VERSION ""

NS_ :

BS_:

BU_: TIMServer TIMClient

BO_ 2619670270 TIM21: 16 Vector__XXX
 SG_ RequestCounterAuxValve32 m32 : 8|4@1+ (1,0) [0|0] "" Vector__XXX
 SG_ RequestCounterAuxValve31 m31 : 8|4@1+ (1,0) [0|0] "" Vector__XXX
 SG_ RequestCounterAuxValve30 m30 : 8|4@1+ (1,0) [0|0] "" Vector__XXX
 SG_ RequestCounterAuxValve29 m29 : 8|4@1+ (1,0) [0|0] "" Vector__XXX
 SG_ RequestCounterAuxValve28 m28 : 8|4@1+ (1,0) [0|0] "" Vector__XXX
 SG_ RequestCounterAuxValve27 m27 : 8|4@1+ (1,0) [0|0] "" Vector__XXX
 SG_ RequestCounterAuxValve26 m26 : 8|4@1+ (1,0) [0|0] "" Vector__XXX
 SG_ RequestCounterAuxValve25 m25 : 8|4@1+ (1,0) [0|0] "" Vector__XXX
 SG_ RequestCounterAuxValve24 m24 : 8|4@1+ (1,0) [0|0] "" Vector__XXX
 SG_ RequestCounterAuxValve23 m23 : 8|4@1+ (1,0) [0|0] "" Vector__XXX
 SG_ RequestCounterAuxValve22 m22 : 8|4@1+ (1,0) [0|0] "" Vector__XXX
 SG_ RequestCounterAuxValve21 m21 : 8|4@1+ (1,0) [0|0] "" Vector__XXX
 SG_ RequestCounterAuxValve20 m20 : 8|4@1+ (1,0) [0|0] "" Vector__XXX
 SG_ RequestCounterAuxValve19 m19 : 8|4@1+ (1,0) [0|0] "" Vector__XXX
 SG_ RequestCounterAuxValve18 m18 : 8|4@1+ (1,0) [0|0] "" Vector__XXX
 SG_ RequestCounterAuxValve17 m17 : 8|4@1+ (1,0) [0|0] "" Vector__XXX
 SG_ RequestCounterAuxValve16 m16 : 8|4@1+ (1,0) [0|0] "" Vector__XXX
 SG_ RequestCounterAuxValve15 m15 : 8|4@1+ (1,0) [0|0] "" Vector__XXX
 SG_ RequestCounterAuxValve14 m14 : 8|4@1+ (1,0) [0|0] "" Vector__XXX
 SG_ RequestCounterAuxValve13 m13 : 8|4@1+ (1,0) [0|0] "" Vector__XXX
 SG_ RequestCounterAuxValve12 m12 : 8|4@1+ (1,0) [0|0] "" Vector__XXX
 SG_ RequestCounterAuxValve11 m11 : 8|4@1+ (1,0) [0|0] "" Vector__XXX
 SG_ RequestCounterAuxValve10 m10 : 8|4@1+ (1,0) [0|0] "" Vector__XXX
 SG_ RequestCounterAuxValve09 m9 : 8|4@1+ (1,0) [0|0] "" Vector__XXX
 SG_ RequestCounterAuxValve08 m8 : 8|4@1+ (1,0) [0|0] "" Vector__XXX
 SG_ RequestCounterAuxValve07 m7 : 8|4@1+ (1,0) [0|0] "" Vector__XXX
 SG_ RequestCounterAuxValve06 m6 : 8|4@1+ (1,0) [0|0] "" Vector__XXX
 SG_ RequestCounterAuxValve05 m5 : 8|4@1+ (1,0) [0|0] "" Vector__XXX
 SG_ RequestCounterAuxValve04 m4 : 8|4@1+ (1,0) [0|0] "" Vector__XXX
 SG_ RequestCounterAuxValve03 m3 : 8|4@1+ (1,0) [0|0] "" Vector__XXX
 SG_ RequestCounterAuxValve02 m2 : 8|4@1+ (1,0) [0|0] "" Vector__XXX
 SG_ RequestCounterAuxValve01 m1 : 8|4@1+ (1,0) [0|0] "" Vector__XXX
 SG_ RequestCounterVehicleSpeed m68 : 8|4@1+ (1,0) [0|0] "" Vector__XXX
 SG_ RequestCounterRearHitch m67 : 8|4@1+ (1,0) [0|0] "" Vector__XXX
 SG_ RequestCounterFrontHitch m66 : 8|4@1+ (1,0) [0|0] "" Vector__XXX
 SG_ RequestCounterRearPTO m65 : 8|4@1+ (1,0) [0|0] "" Vector__XXX
 SG_ RequestCounterFrontPTO m64 : 8|4@1+ (1,0) [0|0] "" Vector__XXX
 SG_ RequestCounterExternalGuidance m70 : 8|4@1+ (1,0) [0|0] "" Vector__XXX
 SG_ FlowRequest_AV32 m32 : 32|16@1+ (0.004,-128.512) [0|0] "%" Vector__XXX
 SG_ FlowRequest_AV31 m31 : 32|16@1+ (0.004,-128.512) [0|0] "%" Vector__XXX
 SG_ FlowRequest_AV30 m30 : 32|16@1+ (0.004,-128.512) [0|0] "%" Vector__XXX
 SG_ FlowRequest_AV29 m29 : 32|16@1+ (0.004,-128.512) [0|0] "%" Vector__XXX
 SG_ FlowRequest_AV28 m28 : 32|16@1+ (0.004,-128.512) [0|0] "%" Vector__XXX
 SG_ FlowRequest_AV27 m27 : 32|16@1+ (0.004,-128.512) [0|0] "%" Vector__XXX
 SG_ FlowRequest_AV26 m26 : 32|16@1+ (0.004,-128.512) [0|0] "%" Vector__XXX
 SG_ FlowRequest_AV25 m25 : 32|16@1+ (0.004,-128.512) [0|0] "%" Vector__XXX
 SG_ FlowRequest_AV24 m24 : 32|16@1+ (0.004,-128.512) [0|0] "%" Vector__XXX
 SG_ FlowRequest_AV23 m23 : 32|16@1+ (0.004,-128.512) [0|0] "%" Vector__XXX
 SG_ FlowRequest_AV22 m22 : 32|16@1+ (0.004,-128.512) [0|0] "%" Vector__XXX
 SG_ FlowRequest_AV21 m21 : 32|16@1+ (0.004,-128.512) [0|0] "%" Vector__XXX
 SG_ FlowRequest_AV20 m20 : 32|16@1+ (0.004,-128.512) [0|0] "%" Vector__XXX
 SG_ FlowRequest_AV19 m19 : 32|16@1+ (0.004,-128.512) [0|0] "%" Vector__XXX
 SG_ FlowRequest_AV18 m18 : 32|16@1+ (0.004,-128.512) [0|0] "%" Vector__XXX
 SG_ FlowRequest_AV17 m17 : 32|16@1+ (0.004,-128.512) [0|0] "%" Vector__XXX
 SG_ FlowRequest_AV16 m16 : 32|16@1+ (0.004,-128.512) [0|0] "%" Vector__XXX
 SG_ FlowRequest_AV15 m15 : 32|16@1+ (0.004,-128.512) [0|0] "%" Vector__XXX
 SG_ FlowRequest_AV14 m14 : 32|16@1+ (0.004,-128.512) [0|0] "%" Vector__XXX
 SG_ FlowRequest_AV13 m13 : 32|16@1+ (0.004,-128.512) [0|0] "%" Vector__XXX
 SG_ FlowRequest_AV12 m12 : 32|16@1+ (0.004,-128.512) [0|0] "%" Vector__XXX
 SG_ FlowRequest_AV11 m11 : 32|16@1+ (0.004,-128.512) [0|0] "%" Vector__XXX
 SG_ FlowRequest_AV10 m10 : 32|16@1+ (0.004,-128.512) [0|0] "%" Vector__XXX
 SG_ FlowRequest_AV09 m9 : 32|16@1+ (0.004,-128.512) [0|0] "%" Vector__XXX
 SG_ FlowRequest_AV08 m8 : 32|16@1+ (0.004,-128.512) [0|0] "%" Vector__XXX
 SG_ FlowRequest_AV07 m7 : 32|16@1+ (0.004,-128.512) [0|0] "%" Vector__XXX
 SG_ FlowRequest_AV06 m6 : 32|16@1+ (0.004,-128.512) [0|0] "%" Vector__XXX
 SG_ FlowRequest_AV05 m5 : 32|16@1+ (0.004,-128.512) [0|0] "%" Vector__XXX
 SG_ FlowRequest_AV04 m4 : 32|16@1+ (0.004,-128.512) [0|0] "%" Vector__XXX
 SG_ FlowRequest_AV03 m3 : 32|16@1+ (0.004,-128.512) [0|0] "%" Vector__XXX
 SG_ FlowRequest_AV02 m2 : 32|16@1+ (0.004,-128.512) [0|0] "%" Vector__XXX
 SG_ RearHitchPosRequest m67 : 32|16@1+ (0.01,0) [0|100] "%" Vector__XXX
 SG_ RearPTOSpeedRequest m65 : 32|16@1+ (0.125,-4016) [0|0] "1/min" Vector__XXX
 SG_ MinimumTIMVersion_Resp m247 : 24|8@1+ (1,0) [0|0] "" Vector__XXX
 SG_ ImplementedTIMVersion_Resp m247 : 16|8@1+ (1,0) [0|0] "" Vector__XXX
 SG_ CurvatureRequest m70 : 32|16@1+ (0.25,-8032) [-8032|8031.75] "1/km" Vector__XXX
 SG_ VehicleSpeedRequest m68 : 32|16@1+ (0.001,-32.128) [-32.127|32.127] "m/s" Vector__XXX
 SG_ FrontHitchPosRequest m66 : 32|16@1+ (0.01,0) [0|100] "%" Vector__XXX
 SG_ FrontPTOSpeedRequest m64 : 32|16@1+ (0.125,-4016) [0|0] "1/min" Vector__XXX
 SG_ FlowRequest_AV01 m1 : 32|16@1+ (0.004,-128.512) [0|0] "%" Vector__XXX
 SG_ TIMClientState m249 : 20|4@1+ (1,0) [0|0] "" Vector__XXX
 SG_ ClientHeartbeatCounter m249 : 8|8@1+ (1,0) [0|0] "" Vector__XXX
 SG_ TIMFunctionId_4 m245 : 64|8@1+ (1,0) [0|0] "" Vector__XXX
 SG_ TIMFunctionId_3 m245 : 48|8@1+ (1,0) [0|0] "" Vector__XXX
 SG_ TIMFunctionId_2 m245 : 32|8@1+ (1,0) [0|0] "" Vector__XXX
 SG_ TIMFunctionId_1 m245 : 16|8@1+ (1,0) [0|0] "" Vector__XXX
 SG_ NumOfTIMFunctions m245 : 8|8@1+ (1,0) [1|250] "" Vector__XXX
 SG_ RequestType_4 m245 : 77|3@1+ (1,0) [0|0] "" Vector__XXX
 SG_ RequestType_3 m245 : 61|3@1+ (1,0) [0|0] "" Vector__XXX
 SG_ RequestType_2 m245 : 45|3@1+ (1,0) [0|0] "" Vector__XXX
 SG_ RequestType_1 m245 : 29|3@1+ (1,0) [0|0] "" Vector__XXX
 SG_ MinimumTIMVersion_Req m246 : 24|8@1+ (1,0) [0|0] "" Vector__XXX
 SG_ ImplementedTIMVersion_Req m246 : 16|8@1+ (1,0) [0|0] "" Vector__XXX
 SG_ TIMMessageType m1 : 12|4@1+ (1,0) [0|0] "" Vector__XXX
 SG_ GroupFunctionValue M : 0|8@1+ (1,0) [0|0] "" Vector__XXX

BO_ 2619604734 TIM12: 16 Vector__XXX
 SG_ GroupFunctionValue M : 0|8@1+ (1,0) [0|0] "" Vector__XXX
 SG_ RearHitchPosition m67 : 32|16@1+ (0.01,0) [0|100] "%" Vector__XXX
 SG_ RearPTOSpeed m65 : 32|16@1+ (0.125,-4016) [0|0] "1/min" Vector__XXX
 SG_ FlowAuxValve32 m32 : 32|16@1+ (0.004,-128.512) [0|0] "%" Vector__XXX
 SG_ FlowAuxValve31 m31 : 32|16@1+ (0.004,-128.512) [0|0] "%" Vector__XXX
 SG_ FlowAuxValve30 m30 : 32|16@1+ (0.004,-128.512) [0|0] "%" Vector__XXX
 SG_ FlowAuxValve29 m29 : 32|16@1+ (0.004,-128.512) [0|0] "%" Vector__XXX
 SG_ FlowAuxValve28 m28 : 32|16@1+ (0.004,-128.512) [0|0] "%" Vector__XXX
 SG_ FlowAuxValve27 m27 : 32|16@1+ (0.004,-128.512) [0|0] "%" Vector__XXX
 SG_ FlowAuxValve26 m26 : 32|16@1+ (0.004,-128.512) [0|0] "%" Vector__XXX
 SG_ FlowAuxValve25 m25 : 32|16@1+ (0.004,-128.512) [0|0] "%" Vector__XXX
 SG_ FlowAuxValve24 m24 : 32|16@1+ (0.004,-128.512) [0|0] "%" Vector__XXX
 SG_ FlowAuxValve23 m23 : 32|16@1+ (0.004,-128.512) [0|0] "%" Vector__XXX
 SG_ FlowAuxValve22 m22 : 32|16@1+ (0.004,-128.512) [0|0] "%" Vector__XXX
 SG_ FlowAuxValve21 m21 : 32|16@1+ (0.004,-128.512) [0|0] "%" Vector__XXX
 SG_ FlowAuxValve20 m20 : 32|16@1+ (0.004,-128.512) [0|0] "%" Vector__XXX
 SG_ FlowAuxValve19 m19 : 32|16@1+ (0.004,-128.512) [0|0] "%" Vector__XXX
 SG_ FlowAuxValve18 m18 : 32|16@1+ (0.004,-128.512) [0|0] "%" Vector__XXX
 SG_ FlowAuxValve17 m17 : 32|16@1+ (0.004,-128.512) [0|0] "%" Vector__XXX
 SG_ FlowAuxValve16 m16 : 32|16@1+ (0.004,-128.512) [0|0] "%" Vector__XXX
 SG_ FlowAuxValve15 m15 : 32|16@1+ (0.004,-128.512) [0|0] "%" Vector__XXX
 SG_ FlowAuxValve14 m14 : 32|16@1+ (0.004,-128.512) [0|0] "%" Vector__XXX
 SG_ FlowAuxValve13 m13 : 32|16@1+ (0.004,-128.512) [0|0] "%" Vector__XXX
 SG_ FlowAuxValve12 m12 : 32|16@1+ (0.004,-128.512) [0|0] "%" Vector__XXX
 SG_ FlowAuxValve11 m11 : 32|16@1+ (0.004,-128.512) [0|0] "%" Vector__XXX
 SG_ FlowAuxValve10 m10 : 32|16@1+ (0.004,-128.512) [0|0] "%" Vector__XXX
 SG_ FlowAuxValve09 m9 : 32|16@1+ (0.004,-128.512) [0|0] "%" Vector__XXX
 SG_ FlowAuxValve08 m8 : 32|16@1+ (0.004,-128.512) [0|0] "%" Vector__XXX
 SG_ FlowAuxValve07 m7 : 32|16@1+ (0.004,-128.512) [0|0] "%" Vector__XXX
 SG_ FlowAuxValve06 m6 : 32|16@1+ (0.004,-128.512) [0|0] "%" Vector__XXX
 SG_ FlowAuxValve05 m5 : 32|16@1+ (0.004,-128.512) [0|0] "%" Vector__XXX
 SG_ FlowAuxValve04 m4 : 32|16@1+ (0.004,-128.512) [0|0] "%" Vector__XXX
 SG_ FlowAuxValve03 m3 : 32|16@1+ (0.004,-128.512) [0|0] "%" Vector__XXX
 SG_ FlowAuxValve02 m2 : 32|16@1+ (0.004,-128.512) [0|0] "%" Vector__XXX
 SG_ FlowTypeAuxValve32 m32 : 24|2@1+ (1,0) [0|0] "" Vector__XXX
 SG_ FlowTypeAuxValve31 m31 : 24|2@1+ (1,0) [0|0] "" Vector__XXX
 SG_ FlowTypeAuxValve30 m30 : 24|2@1+ (1,0) [0|0] "" Vector__XXX
 SG_ FlowTypeAuxValve29 m29 : 24|2@1+ (1,0) [0|0] "" Vector__XXX
 SG_ FlowTypeAuxValve28 m28 : 24|2@1+ (1,0) [0|0] "" Vector__XXX
 SG_ FlowTypeAuxValve27 m27 : 24|2@1+ (1,0) [0|0] "" Vector__XXX
 SG_ FlowTypeAuxValve26 m26 : 24|2@1+ (1,0) [0|0] "" Vector__XXX
 SG_ FlowTypeAuxValve25 m25 : 24|2@1+ (1,0) [0|0] "" Vector__XXX
 SG_ FlowTypeAuxValve24 m24 : 24|2@1+ (1,0) [0|0] "" Vector__XXX
 SG_ FlowTypeAuxValve23 m23 : 24|2@1+ (1,0) [0|0] "" Vector__XXX
 SG_ FlowTypeAuxValve22 m22 : 24|2@1+ (1,0) [0|0] "" Vector__XXX
 SG_ FlowTypeAuxValve21 m21 : 24|2@1+ (1,0) [0|0] "" Vector__XXX
 SG_ FlowTypeAuxValve20 m20 : 24|2@1+ (1,0) [0|0] "" Vector__XXX
 SG_ FlowTypeAuxValve19 m19 : 24|2@1+ (1,0) [0|0] "" Vector__XXX
 SG_ FlowTypeAuxValve18 m18 : 24|2@1+ (1,0) [0|0] "" Vector__XXX
 SG_ FlowTypeAuxValve17 m17 : 24|2@1+ (1,0) [0|0] "" Vector__XXX
 SG_ FlowTypeAuxValve16 m16 : 24|2@1+ (1,0) [0|0] "" Vector__XXX
 SG_ FlowTypeAuxValve15 m15 : 24|2@1+ (1,0) [0|0] "" Vector__XXX
 SG_ FlowTypeAuxValve14 m14 : 24|2@1+ (1,0) [0|0] "" Vector__XXX
 SG_ FlowTypeAuxValve13 m13 : 24|2@1+ (1,0) [0|0] "" Vector__XXX
 SG_ FlowTypeAuxValve12 m12 : 24|2@1+ (1,0) [0|0] "" Vector__XXX
 SG_ FlowTypeAuxValve11 m11 : 24|2@1+ (1,0) [0|0] "" Vector__XXX
 SG_ FlowTypeAuxValve10 m10 : 24|2@1+ (1,0) [0|0] "" Vector__XXX
 SG_ FlowTypeAuxValve09 m9 : 24|2@1+ (1,0) [0|0] "" Vector__XXX
 SG_ FlowTypeAuxValve08 m8 : 24|2@1+ (1,0) [0|0] "" Vector__XXX
 SG_ FlowTypeAuxValve07 m7 : 24|2@1+ (1,0) [0|0] "" Vector__XXX
 SG_ FlowTypeAuxValve06 m6 : 24|2@1+ (1,0) [0|0] "" Vector__XXX
 SG_ FlowTypeAuxValve05 m5 : 24|2@1+ (1,0) [0|0] "" Vector__XXX
 SG_ FlowTypeAuxValve04 m4 : 24|2@1+ (1,0) [0|0] "" Vector__XXX
 SG_ FlowTypeAuxValve03 m3 : 24|2@1+ (1,0) [0|0] "" Vector__XXX
 SG_ FlowTypeAuxValve02 m2 : 24|2@1+ (1,0) [0|0] "" Vector__XXX
 SG_ FlowTypeAuxValve01 m1 : 24|2@1+ (1,0) [0|0] "" Vector__XXX
 SG_ ExitReasonCodeRearPTO m65 : 27|5@1+ (1,0) [0|0] "" Vector__XXX
 SG_ ExitReasonCodeRearHitch m67 : 27|5@1+ (1,0) [0|0] "" Vector__XXX
 SG_ ExitReasonCodeAuxValve32 m32 : 27|5@1+ (1,0) [0|0] "" Vector__XXX
 SG_ ExitReasonCodeAuxValve31 m31 : 27|5@1+ (1,0) [0|0] "" Vector__XXX
 SG_ ExitReasonCodeAuxValve30 m30 : 27|5@1+ (1,0) [0|0] "" Vector__XXX
 SG_ ExitReasonCodeAuxValve29 m29 : 27|5@1+ (1,0) [0|0] "" Vector__XXX
 SG_ ExitReasonCodeAuxValve28 m28 : 27|5@1+ (1,0) [0|0] "" Vector__XXX
 SG_ ExitReasonCodeAuxValve27 m27 : 27|5@1+ (1,0) [0|0] "" Vector__XXX
 SG_ ExitReasonCodeAuxValve26 m26 : 27|5@1+ (1,0) [0|0] "" Vector__XXX
 SG_ ExitReasonCodeAuxValve25 m25 : 27|5@1+ (1,0) [0|0] "" Vector__XXX
 SG_ ExitReasonCodeAuxValve24 m24 : 27|5@1+ (1,0) [0|0] "" Vector__XXX
 SG_ ExitReasonCodeAuxValve23 m23 : 27|5@1+ (1,0) [0|0] "" Vector__XXX
 SG_ ExitReasonCodeAuxValve22 m22 : 27|5@1+ (1,0) [0|0] "" Vector__XXX
 SG_ ExitReasonCodeAuxValve21 m21 : 27|5@1+ (1,0) [0|0] "" Vector__XXX
 SG_ ExitReasonCodeAuxValve20 m20 : 27|5@1+ (1,0) [0|0] "" Vector__XXX
 SG_ ExitReasonCodeAuxValve19 m19 : 27|5@1+ (1,0) [0|0] "" Vector__XXX
 SG_ ExitReasonCodeAuxValve18 m18 : 27|5@1+ (1,0) [0|0] "" Vector__XXX
 SG_ ExitReasonCodeAuxValve17 m17 : 27|5@1+ (1,0) [0|0] "" Vector__XXX
 SG_ ExitReasonCodeAuxValve16 m16 : 27|5@1+ (1,0) [0|0] "" Vector__XXX
 SG_ ExitReasonCodeAuxValve15 m15 : 27|5@1+ (1,0) [0|0] "" Vector__XXX
 SG_ ExitReasonCodeAuxValve14 m14 : 27|5@1+ (1,0) [0|0] "" Vector__XXX
 SG_ ExitReasonCodeAuxValve13 m13 : 27|5@1+ (1,0) [0|0] "" Vector__XXX
 SG_ ExitReasonCodeAuxValve12 m12 : 27|5@1+ (1,0) [0|0] "" Vector__XXX
 SG_ ExitReasonCodeAuxValve11 m11 : 27|5@1+ (1,0) [0|0] "" Vector__XXX
 SG_ ExitReasonCodeAuxValve10 m10 : 27|5@1+ (1,0) [0|0] "" Vector__XXX
 SG_ ExitReasonCodeAuxValve09 m9 : 27|5@1+ (1,0) [0|0] "" Vector__XXX
 SG_ ExitReasonCodeAuxValve08 m8 : 27|5@1+ (1,0) [0|0] "" Vector__XXX
 SG_ ExitReasonCodeAuxValve07 m7 : 27|5@1+ (1,0) [0|0] "" Vector__XXX
 SG_ ExitReasonCodeAuxValve06 m6 : 27|5@1+ (1,0) [0|0] "" Vector__XXX
 SG_ ExitReasonCodeAuxValve05 m5 : 27|5@1+ (1,0) [0|0] "" Vector__XXX
 SG_ ExitReasonCodeAuxValve04 m4 : 27|5@1+ (1,0) [0|0] "" Vector__XXX
 SG_ ExitReasonCodeAuxValve03 m3 : 27|5@1+ (1,0) [0|0] "" Vector__XXX
 SG_ ExitReasonCodeAuxValve02 m2 : 27|5@1+ (1,0) [0|0] "" Vector__XXX
 SG_ AutomationStatusAuxValve04 m4 : 16|4@1+ (1,0) [0|0] "" Vector__XXX
 SG_ AutomationStatusAuxValve03 m3 : 16|4@1+ (1,0) [0|0] "" Vector__XXX
 SG_ AutomationStatusAuxValve02 m2 : 16|4@1+ (1,0) [0|0] "" Vector__XXX
 SG_ AutomationStatusAuxValve01 m1 : 16|4@1+ (1,0) [0|0] "" Vector__XXX
 SG_ AutomationStatusExternalGuidance m70 : 16|4@1+ (1,0) [0|0] "" Vector__XXX
 SG_ AutomationStatusVehicleSpeed m68 : 16|4@1+ (1,0) [0|0] "" Vector__XXX
 SG_ AutomationStatusRearHitch m67 : 16|4@1+ (1,0) [0|0] "" Vector__XXX
 SG_ AutomationStatusFrontHitch m66 : 16|4@1+ (1,0) [0|0] "" Vector__XXX
 SG_ AutomationStatusRearPTO m65 : 16|4@1+ (1,0) [0|0] "" Vector__XXX
 SG_ AutomationStatusFrontPTO m64 : 16|4@1+ (1,0) [0|0] "" Vector__XXX
 SG_ AutomationStatusAuxValve32 m32 : 16|4@1+ (1,0) [0|0] "" Vector__XXX
 SG_ AutomationStatusAuxValve31 m31 : 16|4@1+ (1,0) [0|0] "" Vector__XXX
 SG_ AutomationStatusAuxValve30 m30 : 16|4@1+ (1,0) [0|0] "" Vector__XXX
 SG_ AutomationStatusAuxValve29 m29 : 16|4@1+ (1,0) [0|0] "" Vector__XXX
 SG_ AutomationStatusAuxValve28 m28 : 16|4@1+ (1,0) [0|0] "" Vector__XXX
 SG_ AutomationStatusAuxValve27 m27 : 16|4@1+ (1,0) [0|0] "" Vector__XXX
 SG_ AutomationStatusAuxValve26 m26 : 16|4@1+ (1,0) [0|0] "" Vector__XXX
 SG_ AutomationStatusAuxValve25 m25 : 16|4@1+ (1,0) [0|0] "" Vector__XXX
 SG_ AutomationStatusAuxValve24 m24 : 16|4@1+ (1,0) [0|0] "" Vector__XXX
 SG_ AutomationStatusAuxValve23 m23 : 16|4@1+ (1,0) [0|0] "" Vector__XXX
 SG_ AutomationStatusAuxValve22 m22 : 16|4@1+ (1,0) [0|0] "" Vector__XXX
 SG_ AutomationStatusAuxValve21 m21 : 16|4@1+ (1,0) [0|0] "" Vector__XXX
 SG_ AutomationStatusAuxValve20 m20 : 16|4@1+ (1,0) [0|0] "" Vector__XXX
 SG_ AutomationStatusAuxValve19 m19 : 16|4@1+ (1,0) [0|0] "" Vector__XXX
 SG_ AutomationStatusAuxValve18 m18 : 16|4@1+ (1,0) [0|0] "" Vector__XXX
 SG_ AutomationStatusAuxValve17 m17 : 16|4@1+ (1,0) [0|0] "" Vector__XXX
 SG_ AutomationStatusAuxValve16 m16 : 16|4@1+ (1,0) [0|0] "" Vector__XXX
 SG_ AutomationStatusAuxValve15 m15 : 16|4@1+ (1,0) [0|0] "" Vector__XXX
 SG_ AutomationStatusAuxValve14 m14 : 16|4@1+ (1,0) [0|0] "" Vector__XXX
 SG_ AutomationStatusAuxValve13 m13 : 16|4@1+ (1,0) [0|0] "" Vector__XXX
 SG_ AutomationStatusAuxValve12 m12 : 16|4@1+ (1,0) [0|0] "" Vector__XXX
 SG_ AutomationStatusAuxValve11 m11 : 16|4@1+ (1,0) [0|0] "" Vector__XXX
 SG_ AutomationStatusAuxValve10 m10 : 16|4@1+ (1,0) [0|0] "" Vector__XXX
 SG_ AutomationStatusAuxValve09 m9 : 16|4@1+ (1,0) [0|0] "" Vector__XXX
 SG_ AutomationStatusAuxValve08 m8 : 16|4@1+ (1,0) [0|0] "" Vector__XXX
 SG_ AutomationStatusAuxValve07 m7 : 16|4@1+ (1,0) [0|0] "" Vector__XXX
 SG_ AutomationStatusAuxValve06 m6 : 16|4@1+ (1,0) [0|0] "" Vector__XXX
 SG_ AutomationStatusAuxValve05 m5 : 16|4@1+ (1,0) [0|0] "" Vector__XXX
 SG_ NumOfUnassignedServerFcts m243 : 8|8@1+ (1,0) [0|255] "" Vector__XXX
 SG_ Curvature m70 : 32|16@1+ (0.25,-8032) [-8032|8031.75] "1/km" Vector__XXX
 SG_ ExitReasonCodeExternalGuidance m70 : 27|5@1+ (1,0) [0|0] "" Vector__XXX
 SG_ VehicleSpeed m68 : 32|16@1+ (0.001,-32.128) [-32.127|32.127] "m/s" Vector__XXX
 SG_ ExitReasonCodeVehicleSpeed m68 : 27|5@1+ (1,0) [0|0] "" Vector__XXX
 SG_ FrontHitchPosition m66 : 32|16@1+ (0.01,0) [0|100] "%" Vector__XXX
 SG_ ExitReasonCodeFrontHitch m66 : 27|5@1+ (1,0) [0|0] "" Vector__XXX
 SG_ FrontPTOSpeed m64 : 32|16@1+ (0.125,-4016) [0|0] "1/min" Vector__XXX
 SG_ ExitReasonCodeFrontPTO m64 : 27|5@1+ (1,0) [0|0] "" Vector__XXX
 SG_ FlowAuxValve01 m1 : 32|16@1+ (0.004,-128.512) [0|0] "%" Vector__XXX
 SG_ ReflectedRequestCounter m1 : 8|4@1+ (1,0) [0|0] "" Vector__XXX
 SG_ ExitReasonCodeAuxValve01 m1 : 27|5@1+ (1,0) [0|0] "" Vector__XXX
 SG_ TIMSystemOperationState m250 : 24|4@1+ (1,0) [0|15] "" Vector__XXX
 SG_ TIMServerState m250 : 28|4@1+ (1,0) [0|0] "" Vector__XXX
 SG_ TIMSystemState m250 : 16|4@1+ (1,0) [0|0] "" Vector__XXX
 SG_ LeadTIMServerIndication m250 : 20|4@1+ (1,0) [0|0] "" Vector__XXX
 SG_ ServerHeartbeatCounter m250 : 8|8@1+ (1,0) [0|0] "" Vector__XXX
 SG_ AssignmentResult_4 m245 : 77|3@1+ (1,0) [0|0] "" Vector__XXX
 SG_ AssignmentResult_3 m245 : 61|3@1+ (1,0) [0|0] "" Vector__XXX
 SG_ AssignmentResult_2 m245 : 45|3@1+ (1,0) [0|0] "" Vector__XXX
 SG_ AssignmentErrorReason_4 m245 : 72|5@1+ (1,0) [0|0] "" Vector__XXX
 SG_ AssignmentErrorReason_3 m245 : 56|5@1+ (1,0) [0|0] "" Vector__XXX
 SG_ AssignmentErrorReason_2 m245 : 40|5@1+ (1,0) [0|0] "" Vector__XXX
 SG_ AssignmentErrorReason_1 m245 : 24|5@1+ (1,0) [0|0] "" Vector__XXX
 SG_ AssignmentResult_1 m245 : 29|3@1+ (1,0) [0|0] "" Vector__XXX
 SG_ TIMFunctionId_4 m245 : 64|8@1+ (1,0) [0|0] "" Vector__XXX
 SG_ TIMFunctionId_3 m245 : 48|8@1+ (1,0) [0|0] "" Vector__XXX
 SG_ TIMFunctionId_2 m245 : 32|8@1+ (1,0) [0|0] "" Vector__XXX
 SG_ TIMFunctionId_1 m245 : 16|8@1+ (1,0) [0|0] "" Vector__XXX
 SG_ NumOfTIMFunctions m245 : 8|8@1+ (1,0) [1|250] "" Vector__XXX
 SG_ NumOfSupportedTIMFunctions m244 : 8|8@1+ (1,0) [1|250] "" Vector__XXX
 SG_ TIMConnectionVersion m246 : 16|8@1+ (1,0) [0|0] "" Vector__XXX
 SG_ ErrorCode m246 : 8|8@1+ (1,0) [0|0] "" Vector__XXX
 SG_ MinimumTIMVersionNr m248 : 24|8@1+ (1,0) [0|0] "" Vector__XXX
 SG_ ImplementedTIMVersionNr m248 : 16|8@1+ (1,0) [0|0] "" Vector__XXX
 SG_ BootTime m248 : 8|8@1+ (1,0) [0|0] "" Vector__XXX
 SG_ TIMMessageType m1 : 12|4@1+ (1,0) [0|0] "" Vector__XXX

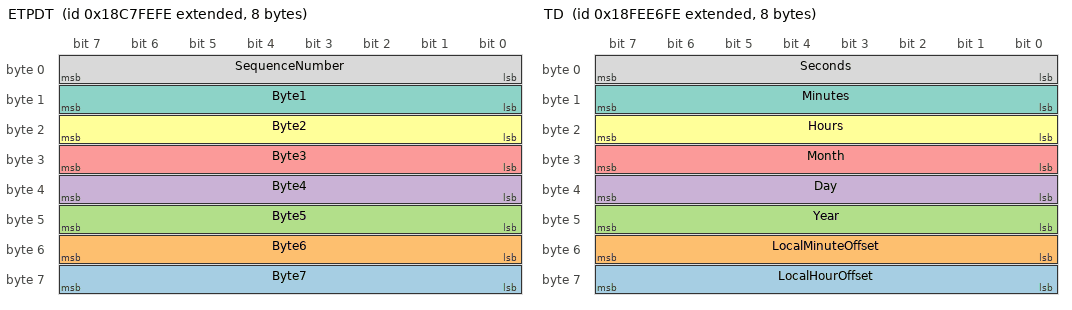
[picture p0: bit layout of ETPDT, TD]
BO_ 2563243774 ETPDT: 8 Vector__XXX
 SG_ Byte7 : 56|8@1+ (1,0) [0|255] "" Vector__XXX
 SG_ Byte6 : 48|8@1+ (1,0) [0|255] "" Vector__XXX
 SG_ Byte5 : 40|8@1+ (1,0) [0|255] "" Vector__XXX
 SG_ Byte4 : 32|8@1+ (1,0) [0|255] "" Vector__XXX
 SG_ Byte3 : 24|8@1+ (1,0) [0|255] "" Vector__XXX
 SG_ Byte2 : 16|8@1+ (1,0) [0|255] "" Vector__XXX
 SG_ Byte1 : 8|8@1+ (1,0) [0|255] "" Vector__XXX
 SG_ SequenceNumber : 0|8@1+ (1,0) [1|255] "" Vector__XXX

BO_ 2563309310 ETPCM: 8 Vector__XXX
 SG_ PGNumber : 40|24@1+ (1,0) [0|16777200] "" Vector__XXX
 SG_ DataPacketOffset m22 : 16|24@1+ (1,0) [0|16777215] "" Vector__XXX
 SG_ NextPacketNumberToSend m21 : 16|24@1+ (1,0) [1|16777215] "" Vector__XXX
 SG_ NumberOfBytesTransfered m23 : 8|32@1+ (1,0) [1786|117440505] "" Vector__XXX
 SG_ NumberOfPacketsOffset m22 : 8|8@1+ (1,0) [1|255] "" Vector__XXX
 SG_ NumberOfPacketsToSend m21 : 8|8@1+ (1,0) [1|255] "" Vector__XXX
 SG_ NumberOfBytesToTransfer m20 : 8|32@1+ (1,0) [1786|117440505] "" Vector__XXX
 SG_ ControlByte M : 0|8@1+ (1,0) [0|255] "" Vector__XXX
 SG_ ConnectionAbortReason m255 : 8|8@1+ (1,0) [0|255] "" Vector__XXX

BO_ 2566842110 TD: 8 Vector__XXX
 SG_ LocalHourOffset : 56|8@1+ (1,-125) [-125|125] "hr" Vector__XXX
 SG_ LocalMinuteOffset : 48|8@1+ (1,-125) [-125|125] "mins" Vector__XXX
 SG_ Year : 40|8@1+ (1,1985) [1985|2235] "years" Vector__XXX
 SG_ Day : 32|8@1+ (0.25,0) [0|62.5] "days" Vector__XXX
 SG_ Month : 24|8@1+ (1,0) [0|250] "months" Vector__XXX
 SG_ Hours : 16|8@1+ (1,0) [0|250] "hr" Vector__XXX
 SG_ Minutes : 8|8@1+ (1,0) [0|250] "mins" Vector__XXX
 SG_ Seconds : 0|8@1+ (0.25,0) [0|62.5] "s" Vector__XXX

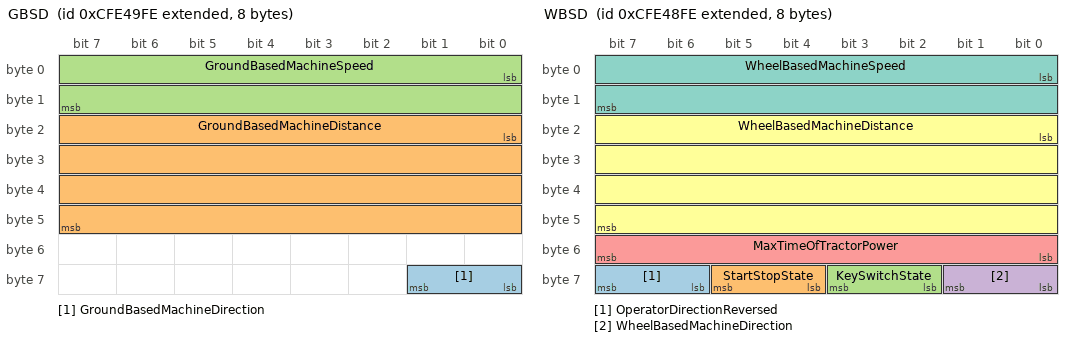
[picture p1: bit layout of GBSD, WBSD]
BO_ 2365475326 GBSD: 8 Vector__XXX
 SG_ GroundBasedMachineDirection : 56|2@1+ (1,0) [0|3] "" Vector__XXX
 SG_ GroundBasedMachineDistance : 16|32@1+ (0.001,0) [0|4211080] "m" Vector__XXX
 SG_ GroundBasedMachineSpeed : 0|16@1+ (0.001,0) [0|64.255] "m/s" Vector__XXX

BO_ 2365475070 WBSD: 8 Vector__XXX
 SG_ OperatorDirectionReversed : 62|2@1+ (1,0) [0|3] "" Vector__XXX
 SG_ StartStopState : 60|2@1+ (1,0) [0|4] "" Vector__XXX
 SG_ KeySwitchState : 58|2@1+ (1,0) [0|3] "" Vector__XXX
 SG_ WheelBasedMachineDirection : 56|2@1+ (1,0) [0|3] "" Vector__XXX
 SG_ MaxTimeOfTractorPower : 48|8@1+ (1,0) [0|250] "min" Vector__XXX
 SG_ WheelBasedMachineDistance : 16|32@1+ (0.001,0) [0|4211081.215] "m" Vector__XXX
 SG_ WheelBasedMachineSpeed : 0|16@1+ (0.001,0) [0|64.255] "m/s" Vector__XXX

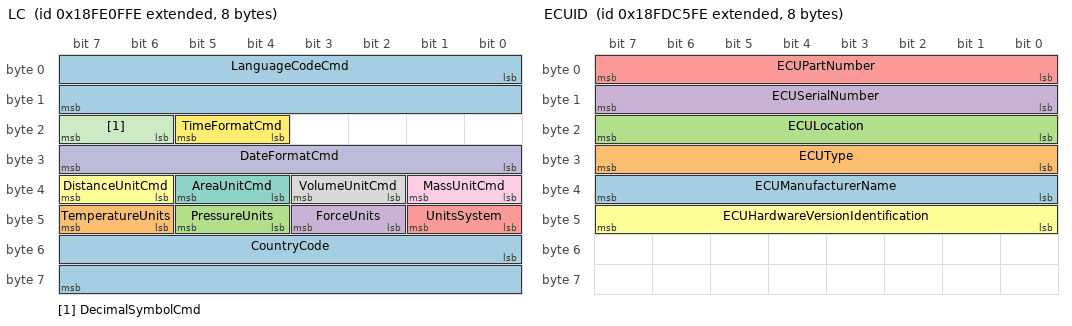
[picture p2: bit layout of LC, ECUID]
BO_ 2566787070 LC: 8 Vector__XXX
 SG_ CountryCode : 48|16@1+ (1,0) [0|65535] "" Vector__XXX
 SG_ TemperatureUnits : 46|2@1+ (1,0) [0|3] "" Vector__XXX
 SG_ PressureUnits : 44|2@1+ (1,0) [0|3] "" Vector__XXX
 SG_ ForceUnits : 42|2@1+ (1,0) [0|3] "" Vector__XXX
 SG_ UnitsSystem : 40|2@1+ (1,0) [0|3] "" Vector__XXX
 SG_ DistanceUnitCmd : 38|2@1+ (1,0) [0|3] "" Vector__XXX
 SG_ AreaUnitCmd : 36|2@1+ (1,0) [0|3] "" Vector__XXX
 SG_ VolumeUnitCmd : 34|2@1+ (1,0) [0|3] "" Vector__XXX
 SG_ MassUnitCmd : 32|2@1+ (1,0) [0|3] "" Vector__XXX
 SG_ DateFormatCmd : 24|8@1+ (1,0) [0|255] "" Vector__XXX
 SG_ DecimalSymbolCmd : 22|2@1+ (1,0) [0|3] "" Vector__XXX
 SG_ TimeFormatCmd : 20|2@1+ (1,0) [0|3] "" Vector__XXX
 SG_ LanguageCodeCmd : 0|16@1+ (1,0) [0|16383] "" Vector__XXX

BO_ 2632777470 TPCM: 8 Vector__XXX
 SG_ PGNumber : 40|24@1+ (1,0) [0|16777200] "" Vector__XXX
 SG_ MaximumNumberOfPackets m16 : 32|8@1+ (1,0) [0|255] "" Vector__XXX
 SG_ TotalNumberOfPackets m16 : 24|8@1+ (1,0) [0|255] "" Vector__XXX
 SG_ TotalNumberOfPacketsBAM m32 : 24|8@1+ (1,0) [0|255] "" Vector__XXX
 SG_ TotalNumberOfPacketsEoMA m19 : 24|8@1+ (1,0) [0|255] "" Vector__XXX
 SG_ NextPacketNumberToBeSent m17 : 16|8@1+ (1,0) [0|255] "" Vector__XXX
 SG_ ConnectionAbortReason m255 : 8|8@1+ (1,0) [0|255] "" Vector__XXX
 SG_ NumberOfPacketsThatCanBeSent m17 : 8|8@1+ (1,0) [0|255] "" Vector__XXX
 SG_ TotalMessageSize m16 : 8|16@1+ (1,0) [0|64255] "counts" Vector__XXX
 SG_ TotalMessageSizeBAM m32 : 8|16@1+ (1,0) [0|64255] "counts" Vector__XXX
 SG_ TotalMessageSizeEoMA m19 : 8|16@1+ (1,0) [0|64255] "counts" Vector__XXX
 SG_ ControlByte M : 0|8@1+ (1,0) [0|255] "" Vector__XXX

BO_ 2632711934 TPDT: 8 Vector__XXX
 SG_ SequenceNumber : 0|8@1+ (1,0) [0|255] "" Vector__XXX

BO_ 2565537534 RQST: 3 Vector__XXX
 SG_ ParameterGroupNumber : 0|24@1+ (1,0) [0|16777215] "" Vector__XXX

BO_ 2565406462 ACKM: 8 Vector__XXX
 SG_ ParameterGroupNumber : 40|24@1+ (1,0) [0|16777215] "" Vector__XXX
 SG_ AddressBusy m3 : 32|8@1+ (1,0) [0|255] "" Vector__XXX
 SG_ AddressAccessDenied m2 : 32|8@1+ (1,0) [0|255] "" Vector__XXX
 SG_ AddressNegativeAcknowledgement m1 : 32|8@1+ (1,0) [0|255] "" Vector__XXX
 SG_ AddressAcknowledged m0 : 32|8@1+ (1,0) [0|255] "" Vector__XXX
 SG_ GroupFunctionValue : 8|8@1+ (1,0) [0|255] "" Vector__XXX
 SG_ ControlByte M : 0|8@1+ (1,0) [0|255] "" Vector__XXX

BO_ 2565799678 AC: 8 Vector__XXX
 SG_ ReservedBit : 48|1@1+ (1,0) [0|0] "" Vector__XXX
 SG_ ArbitraryAddressCapable : 63|1@1+ (1,0) [0|1] "" Vector__XXX
 SG_ IndustryGroup M : 60|3@1+ (1,0) [0|7] "" Vector__XXX
 SG_ VehicleSystemInstance : 56|4@1+ (1,0) [0|15] "" Vector__XXX
 SG_ VehicleSystem m0 : 49|7@1+ (1,0) [0|127] "" Vector__XXX
 SG_ VehicleSystem5 m5 : 49|7@1+ (1,0) [0|127] "" Vector__XXX
 SG_ VehicleSystem4 m4 : 49|7@1+ (1,0) [0|127] "" Vector__XXX
 SG_ VehicleSystem3 m3 : 49|7@1+ (1,0) [0|127] "" Vector__XXX
 SG_ VehicleSystem2 m2 : 49|7@1+ (1,0) [0|127] "" Vector__XXX
 SG_ VehicleSystem1 m1 : 49|7@1+ (1,0) [0|127] "" Vector__XXX
 SG_ Function : 40|8@1+ (1,0) [0|255] "" Vector__XXX
 SG_ FunctionInstance : 35|5@1+ (1,0) [0|31] "" Vector__XXX
 SG_ ECUInstance : 32|3@1+ (1,0) [0|7] "" Vector__XXX
 SG_ ManufacturerCode : 21|11@1+ (1,0) [0|2047] "" Vector__XXX
 SG_ IdentityNumber : 0|21@1+ (1,0) [0|2097152] "" Vector__XXX

BO_ 2566768126 ECUID: 8 Vector__XXX
 SG_ ECUManufacturerName : 32|8@1+ (1,0) [0|255] "" Vector__XXX
 SG_ ECUType : 24|8@1+ (1,0) [0|255] "" Vector__XXX
 SG_ ECULocation : 16|8@1+ (1,0) [0|255] "" Vector__XXX
 SG_ ECUSerialNumber : 8|8@1+ (1,0) [0|255] "" Vector__XXX
 SG_ ECUPartNumber : 0|8@1+ (1,0) [0|255] "" Vector__XXX
 SG_ ECUHardwareVersionIdentification : 40|8@1+ (1,0) [0|255] "" Vector__XXX

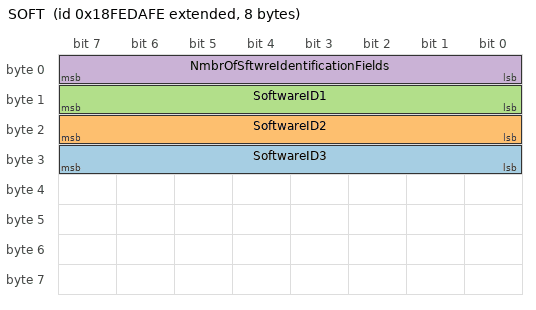
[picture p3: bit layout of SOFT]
BO_ 2566839038 SOFT: 8 Vector__XXX
 SG_ SoftwareID3 : 24|8@1+ (1,0) [0|255] "" Vector__XXX
 SG_ SoftwareID2 : 16|8@1+ (1,0) [0|255] "" Vector__XXX
 SG_ SoftwareID1 : 8|8@1+ (1,0) [0|255] "" Vector__XXX
 SG_ NmbrOfSftwreIdentificationFields : 0|8@1+ (1,0) [0|250] "steps" Vector__XXX

BO_ 2566834942 DM1: 22 Vector__XXX
 SG_ DTC5 : 144|32@1+ (1,0) [0|4294967295] "" Vector__XXX
 SG_ DTC4 : 112|32@1+ (1,0) [0|4294967295] "" Vector__XXX
 SG_ DTC3 : 80|32@1+ (1,0) [0|4294967295] "" Vector__XXX
 SG_ DTC2 : 48|32@1+ (1,0) [0|4294967295] "" Vector__XXX
 SG_ DTC1 : 16|32@1+ (1,0) [0|4294967295] "" Vector__XXX

BO_ 2566835198 DM2: 22 Vector__XXX
 SG_ DTC5 : 144|32@1+ (1,0) [0|4294967295] "" Vector__XXX
 SG_ DTC4 : 112|32@1+ (1,0) [0|4294967295] "" Vector__XXX
 SG_ DTC3 : 80|32@1+ (1,0) [0|4294967295] "" Vector__XXX
 SG_ DTC2 : 48|32@1+ (1,0) [0|4294967295] "" Vector__XXX
 SG_ DTC1 : 16|32@1+ (1,0) [0|4294967295] "" Vector__XXX

BO_ 2566734590 ICC: 8 Vector__XXX
 SG_ CertLaboratoryType_FirstDef m0 : 9|3@1+ (1,0) [0|7] "" Vector__XXX
 SG_ TestProtocolRevision_MSBits m1 : 11|2@1+ (1,0) [0|0] "" Vector__XXX
 SG_ MessageRevision M : 47|1@1+ (1,0) [0|0] "" Vector__XXX
 SG_ CertificationReferenceNumber : 48|16@1+ (1,0) [0|65535] "" Vector__XXX
 SG_ CertTypeTaskController m0 : 39|1@1+ (1,0) [0|1] "" Vector__XXX
 SG_ CertTypeTCWorkingSetMaster m0 : 38|1@1+ (1,0) [0|1] "" Vector__XXX
 SG_ CertTypeTCWorkingSetMember m0 : 37|1@1+ (1,0) [0|1] "" Vector__XXX
 SG_ CertTypeFileServer m0 : 36|1@1+ (1,0) [0|1] "" Vector__XXX
 SG_ CertTypeGPSReceiver m0 : 35|1@1+ (1,0) [0|1] "" Vector__XXX
 SG_ CertTypeMinimumECU m0 : 31|1@1+ (1,0) [0|1] "" Vector__XXX
 SG_ CertTypeTECUClass1 m0 : 30|1@1+ (1,0) [0|1] "" Vector__XXX
 SG_ CertTypeTECUClass2 m0 : 29|1@1+ (1,0) [0|1] "" Vector__XXX
 SG_ CertTypeTECUClass3 m0 : 28|1@1+ (1,0) [0|1] "" Vector__XXX
 SG_ CertTypeClass3ECU m0 : 27|1@1+ (1,0) [0|1] "" Vector__XXX
 SG_ CertTypeVirtualTerminal m0 : 26|1@1+ (1,0) [0|1] "" Vector__XXX
 SG_ CertTypeVTWorkingSetMaster m0 : 25|1@1+ (1,0) [0|1] "" Vector__XXX
 SG_ CertTypeVTWorkingSetMember m0 : 24|1@1+ (1,0) [0|1] "" Vector__XXX
 SG_ CertificationLaboratoryID : 13|11@1+ (1,0) [0|2047] "" Vector__XXX
 SG_ CertLaboratoryType_SecondDef m1 : 9|2@1+ (1,0) [0|3] "" Vector__XXX
 SG_ TestProtocolRevision : 6|3@1+ (1,0) [0|7] "" Vector__XXX
 SG_ TestProtocolPublicationYear : 0|6@1+ (1,2000) [2000|2061] "year" Vector__XXX

BO_ 2566835454 DM3: 0 Vector__XXX

CM_ BO_ 2619670270 "TIM message: TIM client to TIM server";
CM_ BO_ 2619604734 "TIM message: TIM server to TIM client";
CM_ BO_ 2563243774 "Extended TP (Data)";
CM_ BO_ 2563309310 "Extended TP (Command)";
CM_ BO_ 2566842110 "Time/Date";
CM_ SG_ 2566842110 LocalHourOffset "The hour component of the offset between the UTC (Universal Time Coordinate) time and date and a local time zone time ...";
CM_ SG_ 2566842110 LocalMinuteOffset "The minute component of the offset between the UTC time and date and a local time zone time and date.  This is the ...";
CM_ SG_ 2566842110 Day "The day component of the current calendar date.  This should be reported as the day component of the current date at ...";
CM_ SG_ 2566842110 Hours "The hour component of the current time of day.  This should be reported as the hour component of the current time at ...";
CM_ SG_ 2566842110 Minutes "The minutes component of the current time of day.  This should be reported as the minutes component of the current time ...";
CM_ BO_ 2365475326 "Ground-based Speed and Distance";
CM_ BO_ 2365475070 "Wheel-based Speed and Distance";
CM_ SG_ 2365475070 OperatorDirectionReversed "This parameter indicates whether the reported direction is reversed from the perspective of the operator.";
CM_ BO_ 2566787070 "Language Command";
CM_ BO_ 2632777470 "Transport Protocol - Connection Management";
CM_ SG_ 2632777470 MaximumNumberOfPackets "Maximum number of packets for RTS/CTS message.";
CM_ SG_ 2632777470 NextPacketNumberToBeSent "Next Packet Number to be sent (TP.CM_CTS)";
CM_ SG_ 2632777470 ConnectionAbortReason "Reason for connection abort message.";
CM_ SG_ 2632777470 NumberOfPacketsThatCanBeSent "Number of Packets that can be sent (TP.CM_CTS)";
CM_ BO_ 2632711934 "Transport Protocol - Data Transfer";
CM_ BO_ 2565537534 "Request";
CM_ SG_ 2565537534 ParameterGroupNumber "PGN which is requested by the Request message";
CM_ BO_ 2565406462 "Acknowledgment Message";
CM_ SG_ 2565406462 ParameterGroupNumber "PGN which is requested by the Request message";
CM_ BO_ 2565799678 "Address Claimed";
CM_ SG_ 2565799678 ReservedBit "The reserved bit shall be set to zero.";
CM_ BO_ 2566768126 "ECU Identification Information";
CM_ SG_ 2566768126 ECULocation "The location of the ECU within a network.";
CM_ SG_ 2566768126 ECUSerialNumber "The serial number of the physical ECU.";
CM_ SG_ 2566768126 ECUPartNumber "The part number of the physical ECU.";
CM_ SG_ 2566768126 ECUHardwareVersionIdentification "The part number of the physical ECU.";
CM_ BO_ 2566839038 "Software Identification";
CM_ SG_ 2566839038 SoftwareID3 "Software ID";
CM_ SG_ 2566839038 SoftwareID2 "Software ID";
CM_ SG_ 2566839038 SoftwareID1 "Software ID";
CM_ SG_ 2566839038 NmbrOfSftwreIdentificationFields "Number of software identification designators represented in the software identification parameter group.";
CM_ BO_ 2566834942 "Active diagnostic trouble codes";
CM_ SG_ 2566834942 DTC5 "Diagnostic Trouble Code";
CM_ SG_ 2566834942 DTC4 "Diagnostic Trouble Code";
CM_ SG_ 2566834942 DTC3 "Diagnostic Trouble Code";
CM_ SG_ 2566834942 DTC2 "Diagnostic Trouble Code";
CM_ SG_ 2566834942 DTC1 "Diagnostic Trouble Code";
CM_ BO_ 2566835198 "Previously active diagnostic trouble codes";
CM_ SG_ 2566835198 DTC5 "Diagnostic Trouble Code";
CM_ SG_ 2566835198 DTC4 "Diagnostic Trouble Code";
CM_ SG_ 2566835198 DTC3 "Diagnostic Trouble Code";
CM_ SG_ 2566835198 DTC2 "Diagnostic Trouble Code";
CM_ SG_ 2566835198 DTC1 "Diagnostic Trouble Code";
CM_ BO_ 2566734590 "ISOBUS compliance certification";
CM_ SG_ 2566734590 CertLaboratoryType_FirstDef "Approving body for the certification laboratory.";
CM_ SG_ 2566734590 MessageRevision "This parameter distinguishes the format of the ISOBUS Compliance Certification message in the second 
edition from the format in the third and later editions.";
CM_ SG_ 2566734590 CertificationReferenceNumber "ISOBUS Compliance certification reference number";
CM_ SG_ 2566734590 CertTypeTaskController "ISOBUS Compliance certification type - Task Controller";
CM_ SG_ 2566734590 CertTypeTCWorkingSetMaster "ISOBUS Compliance certification type - TC working set master";
CM_ SG_ 2566734590 CertTypeTCWorkingSetMember "ISOBUS Compliance certification type - TC working set member";
CM_ SG_ 2566734590 CertTypeFileServer "ISOBUS Compliance certification type - File server";
CM_ SG_ 2566734590 CertTypeGPSReceiver "ISOBUS Compliance certification type - GPS receiver";
CM_ SG_ 2566734590 CertTypeMinimumECU "ISOBUS Compliance certification type - Minimum ECU";
CM_ SG_ 2566734590 CertTypeTECUClass1 "ISOBUS Compliance certification type - TECU Class 1";
CM_ SG_ 2566734590 CertTypeTECUClass2 "ISOBUS Compliance certification type - TECU Class 2";
CM_ SG_ 2566734590 CertTypeTECUClass3 "ISOBUS Compliance certification type - TECU Class 3";
CM_ SG_ 2566734590 CertTypeClass3ECU "ISOBUS Compliance certification type - Class 3 ECU";
CM_ SG_ 2566734590 CertTypeVirtualTerminal "ISOBUS Compliance certification type - Virtual terminal";
CM_ SG_ 2566734590 CertTypeVTWorkingSetMaster "ISOBUS Compliance certification type - VT working set master";
CM_ SG_ 2566734590 CertTypeVTWorkingSetMember "ISOBUS Compliance certification type - VT working set member";
CM_ SG_ 2566734590 CertificationLaboratoryID "ISOBUS Compliance certification laboratory ID";
CM_ SG_ 2566734590 CertLaboratoryType_SecondDef "Approving body for the certification laboratory.";
CM_ SG_ 2566734590 TestProtocolRevision "ISOBUS compliance certificate revision";
CM_ SG_ 2566734590 TestProtocolPublicationYear "ISOBUS compliance certification year";
CM_ BO_ 2566835454 "Diagnostic data clear/reset of previously active DTCs.";
BA_DEF_ SG_  "DDI" INT 0 65535;
BA_DEF_ BO_  "SingleFrame" INT 0 1;
BA_DEF_ BO_  "VFrameFormat" ENUM  "StandardCAN","ExtendedCAN","reserved","J1939PG","vector_leerstring";
BA_DEF_ BO_  "GenMsgSendType" ENUM  "cyclic","NotUsed","IfActive","NotUsed","NotUsed","NotUsed","NotUsed","NotUsed","noMsgSendType","vector_leerstring";
BA_DEF_ BO_  "GenMsgCycleTime" INT 0 3600000;
BA_DEF_ BO_  "GenMsgRequestable" INT 0 1;
BA_DEF_ BO_  "GenMsgNrOfRepetition" INT 0 1000000;
BA_DEF_ BO_  "GenMsgCycleTimeFast" INT 0 3600000;
BA_DEF_ SG_  "GenSigInactiveValue" INT 0 0;
BA_DEF_ BO_  "GenMsgFastOnStart" INT 0 100000;
BA_DEF_ BO_  "GenMsgStartDelayTime" INT 0 100000;
BA_DEF_ BO_  "GenMsgILSupport" ENUM  "No","Yes";
BA_DEF_ BO_  "GenMsgDelayTime" INT 0 1000;
BA_DEF_ SG_  "SPN" INT 0 524287;
BA_DEF_ SG_  "GenSigSendType" ENUM  "Cyclic","OnWrite","OnWriteWithRepetition","OnChange","OnChangeWithRepetition","IfActive","IfActiveWithRepetition","NoSigSendType";
BA_DEF_ SG_  "SigType" ENUM  "Default","Range","RangeSigned","ASCII","Discrete","Control","ReferencePGN","DTC","StringDelimiter","StringLength","StringLengthControl","MessageCounter","MessageChecksum";
BA_DEF_ SG_  "GenSigStartValue" INT -2147483648 2147483647;
BA_DEF_ SG_  "GenSigILSupport" ENUM  "No","Yes";
BA_DEF_DEF_  "DDI" 0;
BA_DEF_DEF_  "SingleFrame" 1;
BA_DEF_DEF_  "VFrameFormat" "J1939PG";
BA_DEF_DEF_  "GenMsgSendType" "noMsgSendType";
BA_DEF_DEF_  "GenMsgCycleTime" 0;
BA_DEF_DEF_  "GenMsgRequestable" 1;
BA_DEF_DEF_  "GenMsgNrOfRepetition" 0;
BA_DEF_DEF_  "GenMsgCycleTimeFast" 0;
BA_DEF_DEF_  "GenSigInactiveValue" 0;
BA_DEF_DEF_  "GenMsgFastOnStart" 0;
BA_DEF_DEF_  "GenMsgStartDelayTime" 0;
BA_DEF_DEF_  "GenMsgILSupport" "Yes";
BA_DEF_DEF_  "GenMsgDelayTime" 0;
BA_DEF_DEF_  "SPN" 0;
BA_DEF_DEF_  "GenSigSendType" "NoSigSendType";
BA_DEF_DEF_  "SigType" "Default";
BA_DEF_DEF_  "GenSigStartValue" 0;
BA_DEF_DEF_  "GenSigILSupport" "Yes";
BA_ "GenMsgCycleTime" BO_ 2365475326 100;
BA_ "GenMsgSendType" BO_ 2365475326 8.53594844804822E-317;
BA_ "GenMsgCycleTime" BO_ 2365475070 100;
BA_ "GenMsgSendType" BO_ 2365475070 8.53733973690691E-317;
BA_ "GenMsgCycleTime" BO_ 2566787070 100;
BA_ "SPN" SG_ 2619670270 RequestCounterAuxValve32 13360;
BA_ "SPN" SG_ 2619670270 RequestCounterAuxValve31 13359;
BA_ "SPN" SG_ 2619670270 RequestCounterAuxValve30 13358;
BA_ "SPN" SG_ 2619670270 RequestCounterAuxValve29 13357;
BA_ "SPN" SG_ 2619670270 RequestCounterAuxValve28 13356;
BA_ "SPN" SG_ 2619670270 RequestCounterAuxValve27 13355;
BA_ "SPN" SG_ 2619670270 RequestCounterAuxValve26 13354;
BA_ "SPN" SG_ 2619670270 RequestCounterAuxValve25 13353;
BA_ "SPN" SG_ 2619670270 RequestCounterAuxValve24 13352;
BA_ "SPN" SG_ 2619670270 RequestCounterAuxValve23 13351;
BA_ "SPN" SG_ 2619670270 RequestCounterAuxValve22 13350;
BA_ "SPN" SG_ 2619670270 RequestCounterAuxValve21 13349;
BA_ "SPN" SG_ 2619670270 RequestCounterAuxValve20 13348;
BA_ "SPN" SG_ 2619670270 RequestCounterAuxValve19 13347;
BA_ "SPN" SG_ 2619670270 RequestCounterAuxValve18 13346;
BA_ "SPN" SG_ 2619670270 RequestCounterAuxValve17 13345;
BA_ "SPN" SG_ 2619670270 RequestCounterAuxValve16 13344;
BA_ "SPN" SG_ 2619670270 RequestCounterAuxValve15 13343;
BA_ "SPN" SG_ 2619670270 RequestCounterAuxValve14 13342;
BA_ "SPN" SG_ 2619670270 RequestCounterAuxValve13 13341;
BA_ "SPN" SG_ 2619670270 RequestCounterAuxValve12 13340;
BA_ "SPN" SG_ 2619670270 RequestCounterAuxValve11 13339;
BA_ "SPN" SG_ 2619670270 RequestCounterAuxValve10 13338;
BA_ "SPN" SG_ 2619670270 RequestCounterAuxValve09 13337;
BA_ "SPN" SG_ 2619670270 RequestCounterAuxValve08 13336;
BA_ "SPN" SG_ 2619670270 RequestCounterAuxValve07 13335;
BA_ "SPN" SG_ 2619670270 RequestCounterAuxValve06 13334;
BA_ "SPN" SG_ 2619670270 RequestCounterAuxValve05 13333;
BA_ "SPN" SG_ 2619670270 RequestCounterAuxValve04 13332;
BA_ "SPN" SG_ 2619670270 RequestCounterAuxValve03 13331;
BA_ "SPN" SG_ 2619670270 RequestCounterAuxValve02 13330;
BA_ "SPN" SG_ 2619670270 RequestCounterAuxValve01 13329;
BA_ "SPN" SG_ 2619670270 RequestCounterVehicleSpeed 13328;
BA_ "SPN" SG_ 2619670270 RequestCounterRearHitch 13327;
BA_ "SPN" SG_ 2619670270 RequestCounterFrontHitch 13326;
BA_ "SPN" SG_ 2619670270 RequestCounterRearPTO 13325;
BA_ "SPN" SG_ 2619670270 RequestCounterFrontPTO 13324;
BA_ "SPN" SG_ 2619670270 RequestCounterExternalGuidance 13323;
BA_ "GenSigStartValue" SG_ 2619670270 FlowRequest_AV32 32128;
BA_ "SigType" SG_ 2619670270 FlowRequest_AV32 1;
BA_ "SPN" SG_ 2619670270 FlowRequest_AV32 8810;
BA_ "SPN" SG_ 2619670270 FlowRequest_AV31 8809;
BA_ "GenSigStartValue" SG_ 2619670270 FlowRequest_AV31 32128;
BA_ "SigType" SG_ 2619670270 FlowRequest_AV31 1;
BA_ "SPN" SG_ 2619670270 FlowRequest_AV30 8808;
BA_ "GenSigStartValue" SG_ 2619670270 FlowRequest_AV30 32128;
BA_ "SigType" SG_ 2619670270 FlowRequest_AV30 1;
BA_ "SPN" SG_ 2619670270 FlowRequest_AV29 8807;
BA_ "GenSigStartValue" SG_ 2619670270 FlowRequest_AV29 32128;
BA_ "SigType" SG_ 2619670270 FlowRequest_AV29 1;
BA_ "SPN" SG_ 2619670270 FlowRequest_AV28 8806;
BA_ "GenSigStartValue" SG_ 2619670270 FlowRequest_AV28 32128;
BA_ "SigType" SG_ 2619670270 FlowRequest_AV28 1;
BA_ "SPN" SG_ 2619670270 FlowRequest_AV27 8805;
BA_ "GenSigStartValue" SG_ 2619670270 FlowRequest_AV27 32128;
BA_ "SigType" SG_ 2619670270 FlowRequest_AV27 1;
BA_ "SPN" SG_ 2619670270 FlowRequest_AV26 8804;
BA_ "GenSigStartValue" SG_ 2619670270 FlowRequest_AV26 32128;
BA_ "SigType" SG_ 2619670270 FlowRequest_AV26 1;
BA_ "SPN" SG_ 2619670270 FlowRequest_AV25 8803;
BA_ "GenSigStartValue" SG_ 2619670270 FlowRequest_AV25 32128;
BA_ "SigType" SG_ 2619670270 FlowRequest_AV25 1;
BA_ "SPN" SG_ 2619670270 FlowRequest_AV24 8802;
BA_ "GenSigStartValue" SG_ 2619670270 FlowRequest_AV24 32128;
BA_ "SigType" SG_ 2619670270 FlowRequest_AV24 1;
BA_ "SPN" SG_ 2619670270 FlowRequest_AV23 8801;
BA_ "GenSigStartValue" SG_ 2619670270 FlowRequest_AV23 32128;
BA_ "SigType" SG_ 2619670270 FlowRequest_AV23 1;
BA_ "SPN" SG_ 2619670270 FlowRequest_AV22 8800;
BA_ "GenSigStartValue" SG_ 2619670270 FlowRequest_AV22 32128;
BA_ "SigType" SG_ 2619670270 FlowRequest_AV22 1;
BA_ "SPN" SG_ 2619670270 FlowRequest_AV21 8799;
BA_ "GenSigStartValue" SG_ 2619670270 FlowRequest_AV21 32128;
BA_ "SigType" SG_ 2619670270 FlowRequest_AV21 1;
BA_ "SPN" SG_ 2619670270 FlowRequest_AV20 8798;
BA_ "GenSigStartValue" SG_ 2619670270 FlowRequest_AV20 32128;
BA_ "SigType" SG_ 2619670270 FlowRequest_AV20 1;
BA_ "SPN" SG_ 2619670270 FlowRequest_AV19 8797;
BA_ "GenSigStartValue" SG_ 2619670270 FlowRequest_AV19 32128;
BA_ "SigType" SG_ 2619670270 FlowRequest_AV19 1;
BA_ "SPN" SG_ 2619670270 FlowRequest_AV18 8796;
BA_ "GenSigStartValue" SG_ 2619670270 FlowRequest_AV18 32128;
BA_ "SigType" SG_ 2619670270 FlowRequest_AV18 1;
BA_ "SPN" SG_ 2619670270 FlowRequest_AV17 8795;
BA_ "GenSigStartValue" SG_ 2619670270 FlowRequest_AV17 32128;
BA_ "SigType" SG_ 2619670270 FlowRequest_AV17 1;
BA_ "SPN" SG_ 2619670270 FlowRequest_AV16 8794;
BA_ "GenSigStartValue" SG_ 2619670270 FlowRequest_AV16 32128;
BA_ "SigType" SG_ 2619670270 FlowRequest_AV16 1;
BA_ "SPN" SG_ 2619670270 FlowRequest_AV15 8793;
BA_ "GenSigStartValue" SG_ 2619670270 FlowRequest_AV15 32128;
BA_ "SigType" SG_ 2619670270 FlowRequest_AV15 1;
BA_ "SPN" SG_ 2619670270 FlowRequest_AV14 8792;
BA_ "GenSigStartValue" SG_ 2619670270 FlowRequest_AV14 32128;
BA_ "SigType" SG_ 2619670270 FlowRequest_AV14 1;
BA_ "SPN" SG_ 2619670270 FlowRequest_AV13 8791;
BA_ "GenSigStartValue" SG_ 2619670270 FlowRequest_AV13 32128;
BA_ "SigType" SG_ 2619670270 FlowRequest_AV13 1;
BA_ "SPN" SG_ 2619670270 FlowRequest_AV12 8790;
BA_ "GenSigStartValue" SG_ 2619670270 FlowRequest_AV12 32128;
BA_ "SigType" SG_ 2619670270 FlowRequest_AV12 1;
BA_ "SPN" SG_ 2619670270 FlowRequest_AV11 8789;
BA_ "GenSigStartValue" SG_ 2619670270 FlowRequest_AV11 32128;
BA_ "SigType" SG_ 2619670270 FlowRequest_AV11 1;
BA_ "SPN" SG_ 2619670270 FlowRequest_AV10 8788;
BA_ "GenSigStartValue" SG_ 2619670270 FlowRequest_AV10 32128;
BA_ "SigType" SG_ 2619670270 FlowRequest_AV10 1;
BA_ "SPN" SG_ 2619670270 FlowRequest_AV09 8787;
BA_ "GenSigStartValue" SG_ 2619670270 FlowRequest_AV09 32128;
BA_ "SigType" SG_ 2619670270 FlowRequest_AV09 1;
BA_ "SPN" SG_ 2619670270 FlowRequest_AV08 8786;
BA_ "GenSigStartValue" SG_ 2619670270 FlowRequest_AV08 32128;
BA_ "SigType" SG_ 2619670270 FlowRequest_AV08 1;
BA_ "SPN" SG_ 2619670270 FlowRequest_AV07 8785;
BA_ "GenSigStartValue" SG_ 2619670270 FlowRequest_AV07 32128;
BA_ "SigType" SG_ 2619670270 FlowRequest_AV07 1;
BA_ "SPN" SG_ 2619670270 FlowRequest_AV06 8784;
BA_ "GenSigStartValue" SG_ 2619670270 FlowRequest_AV06 32128;
BA_ "SigType" SG_ 2619670270 FlowRequest_AV06 1;
BA_ "SPN" SG_ 2619670270 FlowRequest_AV05 8783;
BA_ "GenSigStartValue" SG_ 2619670270 FlowRequest_AV05 32128;
BA_ "SigType" SG_ 2619670270 FlowRequest_AV05 1;
BA_ "SPN" SG_ 2619670270 FlowRequest_AV04 8782;
BA_ "GenSigStartValue" SG_ 2619670270 FlowRequest_AV04 32128;
BA_ "SigType" SG_ 2619670270 FlowRequest_AV04 1;
BA_ "SPN" SG_ 2619670270 FlowRequest_AV03 8781;
BA_ "GenSigStartValue" SG_ 2619670270 FlowRequest_AV03 32128;
BA_ "SigType" SG_ 2619670270 FlowRequest_AV03 1;
BA_ "SPN" SG_ 2619670270 FlowRequest_AV02 8780;
BA_ "GenSigStartValue" SG_ 2619670270 FlowRequest_AV02 32128;
BA_ "SigType" SG_ 2619670270 FlowRequest_AV02 1;
BA_ "SPN" SG_ 2619670270 RearHitchPosRequest 8814;
BA_ "SigType" SG_ 2619670270 RearHitchPosRequest 1;
BA_ "SPN" SG_ 2619670270 RearPTOSpeedRequest 8812;
BA_ "GenSigStartValue" SG_ 2619670270 RearPTOSpeedRequest 32128;
BA_ "SigType" SG_ 2619670270 RearPTOSpeedRequest 1;
BA_ "SPN" SG_ 2619670270 MinimumTIMVersion_Resp 13288;
BA_ "SPN" SG_ 2619670270 ImplementedTIMVersion_Resp 13287;
BA_ "SPN" SG_ 2619670270 CurvatureRequest 8816;
BA_ "GenSigStartValue" SG_ 2619670270 CurvatureRequest 32128;
BA_ "SigType" SG_ 2619670270 CurvatureRequest 1;
BA_ "SPN" SG_ 2619670270 VehicleSpeedRequest 8815;
BA_ "GenSigStartValue" SG_ 2619670270 VehicleSpeedRequest 32128;
BA_ "SigType" SG_ 2619670270 VehicleSpeedRequest 1;
BA_ "SPN" SG_ 2619670270 FrontHitchPosRequest 8813;
BA_ "SigType" SG_ 2619670270 FrontHitchPosRequest 1;
BA_ "SPN" SG_ 2619670270 FrontPTOSpeedRequest 8811;
BA_ "GenSigStartValue" SG_ 2619670270 FrontPTOSpeedRequest 32128;
BA_ "SigType" SG_ 2619670270 FrontPTOSpeedRequest 1;
BA_ "SPN" SG_ 2619670270 FlowRequest_AV01 8779;
BA_ "GenSigStartValue" SG_ 2619670270 FlowRequest_AV01 32128;
BA_ "SigType" SG_ 2619670270 FlowRequest_AV01 1;
BA_ "SPN" SG_ 2619670270 TIMClientState 13286;
BA_ "SPN" SG_ 2619670270 ClientHeartbeatCounter 13285;
BA_ "GenSigStartValue" SG_ 2619670270 NumOfTIMFunctions 1;
BA_ "SPN" SG_ 2619670270 NumOfTIMFunctions 23881;
BA_ "SPN" SG_ 2619670270 RequestType_1 23882;
BA_ "SPN" SG_ 2619670270 MinimumTIMVersion_Req 13290;
BA_ "SPN" SG_ 2619670270 ImplementedTIMVersion_Req 13289;
BA_ "SPN" SG_ 2619670270 TIMMessageType 23576;
BA_ "SPN" SG_ 2619670270 GroupFunctionValue 23575;
BA_ "SPN" SG_ 2619604734 GroupFunctionValue 23573;
BA_ "SigType" SG_ 2619604734 RearHitchPosition 1;
BA_ "SPN" SG_ 2619604734 RearHitchPosition 8768;
BA_ "SigType" SG_ 2619604734 RearPTOSpeed 1;
BA_ "GenSigStartValue" SG_ 2619604734 RearPTOSpeed 32128;
BA_ "SPN" SG_ 2619604734 RearPTOSpeed 8762;
BA_ "SPN" SG_ 2619604734 FlowAuxValve32 8696;
BA_ "SigType" SG_ 2619604734 FlowAuxValve32 1;
BA_ "GenSigStartValue" SG_ 2619604734 FlowAuxValve32 32128;
BA_ "SPN" SG_ 2619604734 FlowAuxValve31 8695;
BA_ "SigType" SG_ 2619604734 FlowAuxValve31 1;
BA_ "GenSigStartValue" SG_ 2619604734 FlowAuxValve31 32128;
BA_ "SPN" SG_ 2619604734 FlowAuxValve30 8694;
BA_ "SigType" SG_ 2619604734 FlowAuxValve30 1;
BA_ "GenSigStartValue" SG_ 2619604734 FlowAuxValve30 32128;
BA_ "SPN" SG_ 2619604734 FlowAuxValve29 8693;
BA_ "SigType" SG_ 2619604734 FlowAuxValve29 1;
BA_ "GenSigStartValue" SG_ 2619604734 FlowAuxValve29 32128;
BA_ "SPN" SG_ 2619604734 FlowAuxValve28 8692;
BA_ "SigType" SG_ 2619604734 FlowAuxValve28 1;
BA_ "GenSigStartValue" SG_ 2619604734 FlowAuxValve28 32128;
BA_ "SPN" SG_ 2619604734 FlowAuxValve27 8691;
BA_ "SigType" SG_ 2619604734 FlowAuxValve27 1;
BA_ "GenSigStartValue" SG_ 2619604734 FlowAuxValve27 32128;
BA_ "SPN" SG_ 2619604734 FlowAuxValve26 8690;
BA_ "SigType" SG_ 2619604734 FlowAuxValve26 1;
BA_ "GenSigStartValue" SG_ 2619604734 FlowAuxValve26 32128;
BA_ "SPN" SG_ 2619604734 FlowAuxValve25 8689;
BA_ "SigType" SG_ 2619604734 FlowAuxValve25 1;
BA_ "GenSigStartValue" SG_ 2619604734 FlowAuxValve25 32128;
BA_ "SPN" SG_ 2619604734 FlowAuxValve24 8688;
BA_ "SigType" SG_ 2619604734 FlowAuxValve24 1;
BA_ "GenSigStartValue" SG_ 2619604734 FlowAuxValve24 32128;
BA_ "SPN" SG_ 2619604734 FlowAuxValve23 8687;
BA_ "SigType" SG_ 2619604734 FlowAuxValve23 1;
BA_ "GenSigStartValue" SG_ 2619604734 FlowAuxValve23 32128;
BA_ "SPN" SG_ 2619604734 FlowAuxValve22 8686;
BA_ "SigType" SG_ 2619604734 FlowAuxValve22 1;
BA_ "GenSigStartValue" SG_ 2619604734 FlowAuxValve22 32128;
BA_ "SPN" SG_ 2619604734 FlowAuxValve21 8685;
BA_ "SigType" SG_ 2619604734 FlowAuxValve21 1;
BA_ "GenSigStartValue" SG_ 2619604734 FlowAuxValve21 32128;
BA_ "SPN" SG_ 2619604734 FlowAuxValve20 8684;
BA_ "SigType" SG_ 2619604734 FlowAuxValve20 1;
BA_ "GenSigStartValue" SG_ 2619604734 FlowAuxValve20 32128;
BA_ "SPN" SG_ 2619604734 FlowAuxValve19 8683;
BA_ "SigType" SG_ 2619604734 FlowAuxValve19 1;
BA_ "GenSigStartValue" SG_ 2619604734 FlowAuxValve19 32128;
BA_ "SPN" SG_ 2619604734 FlowAuxValve18 8682;
BA_ "SigType" SG_ 2619604734 FlowAuxValve18 1;
BA_ "GenSigStartValue" SG_ 2619604734 FlowAuxValve18 32128;
BA_ "SPN" SG_ 2619604734 FlowAuxValve17 8681;
BA_ "SigType" SG_ 2619604734 FlowAuxValve17 1;
BA_ "GenSigStartValue" SG_ 2619604734 FlowAuxValve17 32128;
BA_ "SPN" SG_ 2619604734 FlowAuxValve16 8680;
BA_ "SigType" SG_ 2619604734 FlowAuxValve16 1;
BA_ "GenSigStartValue" SG_ 2619604734 FlowAuxValve16 32128;
BA_ "SPN" SG_ 2619604734 FlowAuxValve15 8679;
BA_ "SigType" SG_ 2619604734 FlowAuxValve15 1;
BA_ "GenSigStartValue" SG_ 2619604734 FlowAuxValve15 32128;
BA_ "SPN" SG_ 2619604734 FlowAuxValve14 8678;
BA_ "SigType" SG_ 2619604734 FlowAuxValve14 1;
BA_ "GenSigStartValue" SG_ 2619604734 FlowAuxValve14 32128;
BA_ "SPN" SG_ 2619604734 FlowAuxValve13 8677;
BA_ "SigType" SG_ 2619604734 FlowAuxValve13 1;
BA_ "GenSigStartValue" SG_ 2619604734 FlowAuxValve13 32128;
BA_ "SPN" SG_ 2619604734 FlowAuxValve12 8676;
BA_ "SigType" SG_ 2619604734 FlowAuxValve12 1;
BA_ "GenSigStartValue" SG_ 2619604734 FlowAuxValve12 32128;
BA_ "SPN" SG_ 2619604734 FlowAuxValve11 8675;
BA_ "SigType" SG_ 2619604734 FlowAuxValve11 1;
BA_ "GenSigStartValue" SG_ 2619604734 FlowAuxValve11 32128;
BA_ "SPN" SG_ 2619604734 FlowAuxValve10 8674;
BA_ "SigType" SG_ 2619604734 FlowAuxValve10 1;
BA_ "GenSigStartValue" SG_ 2619604734 FlowAuxValve10 32128;
BA_ "SPN" SG_ 2619604734 FlowAuxValve09 8673;
BA_ "SigType" SG_ 2619604734 FlowAuxValve09 1;
BA_ "GenSigStartValue" SG_ 2619604734 FlowAuxValve09 32128;
BA_ "SPN" SG_ 2619604734 FlowAuxValve08 8672;
BA_ "SigType" SG_ 2619604734 FlowAuxValve08 1;
BA_ "GenSigStartValue" SG_ 2619604734 FlowAuxValve08 32128;
BA_ "SPN" SG_ 2619604734 FlowAuxValve07 8671;
BA_ "SigType" SG_ 2619604734 FlowAuxValve07 1;
BA_ "GenSigStartValue" SG_ 2619604734 FlowAuxValve07 32128;
BA_ "SPN" SG_ 2619604734 FlowAuxValve06 8670;
BA_ "SigType" SG_ 2619604734 FlowAuxValve06 1;
BA_ "GenSigStartValue" SG_ 2619604734 FlowAuxValve06 32128;
BA_ "SPN" SG_ 2619604734 FlowAuxValve05 8669;
BA_ "SigType" SG_ 2619604734 FlowAuxValve05 1;
BA_ "GenSigStartValue" SG_ 2619604734 FlowAuxValve05 32128;
BA_ "SPN" SG_ 2619604734 FlowAuxValve04 8668;
BA_ "SigType" SG_ 2619604734 FlowAuxValve04 1;
BA_ "GenSigStartValue" SG_ 2619604734 FlowAuxValve04 32128;
BA_ "SPN" SG_ 2619604734 FlowAuxValve03 8667;
BA_ "SigType" SG_ 2619604734 FlowAuxValve03 1;
BA_ "GenSigStartValue" SG_ 2619604734 FlowAuxValve03 32128;
BA_ "SPN" SG_ 2619604734 FlowAuxValve02 8666;
BA_ "SigType" SG_ 2619604734 FlowAuxValve02 1;
BA_ "GenSigStartValue" SG_ 2619604734 FlowAuxValve02 32128;
BA_ "SPN" SG_ 2619604734 FlowTypeAuxValve32 13282;
BA_ "SPN" SG_ 2619604734 FlowTypeAuxValve31 13281;
BA_ "SPN" SG_ 2619604734 FlowTypeAuxValve30 13280;
BA_ "SPN" SG_ 2619604734 FlowTypeAuxValve29 13279;
BA_ "SPN" SG_ 2619604734 FlowTypeAuxValve28 13278;
BA_ "SPN" SG_ 2619604734 FlowTypeAuxValve27 13277;
BA_ "SPN" SG_ 2619604734 FlowTypeAuxValve26 13276;
BA_ "SPN" SG_ 2619604734 FlowTypeAuxValve25 13275;
BA_ "SPN" SG_ 2619604734 FlowTypeAuxValve24 13274;
BA_ "SPN" SG_ 2619604734 FlowTypeAuxValve23 13273;
BA_ "SPN" SG_ 2619604734 FlowTypeAuxValve22 13272;
BA_ "SPN" SG_ 2619604734 FlowTypeAuxValve21 13271;
BA_ "SPN" SG_ 2619604734 FlowTypeAuxValve20 13270;
BA_ "SPN" SG_ 2619604734 FlowTypeAuxValve19 13269;
BA_ "SPN" SG_ 2619604734 FlowTypeAuxValve18 13268;
BA_ "SPN" SG_ 2619604734 FlowTypeAuxValve17 13267;
BA_ "SPN" SG_ 2619604734 FlowTypeAuxValve16 13266;
BA_ "SPN" SG_ 2619604734 FlowTypeAuxValve15 13265;
BA_ "SPN" SG_ 2619604734 FlowTypeAuxValve14 13264;
BA_ "SPN" SG_ 2619604734 FlowTypeAuxValve13 13263;
BA_ "SPN" SG_ 2619604734 FlowTypeAuxValve12 13262;
BA_ "SPN" SG_ 2619604734 FlowTypeAuxValve11 13261;
BA_ "SPN" SG_ 2619604734 FlowTypeAuxValve10 13260;
BA_ "SPN" SG_ 2619604734 FlowTypeAuxValve09 13259;
BA_ "SPN" SG_ 2619604734 FlowTypeAuxValve08 13258;
BA_ "SPN" SG_ 2619604734 FlowTypeAuxValve07 13257;
BA_ "SPN" SG_ 2619604734 FlowTypeAuxValve06 13256;
BA_ "SPN" SG_ 2619604734 FlowTypeAuxValve05 13255;
BA_ "SPN" SG_ 2619604734 FlowTypeAuxValve04 13254;
BA_ "SPN" SG_ 2619604734 FlowTypeAuxValve03 13253;
BA_ "SPN" SG_ 2619604734 FlowTypeAuxValve02 13252;
BA_ "SPN" SG_ 2619604734 FlowTypeAuxValve01 13251;
BA_ "SPN" SG_ 2619604734 ExitReasonCodeRearPTO 8766;
BA_ "SPN" SG_ 2619604734 ExitReasonCodeRearHitch 8772;
BA_ "SPN" SG_ 2619604734 ExitReasonCodeAuxValve32 8760;
BA_ "SPN" SG_ 2619604734 ExitReasonCodeAuxValve31 8769;
BA_ "SPN" SG_ 2619604734 ExitReasonCodeAuxValve30 8758;
BA_ "SPN" SG_ 2619604734 ExitReasonCodeAuxValve29 8757;
BA_ "SPN" SG_ 2619604734 ExitReasonCodeAuxValve28 8756;
BA_ "SPN" SG_ 2619604734 ExitReasonCodeAuxValve27 8755;
BA_ "SPN" SG_ 2619604734 ExitReasonCodeAuxValve26 8754;
BA_ "SPN" SG_ 2619604734 ExitReasonCodeAuxValve25 8753;
BA_ "SPN" SG_ 2619604734 ExitReasonCodeAuxValve24 8752;
BA_ "SPN" SG_ 2619604734 ExitReasonCodeAuxValve23 8751;
BA_ "SPN" SG_ 2619604734 ExitReasonCodeAuxValve22 8750;
BA_ "SPN" SG_ 2619604734 ExitReasonCodeAuxValve21 8749;
BA_ "SPN" SG_ 2619604734 ExitReasonCodeAuxValve20 8748;
BA_ "SPN" SG_ 2619604734 ExitReasonCodeAuxValve19 8747;
BA_ "SPN" SG_ 2619604734 ExitReasonCodeAuxValve18 8746;
BA_ "SPN" SG_ 2619604734 ExitReasonCodeAuxValve17 8745;
BA_ "SPN" SG_ 2619604734 ExitReasonCodeAuxValve16 8744;
BA_ "SPN" SG_ 2619604734 ExitReasonCodeAuxValve15 8743;
BA_ "SPN" SG_ 2619604734 ExitReasonCodeAuxValve14 8742;
BA_ "SPN" SG_ 2619604734 ExitReasonCodeAuxValve13 8741;
BA_ "SPN" SG_ 2619604734 ExitReasonCodeAuxValve12 8740;
BA_ "SPN" SG_ 2619604734 ExitReasonCodeAuxValve11 8739;
BA_ "SPN" SG_ 2619604734 ExitReasonCodeAuxValve10 8738;
BA_ "SPN" SG_ 2619604734 ExitReasonCodeAuxValve09 8737;
BA_ "SPN" SG_ 2619604734 ExitReasonCodeAuxValve08 8736;
BA_ "SPN" SG_ 2619604734 ExitReasonCodeAuxValve07 8735;
BA_ "SPN" SG_ 2619604734 ExitReasonCodeAuxValve06 8734;
BA_ "SPN" SG_ 2619604734 ExitReasonCodeAuxValve05 8733;
BA_ "SPN" SG_ 2619604734 ExitReasonCodeAuxValve04 8732;
BA_ "SPN" SG_ 2619604734 ExitReasonCodeAuxValve03 8731;
BA_ "SPN" SG_ 2619604734 ExitReasonCodeAuxValve02 8730;
BA_ "SPN" SG_ 2619604734 AutomationStatusAuxValve04 8700;
BA_ "SPN" SG_ 2619604734 AutomationStatusAuxValve03 8699;
BA_ "SPN" SG_ 2619604734 AutomationStatusAuxValve02 8698;
BA_ "SPN" SG_ 2619604734 AutomationStatusAuxValve01 8697;
BA_ "SPN" SG_ 2619604734 AutomationStatusExternalGuidance 8777;
BA_ "SPN" SG_ 2619604734 AutomationStatusVehicleSpeed 8774;
BA_ "SPN" SG_ 2619604734 AutomationStatusRearHitch 8770;
BA_ "SPN" SG_ 2619604734 AutomationStatusFrontHitch 8769;
BA_ "SPN" SG_ 2619604734 AutomationStatusRearPTO 8764;
BA_ "SPN" SG_ 2619604734 AutomationStatusFrontPTO 8763;
BA_ "SPN" SG_ 2619604734 AutomationStatusAuxValve32 8728;
BA_ "SPN" SG_ 2619604734 AutomationStatusAuxValve31 8727;
BA_ "SPN" SG_ 2619604734 AutomationStatusAuxValve30 8726;
BA_ "SPN" SG_ 2619604734 AutomationStatusAuxValve29 8725;
BA_ "SPN" SG_ 2619604734 AutomationStatusAuxValve28 8724;
BA_ "SPN" SG_ 2619604734 AutomationStatusAuxValve27 8723;
BA_ "SPN" SG_ 2619604734 AutomationStatusAuxValve26 8722;
BA_ "SPN" SG_ 2619604734 AutomationStatusAuxValve25 8721;
BA_ "SPN" SG_ 2619604734 AutomationStatusAuxValve24 8720;
BA_ "SPN" SG_ 2619604734 AutomationStatusAuxValve23 8719;
BA_ "SPN" SG_ 2619604734 AutomationStatusAuxValve22 8718;
BA_ "SPN" SG_ 2619604734 AutomationStatusAuxValve21 8717;
BA_ "SPN" SG_ 2619604734 AutomationStatusAuxValve20 8716;
BA_ "SPN" SG_ 2619604734 AutomationStatusAuxValve19 8715;
BA_ "SPN" SG_ 2619604734 AutomationStatusAuxValve18 8714;
BA_ "SPN" SG_ 2619604734 AutomationStatusAuxValve17 8713;
BA_ "SPN" SG_ 2619604734 AutomationStatusAuxValve16 8712;
BA_ "SPN" SG_ 2619604734 AutomationStatusAuxValve15 8711;
BA_ "SPN" SG_ 2619604734 AutomationStatusAuxValve14 8710;
BA_ "SPN" SG_ 2619604734 AutomationStatusAuxValve13 8709;
BA_ "SPN" SG_ 2619604734 AutomationStatusAuxValve12 8708;
BA_ "SPN" SG_ 2619604734 AutomationStatusAuxValve11 8707;
BA_ "SPN" SG_ 2619604734 AutomationStatusAuxValve10 8706;
BA_ "SPN" SG_ 2619604734 AutomationStatusAuxValve09 8705;
BA_ "SPN" SG_ 2619604734 AutomationStatusAuxValve08 8704;
BA_ "SPN" SG_ 2619604734 AutomationStatusAuxValve07 8703;
BA_ "SPN" SG_ 2619604734 AutomationStatusAuxValve06 8702;
BA_ "SPN" SG_ 2619604734 AutomationStatusAuxValve05 8701;
BA_ "SPN" SG_ 2619604734 NumOfUnassignedServerFcts 23886;
BA_ "GenSigStartValue" SG_ 2619604734 Curvature 32128;
BA_ "SigType" SG_ 2619604734 Curvature 1;
BA_ "SPN" SG_ 2619604734 Curvature 8776;
BA_ "SPN" SG_ 2619604734 ExitReasonCodeExternalGuidance 8778;
BA_ "GenSigStartValue" SG_ 2619604734 VehicleSpeed 32128;
BA_ "SigType" SG_ 2619604734 VehicleSpeed 1;
BA_ "SPN" SG_ 2619604734 VehicleSpeed 8773;
BA_ "SPN" SG_ 2619604734 ExitReasonCodeVehicleSpeed 8775;
BA_ "SigType" SG_ 2619604734 FrontHitchPosition 1;
BA_ "SPN" SG_ 2619604734 FrontHitchPosition 8767;
BA_ "SPN" SG_ 2619604734 ExitReasonCodeFrontHitch 8771;
BA_ "GenSigStartValue" SG_ 2619604734 FrontPTOSpeed 32128;
BA_ "SigType" SG_ 2619604734 FrontPTOSpeed 1;
BA_ "SPN" SG_ 2619604734 FrontPTOSpeed 8761;
BA_ "SPN" SG_ 2619604734 ExitReasonCodeFrontPTO 8765;
BA_ "GenSigStartValue" SG_ 2619604734 FlowAuxValve01 32128;
BA_ "SigType" SG_ 2619604734 FlowAuxValve01 1;
BA_ "SPN" SG_ 2619604734 FlowAuxValve01 8665;
BA_ "SPN" SG_ 2619604734 ReflectedRequestCounter 13250;
BA_ "SPN" SG_ 2619604734 ExitReasonCodeAuxValve01 8729;
BA_ "SPN" SG_ 2619604734 TIMSystemOperationState 13215;
BA_ "SPN" SG_ 2619604734 TIMServerState 13211;
BA_ "SPN" SG_ 2619604734 TIMSystemState 13214;
BA_ "SPN" SG_ 2619604734 LeadTIMServerIndication 23592;
BA_ "SPN" SG_ 2619604734 ServerHeartbeatCounter 13212;
BA_ "SPN" SG_ 2619604734 AssignmentErrorReason_1 23885;
BA_ "SPN" SG_ 2619604734 AssignmentResult_1 23884;
BA_ "GenSigStartValue" SG_ 2619604734 NumOfTIMFunctions 1;
BA_ "SPN" SG_ 2619604734 NumOfTIMFunctions 23883;
BA_ "SPN" SG_ 2619604734 NumOfSupportedTIMFunctions 23878;
BA_ "GenSigStartValue" SG_ 2619604734 NumOfSupportedTIMFunctions 1;
BA_ "SPN" SG_ 2619604734 TIMConnectionVersion 13220;
BA_ "SPN" SG_ 2619604734 ErrorCode 13219;
BA_ "SPN" SG_ 2619604734 MinimumTIMVersionNr 13218;
BA_ "SPN" SG_ 2619604734 ImplementedTIMVersionNr 13217;
BA_ "SPN" SG_ 2619604734 BootTime 13216;
BA_ "SPN" SG_ 2619604734 TIMMessageType 23574;
BA_ "SigType" SG_ 2563243774 Byte7 1;
BA_ "SigType" SG_ 2563243774 Byte6 1;
BA_ "SigType" SG_ 2563243774 Byte5 1;
BA_ "SigType" SG_ 2563243774 Byte4 1;
BA_ "SigType" SG_ 2563243774 Byte3 1;
BA_ "SigType" SG_ 2563243774 Byte2 1;
BA_ "SigType" SG_ 2563243774 Byte1 1;
BA_ "GenSigStartValue" SG_ 2563243774 SequenceNumber 1;
BA_ "SigType" SG_ 2563243774 SequenceNumber 1;
BA_ "SigType" SG_ 2563309310 PGNumber 6;
BA_ "SigType" SG_ 2563309310 DataPacketOffset 1;
BA_ "GenSigStartValue" SG_ 2563309310 NextPacketNumberToSend 1;
BA_ "SigType" SG_ 2563309310 NextPacketNumberToSend 1;
BA_ "GenSigStartValue" SG_ 2563309310 NumberOfBytesTransfered 1786;
BA_ "SigType" SG_ 2563309310 NumberOfBytesTransfered 1;
BA_ "GenSigStartValue" SG_ 2563309310 NumberOfPacketsOffset 1;
BA_ "SigType" SG_ 2563309310 NumberOfPacketsOffset 1;
BA_ "GenSigStartValue" SG_ 2563309310 NumberOfPacketsToSend 1;
BA_ "SigType" SG_ 2563309310 NumberOfPacketsToSend 1;
BA_ "GenSigStartValue" SG_ 2563309310 NumberOfBytesToTransfer 1786;
BA_ "SigType" SG_ 2563309310 NumberOfBytesToTransfer 1;
BA_ "SigType" SG_ 2563309310 ControlByte 1;
BA_ "SPN" SG_ 2566842110 LocalHourOffset 1602;
BA_ "SigType" SG_ 2566842110 LocalHourOffset 1;
BA_ "SPN" SG_ 2566842110 LocalMinuteOffset 1601;
BA_ "SigType" SG_ 2566842110 LocalMinuteOffset 1;
BA_ "SPN" SG_ 2566842110 Year 964;
BA_ "SigType" SG_ 2566842110 Year 1;
BA_ "SPN" SG_ 2566842110 Day 962;
BA_ "SigType" SG_ 2566842110 Day 1;
BA_ "SPN" SG_ 2566842110 Month 963;
BA_ "SigType" SG_ 2566842110 Month 1;
BA_ "SPN" SG_ 2566842110 Hours 961;
BA_ "SigType" SG_ 2566842110 Hours 1;
BA_ "SPN" SG_ 2566842110 Minutes 960;
BA_ "SigType" SG_ 2566842110 Minutes 1;
BA_ "SPN" SG_ 2566842110 Seconds 959;
BA_ "SigType" SG_ 2566842110 Seconds 1;
BA_ "SPN" SG_ 2365475326 GroundBasedMachineDirection 1861;
BA_ "SigType" SG_ 2365475326 GroundBasedMachineDirection 4;
BA_ "SPN" SG_ 2365475326 GroundBasedMachineDistance 1860;
BA_ "SigType" SG_ 2365475326 GroundBasedMachineDistance 1;
BA_ "SPN" SG_ 2365475326 GroundBasedMachineSpeed 1859;
BA_ "SigType" SG_ 2365475326 GroundBasedMachineSpeed 1;
BA_ "SPN" SG_ 2365475070 OperatorDirectionReversed 5244;
BA_ "SigType" SG_ 2365475070 OperatorDirectionReversed 5;
BA_ "SPN" SG_ 2365475070 StartStopState 5203;
BA_ "SigType" SG_ 2365475070 StartStopState 4;
BA_ "SPN" SG_ 2365475070 KeySwitchState 1865;
BA_ "SigType" SG_ 2365475070 KeySwitchState 4;
BA_ "SPN" SG_ 2365475070 WheelBasedMachineDirection 1864;
BA_ "SigType" SG_ 2365475070 WheelBasedMachineDirection 4;
BA_ "SPN" SG_ 2365475070 MaxTimeOfTractorPower 1866;
BA_ "SigType" SG_ 2365475070 MaxTimeOfTractorPower 1;
BA_ "SPN" SG_ 2365475070 WheelBasedMachineDistance 1863;
BA_ "SigType" SG_ 2365475070 WheelBasedMachineDistance 1;
BA_ "SPN" SG_ 2365475070 WheelBasedMachineSpeed 1862;
BA_ "SigType" SG_ 2365475070 WheelBasedMachineSpeed 1;
BA_ "SigType" SG_ 2566787070 CountryCode 3;
BA_ "SPN" SG_ 2566787070 TemperatureUnits 5194;
BA_ "SigType" SG_ 2566787070 TemperatureUnits 4;
BA_ "SPN" SG_ 2566787070 PressureUnits 5195;
BA_ "SigType" SG_ 2566787070 PressureUnits 4;
BA_ "SPN" SG_ 2566787070 ForceUnits 5196;
BA_ "SigType" SG_ 2566787070 ForceUnits 4;
BA_ "SPN" SG_ 2566787070 UnitsSystem 5197;
BA_ "SigType" SG_ 2566787070 UnitsSystem 4;
BA_ "SigType" SG_ 2566787070 DistanceUnitCmd 4;
BA_ "SPN" SG_ 2566787070 DistanceUnitCmd 2414;
BA_ "SigType" SG_ 2566787070 AreaUnitCmd 4;
BA_ "SPN" SG_ 2566787070 AreaUnitCmd 2415;
BA_ "SigType" SG_ 2566787070 VolumeUnitCmd 4;
BA_ "SPN" SG_ 2566787070 VolumeUnitCmd 2416;
BA_ "SigType" SG_ 2566787070 MassUnitCmd 4;
BA_ "SPN" SG_ 2566787070 MassUnitCmd 2417;
BA_ "SigType" SG_ 2566787070 DateFormatCmd 1;
BA_ "SPN" SG_ 2566787070 DateFormatCmd 2412;
BA_ "SigType" SG_ 2566787070 DecimalSymbolCmd 4;
BA_ "SPN" SG_ 2566787070 DecimalSymbolCmd 2411;
BA_ "SigType" SG_ 2566787070 TimeFormatCmd 4;
BA_ "SPN" SG_ 2566787070 TimeFormatCmd 2413;
BA_ "SigType" SG_ 2566787070 LanguageCodeCmd 3;
BA_ "SPN" SG_ 2566787070 LanguageCodeCmd 2410;
BA_ "SPN" SG_ 2632777470 PGNumber 2560;
BA_ "SigType" SG_ 2632777470 PGNumber 6;
BA_ "SPN" SG_ 2632777470 MaximumNumberOfPackets 2559;
BA_ "SPN" SG_ 2632777470 TotalNumberOfPackets 2558;
BA_ "SPN" SG_ 2632777470 NextPacketNumberToBeSent 2562;
BA_ "SPN" SG_ 2632777470 ConnectionAbortReason 2570;
BA_ "SPN" SG_ 2632777470 NumberOfPacketsThatCanBeSent 2561;
BA_ "SPN" SG_ 2632777470 ControlByte 2556;
BA_ "SPN" SG_ 2632711934 SequenceNumber 2572;
BA_ "SPN" SG_ 2565537534 ParameterGroupNumber 2574;
BA_ "SigType" SG_ 2565537534 ParameterGroupNumber 6;
BA_ "SPN" SG_ 2565406462 ParameterGroupNumber 2574;
BA_ "SigType" SG_ 2565406462 ParameterGroupNumber 6;
BA_ "SigType" SG_ 2565406462 GroupFunctionValue 1;
BA_ "SPN" SG_ 2565406462 GroupFunctionValue 2542;
BA_ "SPN" SG_ 2565406462 ControlByte 2541;
BA_ "SPN" SG_ 2565799678 ArbitraryAddressCapable 2844;
BA_ "SPN" SG_ 2565799678 IndustryGroup 2846;
BA_ "SPN" SG_ 2565799678 VehicleSystemInstance 2843;
BA_ "SPN" SG_ 2565799678 Function 2841;
BA_ "SPN" SG_ 2565799678 FunctionInstance 2839;
BA_ "SPN" SG_ 2565799678 ECUInstance 2840;
BA_ "SPN" SG_ 2565799678 ManufacturerCode 2838;
BA_ "SigType" SG_ 2565799678 ManufacturerCode 1;
BA_ "SPN" SG_ 2565799678 IdentityNumber 2837;
BA_ "SigType" SG_ 2566768126 ECUManufacturerName 8;
BA_ "SPN" SG_ 2566768126 ECUManufacturerName 4304;
BA_ "SPN" SG_ 2566768126 ECUType 2904;
BA_ "SigType" SG_ 2566768126 ECUType 8;
BA_ "SPN" SG_ 2566768126 ECULocation 2903;
BA_ "SigType" SG_ 2566768126 ECULocation 8;
BA_ "SPN" SG_ 2566768126 ECUSerialNumber 2902;
BA_ "SigType" SG_ 2566768126 ECUSerialNumber 8;
BA_ "SPN" SG_ 2566768126 ECUPartNumber 2901;
BA_ "SigType" SG_ 2566768126 ECUPartNumber 8;
BA_ "SigType" SG_ 2566768126 ECUHardwareVersionIdentification 8;
BA_ "SPN" SG_ 2566839038 SoftwareID3 234;
BA_ "SigType" SG_ 2566839038 SoftwareID3 8;
BA_ "SPN" SG_ 2566839038 SoftwareID2 234;
BA_ "SigType" SG_ 2566839038 SoftwareID2 8;
BA_ "SPN" SG_ 2566839038 SoftwareID1 234;
BA_ "SigType" SG_ 2566839038 SoftwareID1 8;
BA_ "SPN" SG_ 2566839038 NmbrOfSftwreIdentificationFields 965;
BA_ "SigType" SG_ 2566839038 NmbrOfSftwreIdentificationFields 1;
BA_ "SigType" SG_ 2566834942 DTC5 7;
BA_ "SigType" SG_ 2566834942 DTC4 7;
BA_ "SigType" SG_ 2566834942 DTC3 7;
BA_ "SigType" SG_ 2566834942 DTC2 7;
BA_ "SigType" SG_ 2566834942 DTC1 7;
BA_ "SigType" SG_ 2566835198 DTC5 7;
BA_ "SigType" SG_ 2566835198 DTC4 7;
BA_ "SigType" SG_ 2566835198 DTC3 7;
BA_ "SigType" SG_ 2566835198 DTC2 7;
BA_ "SigType" SG_ 2566835198 DTC1 7;
BA_ "SPN" SG_ 2566734590 CertLaboratoryType_FirstDef 4315;
BA_ "SPN" SG_ 2566734590 MessageRevision 7446;
BA_ "SPN" SG_ 2566734590 CertificationReferenceNumber 4330;
BA_ "SPN" SG_ 2566734590 CertTypeTaskController 4325;
BA_ "SPN" SG_ 2566734590 CertTypeTCWorkingSetMaster 4326;
BA_ "SPN" SG_ 2566734590 CertTypeTCWorkingSetMember 4327;
BA_ "SPN" SG_ 2566734590 CertTypeFileServer 4328;
BA_ "SPN" SG_ 2566734590 CertTypeGPSReceiver 4329;
BA_ "SPN" SG_ 2566734590 CertTypeMinimumECU 4317;
BA_ "SPN" SG_ 2566734590 CertTypeTECUClass1 4318;
BA_ "SPN" SG_ 2566734590 CertTypeTECUClass2 4319;
BA_ "SPN" SG_ 2566734590 CertTypeTECUClass3 4320;
BA_ "SPN" SG_ 2566734590 CertTypeClass3ECU 4321;
BA_ "SPN" SG_ 2566734590 CertTypeVirtualTerminal 4322;
BA_ "SPN" SG_ 2566734590 CertTypeVTWorkingSetMaster 4323;
BA_ "SPN" SG_ 2566734590 CertTypeVTWorkingSetMember 4324;
BA_ "SPN" SG_ 2566734590 CertificationLaboratoryID 4316;
BA_ "SPN" SG_ 2566734590 CertLaboratoryType_SecondDef 4315;
BA_ "SPN" SG_ 2566734590 TestProtocolRevision 4314;
BA_ "SPN" SG_ 2566734590 TestProtocolPublicationYear 4313;
VAL_ 2619670270 RequestCounterAuxValve32 15 "NotAvailable_DontCare " 14 "Reserved" ;
VAL_ 2619670270 RequestCounterAuxValve31 15 "NotAvailable_DontCare " 14 "Reserved" ;
VAL_ 2619670270 RequestCounterAuxValve30 15 "NotAvailable_DontCare " 14 "Reserved" ;
VAL_ 2619670270 RequestCounterAuxValve29 15 "NotAvailable_DontCare " 14 "Reserved" ;
VAL_ 2619670270 RequestCounterAuxValve28 15 "NotAvailable_DontCare " 14 "Reserved" ;
VAL_ 2619670270 RequestCounterAuxValve27 15 "NotAvailable_DontCare " 14 "Reserved" ;
VAL_ 2619670270 RequestCounterAuxValve26 15 "NotAvailable_DontCare " 14 "Reserved" ;
VAL_ 2619670270 RequestCounterAuxValve25 15 "NotAvailable_DontCare " 14 "Reserved" ;
VAL_ 2619670270 RequestCounterAuxValve24 15 "NotAvailable_DontCare " 14 "Reserved" ;
VAL_ 2619670270 RequestCounterAuxValve23 15 "NotAvailable_DontCare " 14 "Reserved" ;
VAL_ 2619670270 RequestCounterAuxValve22 15 "NotAvailable_DontCare " 14 "Reserved" ;
VAL_ 2619670270 RequestCounterAuxValve21 15 "NotAvailable_DontCare " 14 "Reserved" ;
VAL_ 2619670270 RequestCounterAuxValve20 15 "NotAvailable_DontCare " 14 "Reserved" ;
VAL_ 2619670270 RequestCounterAuxValve19 15 "NotAvailable_DontCare " 14 "Reserved" ;
VAL_ 2619670270 RequestCounterAuxValve18 15 "NotAvailable_DontCare " 14 "Reserved" ;
VAL_ 2619670270 RequestCounterAuxValve17 15 "NotAvailable_DontCare " 14 "Reserved" ;
VAL_ 2619670270 RequestCounterAuxValve16 15 "NotAvailable_DontCare " 14 "Reserved" ;
VAL_ 2619670270 RequestCounterAuxValve15 15 "NotAvailable_DontCare " 14 "Reserved" ;
VAL_ 2619670270 RequestCounterAuxValve14 15 "NotAvailable_DontCare " 14 "Reserved" ;
VAL_ 2619670270 RequestCounterAuxValve13 15 "NotAvailable_DontCare " 14 "Reserved" ;
VAL_ 2619670270 RequestCounterAuxValve12 15 "NotAvailable_DontCare " 14 "Reserved" ;
VAL_ 2619670270 RequestCounterAuxValve11 15 "NotAvailable_DontCare " 14 "Reserved" ;
VAL_ 2619670270 RequestCounterAuxValve10 15 "NotAvailable_DontCare " 14 "Reserved" ;
VAL_ 2619670270 RequestCounterAuxValve09 15 "NotAvailable_DontCare " 14 "Reserved" ;
VAL_ 2619670270 RequestCounterAuxValve08 15 "NotAvailable_DontCare " 14 "Reserved" ;
VAL_ 2619670270 RequestCounterAuxValve07 15 "NotAvailable_DontCare " 14 "Reserved" ;
VAL_ 2619670270 RequestCounterAuxValve06 15 "NotAvailable_DontCare " 14 "Reserved" ;
VAL_ 2619670270 RequestCounterAuxValve05 15 "NotAvailable_DontCare " 14 "Reserved" ;
VAL_ 2619670270 RequestCounterAuxValve04 15 "NotAvailable_DontCare " 14 "Reserved" ;
VAL_ 2619670270 RequestCounterAuxValve03 15 "NotAvailable_DontCare " 14 "Reserved" ;
VAL_ 2619670270 RequestCounterAuxValve02 15 "NotAvailable_DontCare " 14 "Reserved" ;
VAL_ 2619670270 RequestCounterAuxValve01 15 "NotAvailable_DontCare " 14 "Reserved" ;
VAL_ 2619670270 RequestCounterVehicleSpeed 15 "NotAvailable_DontCare " 14 "Reserved" ;
VAL_ 2619670270 RequestCounterRearHitch 15 "NotAvailable_DontCare " 14 "Reserved" ;
VAL_ 2619670270 RequestCounterFrontHitch 15 "NotAvailable_DontCare " 14 "Reserved" ;
VAL_ 2619670270 RequestCounterRearPTO 15 "NotAvailable_DontCare " 14 "Reserved" ;
VAL_ 2619670270 RequestCounterFrontPTO 15 "NotAvailable_DontCare " 14 "Reserved" ;
VAL_ 2619670270 RequestCounterExternalGuidance 15 "NotAvailable_DontCare " 14 "Reserved" ;
VAL_ 2619670270 FlowRequest_AV32 64511 "ReadyToControl" 64509 "ReleasedControlRequestingOperatorActionBeforeFunctionValueIncreases" 64257 "Float" 64256 "ValveFullyOpened_Retract" 32128 "Block" 0 "ValveFullyOpened_Extend" ;
VAL_ 2619670270 FlowRequest_AV31 64511 "ReadyToControl" 64509 "ReleasedControlRequestingOperatorActionBeforeFunctionValueIncreases" 64257 "Float" 64256 "ValveFullyOpened_Retract" 32128 "Block" 0 "ValveFullyOpened_Extend" ;
VAL_ 2619670270 FlowRequest_AV30 64511 "ReadyToControl" 64509 "ReleasedControlRequestingOperatorActionBeforeFunctionValueIncreases" 64257 "Float" 64256 "ValveFullyOpened_Retract" 32128 "Block" 0 "ValveFullyOpened_Extend" ;
VAL_ 2619670270 FlowRequest_AV29 64511 "ReadyToControl" 64509 "ReleasedControlRequestingOperatorActionBeforeFunctionValueIncreases" 64257 "Float" 64256 "ValveFullyOpened_Retract" 32128 "Block" 0 "ValveFullyOpened_Extend" ;
VAL_ 2619670270 FlowRequest_AV28 64511 "ReadyToControl" 64509 "ReleasedControlRequestingOperatorActionBeforeFunctionValueIncreases" 64257 "Float" 64256 "ValveFullyOpened_Retract" 32128 "Block" 0 "ValveFullyOpened_Extend" ;
VAL_ 2619670270 FlowRequest_AV27 64511 "ReadyToControl" 64509 "ReleasedControlRequestingOperatorActionBeforeFunctionValueIncreases" 64257 "Float" 64256 "ValveFullyOpened_Retract" 32128 "Block" 0 "ValveFullyOpened_Extend" ;
VAL_ 2619670270 FlowRequest_AV26 64511 "ReadyToControl" 64509 "ReleasedControlRequestingOperatorActionBeforeFunctionValueIncreases" 64257 "Float" 64256 "ValveFullyOpened_Retract" 32128 "Block" 0 "ValveFullyOpened_Extend" ;
VAL_ 2619670270 FlowRequest_AV25 64511 "ReadyToControl" 64509 "ReleasedControlRequestingOperatorActionBeforeFunctionValueIncreases" 64257 "Float" 64256 "ValveFullyOpened_Retract" 32128 "Block" 0 "ValveFullyOpened_Extend" ;
VAL_ 2619670270 FlowRequest_AV24 64511 "ReadyToControl" 64509 "ReleasedControlRequestingOperatorActionBeforeFunctionValueIncreases" 64257 "Float" 64256 "ValveFullyOpened_Retract" 32128 "Block" 0 "ValveFullyOpened_Extend" ;
VAL_ 2619670270 FlowRequest_AV23 64511 "ReadyToControl" 64509 "ReleasedControlRequestingOperatorActionBeforeFunctionValueIncreases" 64257 "Float" 64256 "ValveFullyOpened_Retract" 32128 "Block" 0 "ValveFullyOpened_Extend" ;
VAL_ 2619670270 FlowRequest_AV22 64511 "ReadyToControl" 64509 "ReleasedControlRequestingOperatorActionBeforeFunctionValueIncreases" 64257 "Float" 64256 "ValveFullyOpened_Retract" 32128 "Block" 0 "ValveFullyOpened_Extend" ;
VAL_ 2619670270 FlowRequest_AV21 64511 "ReadyToControl" 64509 "ReleasedControlRequestingOperatorActionBeforeFunctionValueIncreases" 64257 "Float" 64256 "ValveFullyOpened_Retract" 32128 "Block" 0 "ValveFullyOpened_Extend" ;
VAL_ 2619670270 FlowRequest_AV20 64511 "ReadyToControl" 64509 "ReleasedControlRequestingOperatorActionBeforeFunctionValueIncreases" 64257 "Float" 64256 "ValveFullyOpened_Retract" 32128 "Block" 0 "ValveFullyOpened_Extend" ;
VAL_ 2619670270 FlowRequest_AV19 64511 "ReadyToControl" 64509 "ReleasedControlRequestingOperatorActionBeforeFunctionValueIncreases" 64257 "Float" 64256 "ValveFullyOpened_Retract" 32128 "Block" 0 "ValveFullyOpened_Extend" ;
VAL_ 2619670270 FlowRequest_AV18 64511 "ReadyToControl" 64509 "ReleasedControlRequestingOperatorActionBeforeFunctionValueIncreases" 64257 "Float" 64256 "ValveFullyOpened_Retract" 32128 "Block" 0 "ValveFullyOpened_Extend" ;
VAL_ 2619670270 FlowRequest_AV17 64511 "ReadyToControl" 64509 "ReleasedControlRequestingOperatorActionBeforeFunctionValueIncreases" 64257 "Float" 64256 "ValveFullyOpened_Retract" 32128 "Block" 0 "ValveFullyOpened_Extend" ;
VAL_ 2619670270 FlowRequest_AV16 64511 "ReadyToControl" 64509 "ReleasedControlRequestingOperatorActionBeforeFunctionValueIncreases" 64257 "Float" 64256 "ValveFullyOpened_Retract" 32128 "Block" 0 "ValveFullyOpened_Extend" ;
VAL_ 2619670270 FlowRequest_AV15 64511 "ReadyToControl" 64509 "ReleasedControlRequestingOperatorActionBeforeFunctionValueIncreases" 64257 "Float" 64256 "ValveFullyOpened_Retract" 32128 "Block" 0 "ValveFullyOpened_Extend" ;
VAL_ 2619670270 FlowRequest_AV14 64511 "ReadyToControl" 64509 "ReleasedControlRequestingOperatorActionBeforeFunctionValueIncreases" 64257 "Float" 64256 "ValveFullyOpened_Retract" 32128 "Block" 0 "ValveFullyOpened_Extend" ;
VAL_ 2619670270 FlowRequest_AV13 64511 "ReadyToControl" 64509 "ReleasedControlRequestingOperatorActionBeforeFunctionValueIncreases" 64257 "Float" 64256 "ValveFullyOpened_Retract" 32128 "Block" 0 "ValveFullyOpened_Extend" ;
VAL_ 2619670270 FlowRequest_AV12 64511 "ReadyToControl" 64509 "ReleasedControlRequestingOperatorActionBeforeFunctionValueIncreases" 64257 "Float" 64256 "ValveFullyOpened_Retract" 32128 "Block" 0 "ValveFullyOpened_Extend" ;
VAL_ 2619670270 FlowRequest_AV11 64511 "ReadyToControl" 64509 "ReleasedControlRequestingOperatorActionBeforeFunctionValueIncreases" 64257 "Float" 64256 "ValveFullyOpened_Retract" 32128 "Block" 0 "ValveFullyOpened_Extend" ;
VAL_ 2619670270 FlowRequest_AV10 64511 "ReadyToControl" 64509 "ReleasedControlRequestingOperatorActionBeforeFunctionValueIncreases" 64257 "Float" 64256 "ValveFullyOpened_Retract" 32128 "Block" 0 "ValveFullyOpened_Extend" ;
VAL_ 2619670270 FlowRequest_AV09 64511 "ReadyToControl" 64509 "ReleasedControlRequestingOperatorActionBeforeFunctionValueIncreases" 64257 "Float" 64256 "ValveFullyOpened_Retract" 32128 "Block" 0 "ValveFullyOpened_Extend" ;
VAL_ 2619670270 FlowRequest_AV08 64511 "ReadyToControl" 64509 "ReleasedControlRequestingOperatorActionBeforeFunctionValueIncreases" 64257 "Float" 64256 "ValveFullyOpened_Retract" 32128 "Block" 0 "ValveFullyOpened_Extend" ;
VAL_ 2619670270 FlowRequest_AV07 64511 "ReadyToControl" 64509 "ReleasedControlRequestingOperatorActionBeforeFunctionValueIncreases" 64257 "Float" 64256 "ValveFullyOpened_Retract" 32128 "Block" 0 "ValveFullyOpened_Extend" ;
VAL_ 2619670270 FlowRequest_AV06 64511 "ReadyToControl" 64509 "ReleasedControlRequestingOperatorActionBeforeFunctionValueIncreases" 64257 "Float" 64256 "ValveFullyOpened_Retract" 32128 "Block" 0 "ValveFullyOpened_Extend" ;
VAL_ 2619670270 FlowRequest_AV05 64511 "ReadyToControl" 64509 "ReleasedControlRequestingOperatorActionBeforeFunctionValueIncreases" 64257 "Float" 64256 "ValveFullyOpened_Retract" 32128 "Block" 0 "ValveFullyOpened_Extend" ;
VAL_ 2619670270 FlowRequest_AV04 64511 "ReadyToControl" 64509 "ReleasedControlRequestingOperatorActionBeforeFunctionValueIncreases" 64257 "Float" 64256 "ValveFullyOpened_Retract" 32128 "Block" 0 "ValveFullyOpened_Extend" ;
VAL_ 2619670270 FlowRequest_AV03 64511 "ReadyToControl" 64509 "ReleasedControlRequestingOperatorActionBeforeFunctionValueIncreases" 64257 "Float" 64256 "ValveFullyOpened_Retract" 32128 "Block" 0 "ValveFullyOpened_Extend" ;
VAL_ 2619670270 FlowRequest_AV02 64511 "ReadyToControl" 64509 "ReleasedControlRequestingOperatorActionBeforeFunctionValueIncreases" 64257 "Float" 64256 "ValveFullyOpened_Retract" 32128 "Block" 0 "ValveFullyOpened_Extend" ;
VAL_ 2619670270 RearHitchPosRequest 10000 "FullRaise" 64259 "RaiseUntilStopRequest" 64258 "LowerUntilStopRequest" 0 "FullLower" 64511 "ReadyToControl" 64509 "ReleaseControlRequestingOperatorAction" 64257 "Stop" 64256 "Float" ;
VAL_ 2619670270 RearPTOSpeedRequest 64511 "ReadyToControl" 64509 "RequestingOperatorAction" 64256 "On_SpeedClockwiseSetByTimServer" 32128 "Off" 0 "On_SpeedCounterClockwiseSetByTimServer" ;
VAL_ 2619670270 CurvatureRequest 64511 "ReadyToControl" 64509 "RequestingOperatorAwareness" 32128 "Straight" ;
VAL_ 2619670270 VehicleSpeedRequest 64511 "ReadyToControl" 64510 "AcceptFunctionWithoutOperatorAwareness" 64509 "RequestingOperatorAwareness" 64256 "ForwardSpeedSetByTimServer" 32128 "Stop" 0 "ReverseSpeedSetByTimServer" ;
VAL_ 2619670270 FrontHitchPosRequest 10000 "FullRaise" 64259 "RaiseUntilStopRequest" 64258 "LowerUntilStopRequest" 0 "FullLower" 64511 "ReadyToControl" 64509 "ReleaseControlRequestingOperatorAction" 64257 "Stop" 64256 "Float" ;
VAL_ 2619670270 FrontPTOSpeedRequest 64511 "ReadyToControl" 64509 "RequestingOperatorAction" 64256 "On_SpeedClockwiseSetByTimServer" 32128 "Off" 0 "On_SpeedCounterClockwiseSetByTimServer" ;
VAL_ 2619670270 FlowRequest_AV01 65535 "NotAvailable" 65534 "Error" 64511 "ReadyToControl" 64509 "ReleasedControlRequestingOperatorActionBeforeFunctionValueIncreases" 64257 "Float" 64256 "ValveFullyOpened_Retract" 32128 "Block" 0 "ValveFullyOpened_Extend" ;
VAL_ 2619670270 TIMClientState 13 "AutomationFault" 5 "AutomationActive" 15 "NotAvailable" 14 "Error" 3 "AutomationEnabled" 2 "AutomationReadyToEnable" 1 "AutomationNotReady" 0 "AutomationUnavailable" ;
VAL_ 2619670270 ClientHeartbeatCounter 255 "GracefulShutdown" 254 "ErrorConditionOnSender" 251 "ResetOfHeartbeatCounter" ;
VAL_ 2619670270 TIMFunctionId_4 72 "RearTopLinkage" 71 "FrontTopLinkage" 32 "AuxValve32" 70 "ExternalGuidance" 68 "VehicleSpeed" 67 "RearHitch" 66 "FrontHitch" 65 "RearPTO" 64 "FrontPTO" 31 "AuxValve31" 30 "AuxValve30" 29 "AuxValve29" 28 "AuxValve28" 27 "AuxValve27" 26 "AuxValve26" 25 "AuxValve25" 24 "AuxValve24" 23 "AuxValve23" 22 "AuxValve22" 21 "AuxValve21" 20 "AuxValve20" 19 "AuxValve19" 18 "AuxValve18" 17 "AuxValve17" 16 "AuxValve16" 15 "AuxValve15" 14 "AuxValve14" 13 "AuxValve13" 12 "AuxValve12" 11 "AuxValve11" 10 "AuxValve10" 9 "AuxValve9" 8 "AuxValve8" 7 "AuxValve7" 6 "AuxValve6" 5 "AuxValve5" 4 "AuxValve4" 3 "AuxValve3" 2 "AuxValve2" 1 "AuxValve1" ;
VAL_ 2619670270 TIMFunctionId_3 72 "RearTopLinkage" 71 "FrontTopLinkage" 32 "AuxValve32" 70 "ExternalGuidance" 68 "VehicleSpeed" 67 "RearHitch" 66 "FrontHitch" 65 "RearPTO" 64 "FrontPTO" 31 "AuxValve31" 30 "AuxValve30" 29 "AuxValve29" 28 "AuxValve28" 27 "AuxValve27" 26 "AuxValve26" 25 "AuxValve25" 24 "AuxValve24" 23 "AuxValve23" 22 "AuxValve22" 21 "AuxValve21" 20 "AuxValve20" 19 "AuxValve19" 18 "AuxValve18" 17 "AuxValve17" 16 "AuxValve16" 15 "AuxValve15" 14 "AuxValve14" 13 "AuxValve13" 12 "AuxValve12" 11 "AuxValve11" 10 "AuxValve10" 9 "AuxValve9" 8 "AuxValve8" 7 "AuxValve7" 6 "AuxValve6" 5 "AuxValve5" 4 "AuxValve4" 3 "AuxValve3" 2 "AuxValve2" 1 "AuxValve1" ;
VAL_ 2619670270 TIMFunctionId_2 72 "RearTopLinkage" 71 "FrontTopLinkage" 32 "AuxValve32" 70 "ExternalGuidance" 68 "VehicleSpeed" 67 "RearHitch" 66 "FrontHitch" 65 "RearPTO" 64 "FrontPTO" 31 "AuxValve31" 30 "AuxValve30" 29 "AuxValve29" 28 "AuxValve28" 27 "AuxValve27" 26 "AuxValve26" 25 "AuxValve25" 24 "AuxValve24" 23 "AuxValve23" 22 "AuxValve22" 21 "AuxValve21" 20 "AuxValve20" 19 "AuxValve19" 18 "AuxValve18" 17 "AuxValve17" 16 "AuxValve16" 15 "AuxValve15" 14 "AuxValve14" 13 "AuxValve13" 12 "AuxValve12" 11 "AuxValve11" 10 "AuxValve10" 9 "AuxValve9" 8 "AuxValve8" 7 "AuxValve7" 6 "AuxValve6" 5 "AuxValve5" 4 "AuxValve4" 3 "AuxValve3" 2 "AuxValve2" 1 "AuxValve1" ;
VAL_ 2619670270 TIMFunctionId_1 72 "RearTopLinkage" 71 "FrontTopLinkage" 32 "AuxValve32" 70 "ExternalGuidance" 68 "VehicleSpeed" 67 "RearHitch" 66 "FrontHitch" 65 "RearPTO" 64 "FrontPTO" 31 "AuxValve31" 30 "AuxValve30" 29 "AuxValve29" 28 "AuxValve28" 27 "AuxValve27" 26 "AuxValve26" 25 "AuxValve25" 24 "AuxValve24" 23 "AuxValve23" 22 "AuxValve22" 21 "AuxValve21" 20 "AuxValve20" 19 "AuxValve19" 18 "AuxValve18" 17 "AuxValve17" 16 "AuxValve16" 15 "AuxValve15" 14 "AuxValve14" 13 "AuxValve13" 12 "AuxValve12" 11 "AuxValve11" 10 "AuxValve10" 9 "AuxValve9" 8 "AuxValve8" 7 "AuxValve7" 6 "AuxValve6" 5 "AuxValve5" 4 "AuxValve4" 3 "AuxValve3" 2 "AuxValve2" 1 "AuxValve1" ;
VAL_ 2619670270 RequestType_4 7 "DontCare" 6 "Error" 1 "AssignToRequestingClient" 0 "ReleaseAssignmentOfRequestingClient" ;
VAL_ 2619670270 RequestType_3 7 "DontCare" 6 "Error" 1 "AssignToRequestingClient" 0 "ReleaseAssignmentOfRequestingClient" ;
VAL_ 2619670270 RequestType_2 7 "DontCare" 6 "Error" 1 "AssignToRequestingClient" 0 "ReleaseAssignmentOfRequestingClient" ;
VAL_ 2619670270 RequestType_1 7 "DontCare" 6 "Error" 1 "AssignToRequestingClient" 0 "ReleaseAssignmentOfRequestingClient" ;
VAL_ 2619670270 TIMMessageType 1 "TIMFunctionStatus" 0 "TIMFunctionRequest" ;
VAL_ 2619670270 GroupFunctionValue 32 "TIM_AuxValve32Request" 249 "ClientStatus" 248 "ServerVersionRequest" 247 "ClientVersionResponse" 246 "ConnectionVersionRequest" 245 "FunctionsAssignmentRequest" 244 "FunctionsSupportRequest" 243 "FunctionsAssignmentStatusRequest" 70 "ExternalGuidanceRequest" 68 "VehicleSpeedRequest" 67 "RearHitchRequest" 66 "FrontHitchRequest" 65 "RearPTORequest" 64 "FrontPTORequest" 31 "TIM_AuxValve31Request" 30 "TIM_AuxValve30Request" 29 "TIM_AuxValve29Request" 28 "TIM_AuxValve28Request" 27 "TIM_AuxValve27Request" 26 "TIM_AuxValve26Request" 25 "TIM_AuxValve25Request" 24 "TIM_AuxValve24Request" 23 "TIM_AuxValve23Request" 22 "TIM_AuxValve22Request" 21 "TIM_AuxValve21Request" 20 "TIM_AuxValve20Request" 19 "TIM_AuxValve19Request" 18 "TIM_AuxValve18Request" 17 "TIM_AuxValve17Request" 16 "TIM_AuxValve16Request" 15 "TIM_AuxValve15Request" 14 "TIM_AuxValve14Request" 13 "TIM_AuxValve13Request" 12 "TIM_AuxValve12Request" 11 "TIM_AuxValve11Request" 10 "TIM_AuxValve10Request" 9 "TIM_AuxValve9Request" 8 "TIM_AuxValve8Request" 7 "TIM_AuxValve7Request" 6 "TIM_AuxValve6Request" 5 "TIM_AuxValve5Request" 4 "TIM_AuxValve4Request" 3 "TIM_AuxValve3Request" 2 "TIM_AuxValve2Request" 1 "TIM_AuxValve1Request" ;
VAL_ 2619604734 GroupFunctionValue 32 "TIM_AuxValve32Status" 243 "FunctionsAssignmentStatusResponse" 250 "ServerStatus" 248 "ServerVersionResponse" 247 "ClientVersionRequest" 246 "ConnectionVersionResponse" 245 "FunctionsAssignmentResponse" 244 "FunctionsSupportResponse" 70 "ExternalGuidanceStatus" 68 "VehicleSpeedStatus" 67 "RearHitchStatus" 66 "FrontHitchStatus" 65 "RearPTOStatus" 64 "FrontPTOStatus" 31 "TIM_AuxValve31Status" 30 "TIM_AuxValve30Status" 29 "TIM_AuxValve29Status" 28 "TIM_AuxValve28Status" 27 "TIM_AuxValve27Status" 26 "TIM_AuxValve26Status" 25 "TIM_AuxValve25Status" 24 "TIM_AuxValve24Status" 23 "TIM_AuxValve23Status" 22 "TIM_AuxValve22Status" 21 "TIM_AuxValve21Status" 20 "TIM_AuxValve20Status" 19 "TIM_AuxValve19Status" 18 "TIM_AuxValve18Status" 17 "TIM_AuxValve17Status" 16 "TIM_AuxValve16Status" 15 "TIM_AuxValve15Status" 14 "TIM_AuxValve14Status" 13 "TIM_AuxValve13Status" 12 "TIM_AuxValve12Status" 11 "TIM_AuxValve11Status" 10 "TIM_AuxValve10Status" 9 "TIM_AuxValve9Status" 8 "TIM_AuxValve8Status" 7 "TIM_AuxValve7Status" 6 "TIM_AuxValve6Status" 5 "TIM_AuxValve5Status" 4 "TIM_AuxValve4Status" 3 "TIM_AuxValve3Status" 2 "TIM_AuxValve2Status" 1 "TIM_AuxValve1Status" ;
VAL_ 2619604734 RearHitchPosition 65535 "NotAvailable" 65534 "Error" 64259 "Raising" 64258 "Lowering" 64257 "Stop" 10000 "FullRaise" 0 "FullLower" 64256 "Float" ;
VAL_ 2619604734 RearPTOSpeed 65535 "NotAvailable" 65534 "Error" ;
VAL_ 2619604734 FlowAuxValve32 65535 "NotAvailable" 65534 "Error" 64257 "Float" 64256 "ValveFullyOpened_Retract" 32128 "NoFlow_Block" 0 "ValveFullyOpened_Extend" ;
VAL_ 2619604734 FlowAuxValve31 65535 "NotAvailable" 65534 "Error" 64257 "Float" 64256 "ValveFullyOpened_Retract" 32128 "NoFlow_Block" 0 "ValveFullyOpened_Extend" ;
VAL_ 2619604734 FlowAuxValve30 65535 "NotAvailable" 65534 "Error" 64257 "Float" 64256 "ValveFullyOpened_Retract" 32128 "NoFlow_Block" 0 "ValveFullyOpened_Extend" ;
VAL_ 2619604734 FlowAuxValve29 65535 "NotAvailable" 65534 "Error" 64257 "Float" 64256 "ValveFullyOpened_Retract" 32128 "NoFlow_Block" 0 "ValveFullyOpened_Extend" ;
VAL_ 2619604734 FlowAuxValve28 65535 "NotAvailable" 65534 "Error" 64257 "Float" 64256 "ValveFullyOpened_Retract" 32128 "NoFlow_Block" 0 "ValveFullyOpened_Extend" ;
VAL_ 2619604734 FlowAuxValve27 65535 "NotAvailable" 65534 "Error" 64257 "Float" 64256 "ValveFullyOpened_Retract" 32128 "NoFlow_Block" 0 "ValveFullyOpened_Extend" ;
VAL_ 2619604734 FlowAuxValve26 65535 "NotAvailable" 65534 "Error" 64257 "Float" 64256 "ValveFullyOpened_Retract" 32128 "NoFlow_Block" 0 "ValveFullyOpened_Extend" ;
VAL_ 2619604734 FlowAuxValve25 65535 "NotAvailable" 65534 "Error" 64257 "Float" 64256 "ValveFullyOpened_Retract" 32128 "NoFlow_Block" 0 "ValveFullyOpened_Extend" ;
VAL_ 2619604734 FlowAuxValve24 65535 "NotAvailable" 65534 "Error" 64257 "Float" 64256 "ValveFullyOpened_Retract" 32128 "NoFlow_Block" 0 "ValveFullyOpened_Extend" ;
VAL_ 2619604734 FlowAuxValve23 65535 "NotAvailable" 65534 "Error" 64257 "Float" 64256 "ValveFullyOpened_Retract" 32128 "NoFlow_Block" 0 "ValveFullyOpened_Extend" ;
VAL_ 2619604734 FlowAuxValve22 65535 "NotAvailable" 65534 "Error" 64257 "Float" 64256 "ValveFullyOpened_Retract" 32128 "NoFlow_Block" 0 "ValveFullyOpened_Extend" ;
VAL_ 2619604734 FlowAuxValve21 65535 "NotAvailable" 65534 "Error" 64257 "Float" 64256 "ValveFullyOpened_Retract" 32128 "NoFlow_Block" 0 "ValveFullyOpened_Extend" ;
VAL_ 2619604734 FlowAuxValve20 65535 "NotAvailable" 65534 "Error" 64257 "Float" 64256 "ValveFullyOpened_Retract" 32128 "NoFlow_Block" 0 "ValveFullyOpened_Extend" ;
VAL_ 2619604734 FlowAuxValve19 65535 "NotAvailable" 65534 "Error" 64257 "Float" 64256 "ValveFullyOpened_Retract" 32128 "NoFlow_Block" 0 "ValveFullyOpened_Extend" ;
VAL_ 2619604734 FlowAuxValve18 65535 "NotAvailable" 65534 "Error" 64257 "Float" 64256 "ValveFullyOpened_Retract" 32128 "NoFlow_Block" 0 "ValveFullyOpened_Extend" ;
VAL_ 2619604734 FlowAuxValve17 65535 "NotAvailable" 65534 "Error" 64257 "Float" 64256 "ValveFullyOpened_Retract" 32128 "NoFlow_Block" 0 "ValveFullyOpened_Extend" ;
VAL_ 2619604734 FlowAuxValve16 65535 "NotAvailable" 65534 "Error" 64257 "Float" 64256 "ValveFullyOpened_Retract" 32128 "NoFlow_Block" 0 "ValveFullyOpened_Extend" ;
VAL_ 2619604734 FlowAuxValve15 65535 "NotAvailable" 65534 "Error" 64257 "Float" 64256 "ValveFullyOpened_Retract" 32128 "NoFlow_Block" 0 "ValveFullyOpened_Extend" ;
VAL_ 2619604734 FlowAuxValve14 65535 "NotAvailable" 65534 "Error" 64257 "Float" 64256 "ValveFullyOpened_Retract" 32128 "NoFlow_Block" 0 "ValveFullyOpened_Extend" ;
VAL_ 2619604734 FlowAuxValve13 65535 "NotAvailable" 65534 "Error" 64257 "Float" 64256 "ValveFullyOpened_Retract" 32128 "NoFlow_Block" 0 "ValveFullyOpened_Extend" ;
VAL_ 2619604734 FlowAuxValve12 65535 "NotAvailable" 65534 "Error" 64257 "Float" 64256 "ValveFullyOpened_Retract" 32128 "NoFlow_Block" 0 "ValveFullyOpened_Extend" ;
VAL_ 2619604734 FlowAuxValve11 65535 "NotAvailable" 65534 "Error" 64257 "Float" 64256 "ValveFullyOpened_Retract" 32128 "NoFlow_Block" 0 "ValveFullyOpened_Extend" ;
VAL_ 2619604734 FlowAuxValve10 65535 "NotAvailable" 65534 "Error" 64257 "Float" 64256 "ValveFullyOpened_Retract" 32128 "NoFlow_Block" 0 "ValveFullyOpened_Extend" ;
VAL_ 2619604734 FlowAuxValve09 65535 "NotAvailable" 65534 "Error" 64257 "Float" 64256 "ValveFullyOpened_Retract" 32128 "NoFlow_Block" 0 "ValveFullyOpened_Extend" ;
VAL_ 2619604734 FlowAuxValve08 65535 "NotAvailable" 65534 "Error" 64257 "Float" 64256 "ValveFullyOpened_Retract" 32128 "NoFlow_Block" 0 "ValveFullyOpened_Extend" ;
VAL_ 2619604734 FlowAuxValve07 65535 "NotAvailable" 65534 "Error" 64257 "Float" 64256 "ValveFullyOpened_Retract" 32128 "NoFlow_Block" 0 "ValveFullyOpened_Extend" ;
VAL_ 2619604734 FlowAuxValve06 65535 "NotAvailable" 65534 "Error" 64257 "Float" 64256 "ValveFullyOpened_Retract" 32128 "NoFlow_Block" 0 "ValveFullyOpened_Extend" ;
VAL_ 2619604734 FlowAuxValve05 65535 "NotAvailable" 65534 "Error" 64257 "Float" 64256 "ValveFullyOpened_Retract" 32128 "NoFlow_Block" 0 "ValveFullyOpened_Extend" ;
VAL_ 2619604734 FlowAuxValve04 65535 "NotAvailable" 65534 "Error" 64257 "Float" 64256 "ValveFullyOpened_Retract" 32128 "NoFlow_Block" 0 "ValveFullyOpened_Extend" ;
VAL_ 2619604734 FlowAuxValve03 65535 "NotAvailable" 65534 "Error" 64257 "Float" 64256 "ValveFullyOpened_Retract" 32128 "NoFlow_Block" 0 "ValveFullyOpened_Extend" ;
VAL_ 2619604734 FlowAuxValve02 65535 "NotAvailable" 65534 "Error" 64257 "Float" 64256 "ValveFullyOpened_Retract" 32128 "NoFlow_Block" 0 "ValveFullyOpened_Extend" ;
VAL_ 2619604734 FlowTypeAuxValve32 3 "NotAvailable" 2 "Error" 1 "Measured" 0 "Estimated" ;
VAL_ 2619604734 FlowTypeAuxValve31 3 "NotAvailable" 2 "Error" 1 "Measured" 0 "Estimated" ;
VAL_ 2619604734 FlowTypeAuxValve30 3 "NotAvailable" 2 "Error" 1 "Measured" 0 "Estimated" ;
VAL_ 2619604734 FlowTypeAuxValve29 3 "NotAvailable" 2 "Error" 1 "Measured" 0 "Estimated" ;
VAL_ 2619604734 FlowTypeAuxValve28 3 "NotAvailable" 2 "Error" 1 "Measured" 0 "Estimated" ;
VAL_ 2619604734 FlowTypeAuxValve27 3 "NotAvailable" 2 "Error" 1 "Measured" 0 "Estimated" ;
VAL_ 2619604734 FlowTypeAuxValve26 3 "NotAvailable" 2 "Error" 1 "Measured" 0 "Estimated" ;
VAL_ 2619604734 FlowTypeAuxValve25 3 "NotAvailable" 2 "Error" 1 "Measured" 0 "Estimated" ;
VAL_ 2619604734 FlowTypeAuxValve24 3 "NotAvailable" 2 "Error" 1 "Measured" 0 "Estimated" ;
VAL_ 2619604734 FlowTypeAuxValve23 3 "NotAvailable" 2 "Error" 1 "Measured" 0 "Estimated" ;
VAL_ 2619604734 FlowTypeAuxValve22 3 "NotAvailable" 2 "Error" 1 "Measured" 0 "Estimated" ;
VAL_ 2619604734 FlowTypeAuxValve21 3 "NotAvailable" 2 "Error" 1 "Measured" 0 "Estimated" ;
VAL_ 2619604734 FlowTypeAuxValve20 3 "NotAvailable" 2 "Error" 1 "Measured" 0 "Estimated" ;
VAL_ 2619604734 FlowTypeAuxValve19 3 "NotAvailable" 2 "Error" 1 "Measured" 0 "Estimated" ;
VAL_ 2619604734 FlowTypeAuxValve18 3 "NotAvailable" 2 "Error" 1 "Measured" 0 "Estimated" ;
VAL_ 2619604734 FlowTypeAuxValve17 3 "NotAvailable" 2 "Error" 1 "Measured" 0 "Estimated" ;
VAL_ 2619604734 FlowTypeAuxValve16 3 "NotAvailable" 2 "Error" 1 "Measured" 0 "Estimated" ;
VAL_ 2619604734 FlowTypeAuxValve15 3 "NotAvailable" 2 "Error" 1 "Measured" 0 "Estimated" ;
VAL_ 2619604734 FlowTypeAuxValve14 3 "NotAvailable" 2 "Error" 1 "Measured" 0 "Estimated" ;
VAL_ 2619604734 FlowTypeAuxValve13 3 "NotAvailable" 2 "Error" 1 "Measured" 0 "Estimated" ;
VAL_ 2619604734 FlowTypeAuxValve12 3 "NotAvailable" 2 "Error" 1 "Measured" 0 "Estimated" ;
VAL_ 2619604734 FlowTypeAuxValve11 3 "NotAvailable" 2 "Error" 1 "Measured" 0 "Estimated" ;
VAL_ 2619604734 FlowTypeAuxValve10 3 "NotAvailable" 2 "Error" 1 "Measured" 0 "Estimated" ;
VAL_ 2619604734 FlowTypeAuxValve09 3 "NotAvailable" 2 "Error" 1 "Measured" 0 "Estimated" ;
VAL_ 2619604734 FlowTypeAuxValve08 3 "NotAvailable" 2 "Error" 1 "Measured" 0 "Estimated" ;
VAL_ 2619604734 FlowTypeAuxValve07 3 "NotAvailable" 2 "Error" 1 "Measured" 0 "Estimated" ;
VAL_ 2619604734 FlowTypeAuxValve06 3 "NotAvailable" 2 "Error" 1 "Measured" 0 "Estimated" ;
VAL_ 2619604734 FlowTypeAuxValve05 3 "NotAvailable" 2 "Error" 1 "Measured" 0 "Estimated" ;
VAL_ 2619604734 FlowTypeAuxValve04 3 "NotAvailable" 2 "Error" 1 "Measured" 0 "Estimated" ;
VAL_ 2619604734 FlowTypeAuxValve03 3 "NotAvailable" 2 "Error" 1 "Measured" 0 "Estimated" ;
VAL_ 2619604734 FlowTypeAuxValve02 3 "NotAvailable" 2 "Error" 1 "Measured" 0 "Estimated" ;
VAL_ 2619604734 FlowTypeAuxValve01 3 "NotAvailable" 2 "Error" 1 "Measured" 0 "Estimated" ;
VAL_ 2619604734 ExitReasonCodeRearPTO 31 "NotAvailable" 30 "Error" 15 "InvalidPtoGear" 9 "FunctionFault" 8 "OperatorControlFault" 5 "RemoteCommandTimeout" 4 "OperatorControlNotInValidPosition" 3 "OperatorOverrideOfFunction" 2 "ImplementReleasedControlOfFunction" 7 "FunctionNotCalibrated" 6 "RemoteCommandOutOfRange_Invalid" 1 "RequiredLevelOfOperatorPresence_AwarenessNotDetected" 0 "NoReason_AllClear" ;
VAL_ 2619604734 ExitReasonCodeRearHitch 16 "HitchLockedOut" 31 "NotAvailable" 30 "Error" 15 "HydraulicOilLevelLow" 9 "FunctionFault" 8 "OperatorControlFault" 5 "RemoteCommandTimeout" 4 "OperatorControlNotInValidPosition" 3 "OperatorOverrideOfFunction" 2 "ImplementReleasedControlOfFunction" 7 "FunctionNotCalibrated" 6 "RemoteCommandOutOfRangeOrInvalid" 1 "RequiredLevelOfOperatorPresence_AwarenessNotDetected" 0 "NoReason_AllClear" ;
VAL_ 2619604734 ExitReasonCodeAuxValve32 31 "NotAvailable" 30 "Error" 16 "ValveLockedOut_TransportLock" 15 "HydraulicOilLevelLow" 9 "FunctionFault" 8 "OperatorControlFault" 5 "RemoteCommandTimeout" 4 "OperatorControlNotInValidPosition" 3 "OperatorOverrideOfFunction" 2 "ImplementReleasedControlOfFunction" 7 "FunctionNotCalibrated" 6 "RemoteCommandOutOfRange_Invalid" 1 "RequiredLevelOfOperatorPresence_AwarenessNotDetected" 0 "NoReason_AllClear" ;
VAL_ 2619604734 ExitReasonCodeAuxValve31 31 "NotAvailable" 30 "Error" 16 "ValveLockedOut_TransportLock" 15 "HydraulicOilLevelLow" 9 "FunctionFault" 8 "OperatorControlFault" 5 "RemoteCommandTimeout" 4 "OperatorControlNotInValidPosition" 3 "OperatorOverrideOfFunction" 2 "ImplementReleasedControlOfFunction" 7 "FunctionNotCalibrated" 6 "RemoteCommandOutOfRange_Invalid" 1 "RequiredLevelOfOperatorPresence_AwarenessNotDetected" 0 "NoReason_AllClear" ;
VAL_ 2619604734 ExitReasonCodeAuxValve30 31 "NotAvailable" 30 "Error" 16 "ValveLockedOut_TransportLock" 15 "HydraulicOilLevelLow" 9 "FunctionFault" 8 "OperatorControlFault" 5 "RemoteCommandTimeout" 4 "OperatorControlNotInValidPosition" 3 "OperatorOverrideOfFunction" 2 "ImplementReleasedControlOfFunction" 7 "FunctionNotCalibrated" 6 "RemoteCommandOutOfRange_Invalid" 1 "RequiredLevelOfOperatorPresence_AwarenessNotDetected" 0 "NoReason_AllClear" ;
VAL_ 2619604734 ExitReasonCodeAuxValve29 31 "NotAvailable" 30 "Error" 16 "ValveLockedOut_TransportLock" 15 "HydraulicOilLevelLow" 9 "FunctionFault" 8 "OperatorControlFault" 5 "RemoteCommandTimeout" 4 "OperatorControlNotInValidPosition" 3 "OperatorOverrideOfFunction" 2 "ImplementReleasedControlOfFunction" 7 "FunctionNotCalibrated" 6 "RemoteCommandOutOfRange_Invalid" 1 "RequiredLevelOfOperatorPresence_AwarenessNotDetected" 0 "NoReason_AllClear" ;
VAL_ 2619604734 ExitReasonCodeAuxValve28 31 "NotAvailable" 30 "Error" 16 "ValveLockedOut_TransportLock" 15 "HydraulicOilLevelLow" 9 "FunctionFault" 8 "OperatorControlFault" 5 "RemoteCommandTimeout" 4 "OperatorControlNotInValidPosition" 3 "OperatorOverrideOfFunction" 2 "ImplementReleasedControlOfFunction" 7 "FunctionNotCalibrated" 6 "RemoteCommandOutOfRange_Invalid" 1 "RequiredLevelOfOperatorPresence_AwarenessNotDetected" 0 "NoReason_AllClear" ;
VAL_ 2619604734 ExitReasonCodeAuxValve27 31 "NotAvailable" 30 "Error" 16 "ValveLockedOut_TransportLock" 15 "HydraulicOilLevelLow" 9 "FunctionFault" 8 "OperatorControlFault" 5 "RemoteCommandTimeout" 4 "OperatorControlNotInValidPosition" 3 "OperatorOverrideOfFunction" 2 "ImplementReleasedControlOfFunction" 7 "FunctionNotCalibrated" 6 "RemoteCommandOutOfRange_Invalid" 1 "RequiredLevelOfOperatorPresence_AwarenessNotDetected" 0 "NoReason_AllClear" ;
VAL_ 2619604734 ExitReasonCodeAuxValve26 31 "NotAvailable" 30 "Error" 16 "ValveLockedOut_TransportLock" 15 "HydraulicOilLevelLow" 9 "FunctionFault" 8 "OperatorControlFault" 5 "RemoteCommandTimeout" 4 "OperatorControlNotInValidPosition" 3 "OperatorOverrideOfFunction" 2 "ImplementReleasedControlOfFunction" 7 "FunctionNotCalibrated" 6 "RemoteCommandOutOfRange_Invalid" 1 "RequiredLevelOfOperatorPresence_AwarenessNotDetected" 0 "NoReason_AllClear" ;
VAL_ 2619604734 ExitReasonCodeAuxValve25 31 "NotAvailable" 30 "Error" 16 "ValveLockedOut_TransportLock" 15 "HydraulicOilLevelLow" 9 "FunctionFault" 8 "OperatorControlFault" 5 "RemoteCommandTimeout" 4 "OperatorControlNotInValidPosition" 3 "OperatorOverrideOfFunction" 2 "ImplementReleasedControlOfFunction" 7 "FunctionNotCalibrated" 6 "RemoteCommandOutOfRange_Invalid" 1 "RequiredLevelOfOperatorPresence_AwarenessNotDetected" 0 "NoReason_AllClear" ;
VAL_ 2619604734 ExitReasonCodeAuxValve24 31 "NotAvailable" 30 "Error" 16 "ValveLockedOut_TransportLock" 15 "HydraulicOilLevelLow" 9 "FunctionFault" 8 "OperatorControlFault" 5 "RemoteCommandTimeout" 4 "OperatorControlNotInValidPosition" 3 "OperatorOverrideOfFunction" 2 "ImplementReleasedControlOfFunction" 7 "FunctionNotCalibrated" 6 "RemoteCommandOutOfRange_Invalid" 1 "RequiredLevelOfOperatorPresence_AwarenessNotDetected" 0 "NoReason_AllClear" ;
VAL_ 2619604734 ExitReasonCodeAuxValve23 31 "NotAvailable" 30 "Error" 16 "ValveLockedOut_TransportLock" 15 "HydraulicOilLevelLow" 9 "FunctionFault" 8 "OperatorControlFault" 5 "RemoteCommandTimeout" 4 "OperatorControlNotInValidPosition" 3 "OperatorOverrideOfFunction" 2 "ImplementReleasedControlOfFunction" 7 "FunctionNotCalibrated" 6 "RemoteCommandOutOfRange_Invalid" 1 "RequiredLevelOfOperatorPresence_AwarenessNotDetected" 0 "NoReason_AllClear" ;
VAL_ 2619604734 ExitReasonCodeAuxValve22 31 "NotAvailable" 30 "Error" 16 "ValveLockedOut_TransportLock" 15 "HydraulicOilLevelLow" 9 "FunctionFault" 8 "OperatorControlFault" 5 "RemoteCommandTimeout" 4 "OperatorControlNotInValidPosition" 3 "OperatorOverrideOfFunction" 2 "ImplementReleasedControlOfFunction" 7 "FunctionNotCalibrated" 6 "RemoteCommandOutOfRange_Invalid" 1 "RequiredLevelOfOperatorPresence_AwarenessNotDetected" 0 "NoReason_AllClear" ;
VAL_ 2619604734 ExitReasonCodeAuxValve21 31 "NotAvailable" 30 "Error" 16 "ValveLockedOut_TransportLock" 15 "HydraulicOilLevelLow" 9 "FunctionFault" 8 "OperatorControlFault" 5 "RemoteCommandTimeout" 4 "OperatorControlNotInValidPosition" 3 "OperatorOverrideOfFunction" 2 "ImplementReleasedControlOfFunction" 7 "FunctionNotCalibrated" 6 "RemoteCommandOutOfRange_Invalid" 1 "RequiredLevelOfOperatorPresence_AwarenessNotDetected" 0 "NoReason_AllClear" ;
VAL_ 2619604734 ExitReasonCodeAuxValve20 31 "NotAvailable" 30 "Error" 16 "ValveLockedOut_TransportLock" 15 "HydraulicOilLevelLow" 9 "FunctionFault" 8 "OperatorControlFault" 5 "RemoteCommandTimeout" 4 "OperatorControlNotInValidPosition" 3 "OperatorOverrideOfFunction" 2 "ImplementReleasedControlOfFunction" 7 "FunctionNotCalibrated" 6 "RemoteCommandOutOfRange_Invalid" 1 "RequiredLevelOfOperatorPresence_AwarenessNotDetected" 0 "NoReason_AllClear" ;
VAL_ 2619604734 ExitReasonCodeAuxValve19 31 "NotAvailable" 30 "Error" 16 "ValveLockedOut_TransportLock" 15 "HydraulicOilLevelLow" 9 "FunctionFault" 8 "OperatorControlFault" 5 "RemoteCommandTimeout" 4 "OperatorControlNotInValidPosition" 3 "OperatorOverrideOfFunction" 2 "ImplementReleasedControlOfFunction" 7 "FunctionNotCalibrated" 6 "RemoteCommandOutOfRange_Invalid" 1 "RequiredLevelOfOperatorPresence_AwarenessNotDetected" 0 "NoReason_AllClear" ;
VAL_ 2619604734 ExitReasonCodeAuxValve18 31 "NotAvailable" 30 "Error" 16 "ValveLockedOut_TransportLock" 15 "HydraulicOilLevelLow" 9 "FunctionFault" 8 "OperatorControlFault" 5 "RemoteCommandTimeout" 4 "OperatorControlNotInValidPosition" 3 "OperatorOverrideOfFunction" 2 "ImplementReleasedControlOfFunction" 7 "FunctionNotCalibrated" 6 "RemoteCommandOutOfRange_Invalid" 1 "RequiredLevelOfOperatorPresence_AwarenessNotDetected" 0 "NoReason_AllClear" ;
VAL_ 2619604734 ExitReasonCodeAuxValve17 31 "NotAvailable" 30 "Error" 16 "ValveLockedOut_TransportLock" 15 "HydraulicOilLevelLow" 9 "FunctionFault" 8 "OperatorControlFault" 5 "RemoteCommandTimeout" 4 "OperatorControlNotInValidPosition" 3 "OperatorOverrideOfFunction" 2 "ImplementReleasedControlOfFunction" 7 "FunctionNotCalibrated" 6 "RemoteCommandOutOfRange_Invalid" 1 "RequiredLevelOfOperatorPresence_AwarenessNotDetected" 0 "NoReason_AllClear" ;
VAL_ 2619604734 ExitReasonCodeAuxValve16 31 "NotAvailable" 30 "Error" 16 "ValveLockedOut_TransportLock" 15 "HydraulicOilLevelLow" 9 "FunctionFault" 8 "OperatorControlFault" 5 "RemoteCommandTimeout" 4 "OperatorControlNotInValidPosition" 3 "OperatorOverrideOfFunction" 2 "ImplementReleasedControlOfFunction" 7 "FunctionNotCalibrated" 6 "RemoteCommandOutOfRange_Invalid" 1 "RequiredLevelOfOperatorPresence_AwarenessNotDetected" 0 "NoReason_AllClear" ;
VAL_ 2619604734 ExitReasonCodeAuxValve15 31 "NotAvailable" 30 "Error" 16 "ValveLockedOut_TransportLock" 15 "HydraulicOilLevelLow" 9 "FunctionFault" 8 "OperatorControlFault" 5 "RemoteCommandTimeout" 4 "OperatorControlNotInValidPosition" 3 "OperatorOverrideOfFunction" 2 "ImplementReleasedControlOfFunction" 7 "FunctionNotCalibrated" 6 "RemoteCommandOutOfRange_Invalid" 1 "RequiredLevelOfOperatorPresence_AwarenessNotDetected" 0 "NoReason_AllClear" ;
VAL_ 2619604734 ExitReasonCodeAuxValve14 31 "NotAvailable" 30 "Error" 16 "ValveLockedOut_TransportLock" 15 "HydraulicOilLevelLow" 9 "FunctionFault" 8 "OperatorControlFault" 5 "RemoteCommandTimeout" 4 "OperatorControlNotInValidPosition" 3 "OperatorOverrideOfFunction" 2 "ImplementReleasedControlOfFunction" 7 "FunctionNotCalibrated" 6 "RemoteCommandOutOfRange_Invalid" 1 "RequiredLevelOfOperatorPresence_AwarenessNotDetected" 0 "NoReason_AllClear" ;
VAL_ 2619604734 ExitReasonCodeAuxValve13 31 "NotAvailable" 30 "Error" 16 "ValveLockedOut_TransportLock" 15 "HydraulicOilLevelLow" 9 "FunctionFault" 8 "OperatorControlFault" 5 "RemoteCommandTimeout" 4 "OperatorControlNotInValidPosition" 3 "OperatorOverrideOfFunction" 2 "ImplementReleasedControlOfFunction" 7 "FunctionNotCalibrated" 6 "RemoteCommandOutOfRange_Invalid" 1 "RequiredLevelOfOperatorPresence_AwarenessNotDetected" 0 "NoReason_AllClear" ;
VAL_ 2619604734 ExitReasonCodeAuxValve12 31 "NotAvailable" 30 "Error" 16 "ValveLockedOut_TransportLock" 15 "HydraulicOilLevelLow" 9 "FunctionFault" 8 "OperatorControlFault" 5 "RemoteCommandTimeout" 4 "OperatorControlNotInValidPosition" 3 "OperatorOverrideOfFunction" 2 "ImplementReleasedControlOfFunction" 7 "FunctionNotCalibrated" 6 "RemoteCommandOutOfRange_Invalid" 1 "RequiredLevelOfOperatorPresence_AwarenessNotDetected" 0 "NoReason_AllClear" ;
VAL_ 2619604734 ExitReasonCodeAuxValve11 31 "NotAvailable" 30 "Error" 16 "ValveLockedOut_TransportLock" 15 "HydraulicOilLevelLow" 9 "FunctionFault" 8 "OperatorControlFault" 5 "RemoteCommandTimeout" 4 "OperatorControlNotInValidPosition" 3 "OperatorOverrideOfFunction" 2 "ImplementReleasedControlOfFunction" 7 "FunctionNotCalibrated" 6 "RemoteCommandOutOfRange_Invalid" 1 "RequiredLevelOfOperatorPresence_AwarenessNotDetected" 0 "NoReason_AllClear" ;
VAL_ 2619604734 ExitReasonCodeAuxValve10 31 "NotAvailable" 30 "Error" 16 "ValveLockedOut_TransportLock" 15 "HydraulicOilLevelLow" 9 "FunctionFault" 8 "OperatorControlFault" 5 "RemoteCommandTimeout" 4 "OperatorControlNotInValidPosition" 3 "OperatorOverrideOfFunction" 2 "ImplementReleasedControlOfFunction" 7 "FunctionNotCalibrated" 6 "RemoteCommandOutOfRange_Invalid" 1 "RequiredLevelOfOperatorPresence_AwarenessNotDetected" 0 "NoReason_AllClear" ;
VAL_ 2619604734 ExitReasonCodeAuxValve09 31 "NotAvailable" 30 "Error" 16 "ValveLockedOut_TransportLock" 15 "HydraulicOilLevelLow" 9 "FunctionFault" 8 "OperatorControlFault" 5 "RemoteCommandTimeout" 4 "OperatorControlNotInValidPosition" 3 "OperatorOverrideOfFunction" 2 "ImplementReleasedControlOfFunction" 7 "FunctionNotCalibrated" 6 "RemoteCommandOutOfRange_Invalid" 1 "RequiredLevelOfOperatorPresence_AwarenessNotDetected" 0 "NoReason_AllClear" ;
VAL_ 2619604734 ExitReasonCodeAuxValve08 31 "NotAvailable" 30 "Error" 16 "ValveLockedOut_TransportLock" 15 "HydraulicOilLevelLow" 9 "FunctionFault" 8 "OperatorControlFault" 5 "RemoteCommandTimeout" 4 "OperatorControlNotInValidPosition" 3 "OperatorOverrideOfFunction" 2 "ImplementReleasedControlOfFunction" 7 "FunctionNotCalibrated" 6 "RemoteCommandOutOfRange_Invalid" 1 "RequiredLevelOfOperatorPresence_AwarenessNotDetected" 0 "NoReason_AllClear" ;
VAL_ 2619604734 ExitReasonCodeAuxValve07 31 "NotAvailable" 30 "Error" 16 "ValveLockedOut_TransportLock" 15 "HydraulicOilLevelLow" 9 "FunctionFault" 8 "OperatorControlFault" 5 "RemoteCommandTimeout" 4 "OperatorControlNotInValidPosition" 3 "OperatorOverrideOfFunction" 2 "ImplementReleasedControlOfFunction" 7 "FunctionNotCalibrated" 6 "RemoteCommandOutOfRange_Invalid" 1 "RequiredLevelOfOperatorPresence_AwarenessNotDetected" 0 "NoReason_AllClear" ;
VAL_ 2619604734 ExitReasonCodeAuxValve06 31 "NotAvailable" 30 "Error" 16 "ValveLockedOut_TransportLock" 15 "HydraulicOilLevelLow" 9 "FunctionFault" 8 "OperatorControlFault" 5 "RemoteCommandTimeout" 4 "OperatorControlNotInValidPosition" 3 "OperatorOverrideOfFunction" 2 "ImplementReleasedControlOfFunction" 7 "FunctionNotCalibrated" 6 "RemoteCommandOutOfRange_Invalid" 1 "RequiredLevelOfOperatorPresence_AwarenessNotDetected" 0 "NoReason_AllClear" ;
VAL_ 2619604734 ExitReasonCodeAuxValve05 31 "NotAvailable" 30 "Error" 16 "ValveLockedOut_TransportLock" 15 "HydraulicOilLevelLow" 9 "FunctionFault" 8 "OperatorControlFault" 5 "RemoteCommandTimeout" 4 "OperatorControlNotInValidPosition" 3 "OperatorOverrideOfFunction" 2 "ImplementReleasedControlOfFunction" 7 "FunctionNotCalibrated" 6 "RemoteCommandOutOfRange_Invalid" 1 "RequiredLevelOfOperatorPresence_AwarenessNotDetected" 0 "NoReason_AllClear" ;
VAL_ 2619604734 ExitReasonCodeAuxValve04 31 "NotAvailable" 30 "Error" 16 "ValveLockedOut_TransportLock" 15 "HydraulicOilLevelLow" 9 "FunctionFault" 8 "OperatorControlFault" 5 "RemoteCommandTimeout" 4 "OperatorControlNotInValidPosition" 3 "OperatorOverrideOfFunction" 2 "ImplementReleasedControlOfFunction" 7 "FunctionNotCalibrated" 6 "RemoteCommandOutOfRange_Invalid" 1 "RequiredLevelOfOperatorPresence_AwarenessNotDetected" 0 "NoReason_AllClear" ;
VAL_ 2619604734 ExitReasonCodeAuxValve03 31 "NotAvailable" 30 "Error" 16 "ValveLockedOut_TransportLock" 15 "HydraulicOilLevelLow" 9 "FunctionFault" 8 "OperatorControlFault" 5 "RemoteCommandTimeout" 4 "OperatorControlNotInValidPosition" 3 "OperatorOverrideOfFunction" 2 "ImplementReleasedControlOfFunction" 7 "FunctionNotCalibrated" 6 "RemoteCommandOutOfRange_Invalid" 1 "RequiredLevelOfOperatorPresence_AwarenessNotDetected" 0 "NoReason_AllClear" ;
VAL_ 2619604734 ExitReasonCodeAuxValve02 31 "NotAvailable" 30 "Error" 16 "ValveLockedOut_TransportLock" 15 "HydraulicOilLevelLow" 9 "FunctionFault" 8 "OperatorControlFault" 5 "RemoteCommandTimeout" 4 "OperatorControlNotInValidPosition" 3 "OperatorOverrideOfFunction" 2 "ImplementReleasedControlOfFunction" 7 "FunctionNotCalibrated" 6 "RemoteCommandOutOfRange_Invalid" 1 "RequiredLevelOfOperatorPresence_AwarenessNotDetected" 0 "NoReason_AllClear" ;
VAL_ 2619604734 AutomationStatusAuxValve04 13 "AutomationFault" 7 "ActiveLimitedLow" 6 "ActiveLimitedHigh" 5 "ActiveNotLimited" 0 "AutomationUnavailable" 1 "AutomationNotReady" 2 "AutomationReadyToEnable" 3 "AutomationEnabled" 4 "AutomationPending" 14 "NonRecoverableFault" 15 "NotAvailable" ;
VAL_ 2619604734 AutomationStatusAuxValve03 13 "AutomationFault" 7 "ActiveLimitedLow" 6 "ActiveLimitedHigh" 5 "ActiveNotLimited" 0 "AutomationUnavailable" 1 "AutomationNotReady" 2 "AutomationReadyToEnable" 3 "AutomationEnabled" 4 "AutomationPending" 14 "NonRecoverableFault" 15 "NotAvailable" ;
VAL_ 2619604734 AutomationStatusAuxValve02 13 "AutomationFault" 7 "ActiveLimitedLow" 6 "ActiveLimitedHigh" 5 "ActiveNotLimited" 0 "AutomationUnavailable" 1 "AutomationNotReady" 2 "AutomationReadyToEnable" 3 "AutomationEnabled" 4 "AutomationPending" 14 "NonRecoverableFault" 15 "NotAvailable" ;
VAL_ 2619604734 AutomationStatusAuxValve01 13 "AutomationFault" 7 "ActiveLimitedLow" 6 "ActiveLimitedHigh" 5 "ActiveNotLimited" 0 "AutomationUnavailable" 1 "AutomationNotReady" 2 "AutomationReadyToEnable" 3 "AutomationEnabled" 4 "AutomationPending" 14 "NonRecoverableFault" 15 "NotAvailable" ;
VAL_ 2619604734 AutomationStatusExternalGuidance 13 "AutomationFault" 7 "ActiveLimitedLow" 6 "ActiveLimitedHigh" 5 "ActiveNotLimited" 0 "AutomationUnavailable" 1 "AutomationNotReady" 2 "AutomationReadyToEnable" 3 "AutomationEnabled" 4 "AutomationPending" 14 "NonRecoverableFault" 15 "NotAvailable" ;
VAL_ 2619604734 AutomationStatusVehicleSpeed 13 "AutomationFault" 7 "ActiveLimitedLow" 6 "ActiveLimitedHigh" 5 "ActiveNotLimited" 0 "AutomationUnavailable" 1 "AutomationNotReady" 2 "AutomationReadyToEnable" 3 "AutomationEnabled" 4 "AutomationPending" 14 "NonRecoverableFault" 15 "NotAvailable" ;
VAL_ 2619604734 AutomationStatusRearHitch 13 "AutomationFault" 7 "ActiveLimitedLow" 6 "ActiveLimitedHigh" 5 "ActiveNotLimited" 0 "AutomationUnavailable" 1 "AutomationNotReady" 2 "AutomationReadyToEnable" 3 "AutomationEnabled" 4 "AutomationPending" 14 "NonRecoverableFault" 15 "NotAvailable" ;
VAL_ 2619604734 AutomationStatusFrontHitch 13 "AutomationFault" 7 "ActiveLimitedLow" 6 "ActiveLimitedHigh" 5 "ActiveNotLimited" 0 "AutomationUnavailable" 1 "AutomationNotReady" 2 "AutomationReadyToEnable" 3 "AutomationEnabled" 4 "AutomationPending" 14 "NonRecoverableFault" 15 "NotAvailable" ;
VAL_ 2619604734 AutomationStatusRearPTO 13 "AutomationFault" 7 "ActiveLimitedLow" 6 "ActiveLimitedHigh" 5 "ActiveNotLimited" 0 "AutomationUnavailable" 1 "AutomationNotReady" 2 "AutomationReadyToEnable" 3 "AutomationEnabled" 4 "AutomationPending" 14 "NonRecoverableFault" 15 "NotAvailable" ;
VAL_ 2619604734 AutomationStatusFrontPTO 13 "AutomationFault" 7 "ActiveLimitedLow" 6 "ActiveLimitedHigh" 5 "ActiveNotLimited" 0 "AutomationUnavailable" 1 "AutomationNotReady" 2 "AutomationReadyToEnable" 3 "AutomationEnabled" 4 "AutomationPending" 14 "NonRecoverableFault" 15 "NotAvailable" ;
VAL_ 2619604734 AutomationStatusAuxValve32 13 "AutomationFault" 7 "ActiveLimitedLow" 6 "ActiveLimitedHigh" 5 "ActiveNotLimited" 0 "AutomationUnavailable" 1 "AutomationNotReady" 2 "AutomationReadyToEnable" 3 "AutomationEnabled" 4 "AutomationPending" 14 "NonRecoverableFault" 15 "NotAvailable" ;
VAL_ 2619604734 AutomationStatusAuxValve31 13 "AutomationFault" 7 "ActiveLimitedLow" 6 "ActiveLimitedHigh" 5 "ActiveNotLimited" 0 "AutomationUnavailable" 1 "AutomationNotReady" 2 "AutomationReadyToEnable" 3 "AutomationEnabled" 4 "AutomationPending" 14 "NonRecoverableFault" 15 "NotAvailable" ;
VAL_ 2619604734 AutomationStatusAuxValve30 13 "AutomationFault" 7 "ActiveLimitedLow" 6 "ActiveLimitedHigh" 5 "ActiveNotLimited" 0 "AutomationUnavailable" 1 "AutomationNotReady" 2 "AutomationReadyToEnable" 3 "AutomationEnabled" 4 "AutomationPending" 14 "NonRecoverableFault" 15 "NotAvailable" ;
VAL_ 2619604734 AutomationStatusAuxValve29 13 "AutomationFault" 7 "ActiveLimitedLow" 6 "ActiveLimitedHigh" 5 "ActiveNotLimited" 0 "AutomationUnavailable" 1 "AutomationNotReady" 2 "AutomationReadyToEnable" 3 "AutomationEnabled" 4 "AutomationPending" 14 "NonRecoverableFault" 15 "NotAvailable" ;
VAL_ 2619604734 AutomationStatusAuxValve28 13 "AutomationFault" 7 "ActiveLimitedLow" 6 "ActiveLimitedHigh" 5 "ActiveNotLimited" 0 "AutomationUnavailable" 1 "AutomationNotReady" 2 "AutomationReadyToEnable" 3 "AutomationEnabled" 4 "AutomationPending" 14 "NonRecoverableFault" 15 "NotAvailable" ;
VAL_ 2619604734 AutomationStatusAuxValve27 13 "AutomationFault" 7 "ActiveLimitedLow" 6 "ActiveLimitedHigh" 5 "ActiveNotLimited" 0 "AutomationUnavailable" 1 "AutomationNotReady" 2 "AutomationReadyToEnable" 3 "AutomationEnabled" 4 "AutomationPending" 14 "NonRecoverableFault" 15 "NotAvailable" ;
VAL_ 2619604734 AutomationStatusAuxValve26 13 "AutomationFault" 7 "ActiveLimitedLow" 6 "ActiveLimitedHigh" 5 "ActiveNotLimited" 0 "AutomationUnavailable" 1 "AutomationNotReady" 2 "AutomationReadyToEnable" 3 "AutomationEnabled" 4 "AutomationPending" 14 "NonRecoverableFault" 15 "NotAvailable" ;
VAL_ 2619604734 AutomationStatusAuxValve25 13 "AutomationFault" 7 "ActiveLimitedLow" 6 "ActiveLimitedHigh" 5 "ActiveNotLimited" 0 "AutomationUnavailable" 1 "AutomationNotReady" 2 "AutomationReadyToEnable" 3 "AutomationEnabled" 4 "AutomationPending" 14 "NonRecoverableFault" 15 "NotAvailable" ;
VAL_ 2619604734 AutomationStatusAuxValve24 13 "AutomationFault" 7 "ActiveLimitedLow" 6 "ActiveLimitedHigh" 5 "ActiveNotLimited" 0 "AutomationUnavailable" 1 "AutomationNotReady" 2 "AutomationReadyToEnable" 3 "AutomationEnabled" 4 "AutomationPending" 14 "NonRecoverableFault" 15 "NotAvailable" ;
VAL_ 2619604734 AutomationStatusAuxValve23 13 "AutomationFault" 7 "ActiveLimitedLow" 6 "ActiveLimitedHigh" 5 "ActiveNotLimited" 0 "AutomationUnavailable" 1 "AutomationNotReady" 2 "AutomationReadyToEnable" 3 "AutomationEnabled" 4 "AutomationPending" 14 "NonRecoverableFault" 15 "NotAvailable" ;
VAL_ 2619604734 AutomationStatusAuxValve22 13 "AutomationFault" 7 "ActiveLimitedLow" 6 "ActiveLimitedHigh" 5 "ActiveNotLimited" 0 "AutomationUnavailable" 1 "AutomationNotReady" 2 "AutomationReadyToEnable" 3 "AutomationEnabled" 4 "AutomationPending" 14 "NonRecoverableFault" 15 "NotAvailable" ;
VAL_ 2619604734 AutomationStatusAuxValve21 13 "AutomationFault" 7 "ActiveLimitedLow" 6 "ActiveLimitedHigh" 5 "ActiveNotLimited" 0 "AutomationUnavailable" 1 "AutomationNotReady" 2 "AutomationReadyToEnable" 3 "AutomationEnabled" 4 "AutomationPending" 14 "NonRecoverableFault" 15 "NotAvailable" ;
VAL_ 2619604734 AutomationStatusAuxValve20 13 "AutomationFault" 7 "ActiveLimitedLow" 6 "ActiveLimitedHigh" 5 "ActiveNotLimited" 0 "AutomationUnavailable" 1 "AutomationNotReady" 2 "AutomationReadyToEnable" 3 "AutomationEnabled" 4 "AutomationPending" 14 "NonRecoverableFault" 15 "NotAvailable" ;
VAL_ 2619604734 AutomationStatusAuxValve19 13 "AutomationFault" 7 "ActiveLimitedLow" 6 "ActiveLimitedHigh" 5 "ActiveNotLimited" 0 "AutomationUnavailable" 1 "AutomationNotReady" 2 "AutomationReadyToEnable" 3 "AutomationEnabled" 4 "AutomationPending" 14 "NonRecoverableFault" 15 "NotAvailable" ;
VAL_ 2619604734 AutomationStatusAuxValve18 13 "AutomationFault" 7 "ActiveLimitedLow" 6 "ActiveLimitedHigh" 5 "ActiveNotLimited" 0 "AutomationUnavailable" 1 "AutomationNotReady" 2 "AutomationReadyToEnable" 3 "AutomationEnabled" 4 "AutomationPending" 14 "NonRecoverableFault" 15 "NotAvailable" ;
VAL_ 2619604734 AutomationStatusAuxValve17 13 "AutomationFault" 7 "ActiveLimitedLow" 6 "ActiveLimitedHigh" 5 "ActiveNotLimited" 0 "AutomationUnavailable" 1 "AutomationNotReady" 2 "AutomationReadyToEnable" 3 "AutomationEnabled" 4 "AutomationPending" 14 "NonRecoverableFault" 15 "NotAvailable" ;
VAL_ 2619604734 AutomationStatusAuxValve16 13 "AutomationFault" 7 "ActiveLimitedLow" 6 "ActiveLimitedHigh" 5 "ActiveNotLimited" 0 "AutomationUnavailable" 1 "AutomationNotReady" 2 "AutomationReadyToEnable" 3 "AutomationEnabled" 4 "AutomationPending" 14 "NonRecoverableFault" 15 "NotAvailable" ;
VAL_ 2619604734 AutomationStatusAuxValve15 13 "AutomationFault" 7 "ActiveLimitedLow" 6 "ActiveLimitedHigh" 5 "ActiveNotLimited" 0 "AutomationUnavailable" 1 "AutomationNotReady" 2 "AutomationReadyToEnable" 3 "AutomationEnabled" 4 "AutomationPending" 14 "NonRecoverableFault" 15 "NotAvailable" ;
VAL_ 2619604734 AutomationStatusAuxValve14 13 "AutomationFault" 7 "ActiveLimitedLow" 6 "ActiveLimitedHigh" 5 "ActiveNotLimited" 0 "AutomationUnavailable" 1 "AutomationNotReady" 2 "AutomationReadyToEnable" 3 "AutomationEnabled" 4 "AutomationPending" 14 "NonRecoverableFault" 15 "NotAvailable" ;
VAL_ 2619604734 AutomationStatusAuxValve13 13 "AutomationFault" 7 "ActiveLimitedLow" 6 "ActiveLimitedHigh" 5 "ActiveNotLimited" 0 "AutomationUnavailable" 1 "AutomationNotReady" 2 "AutomationReadyToEnable" 3 "AutomationEnabled" 4 "AutomationPending" 14 "NonRecoverableFault" 15 "NotAvailable" ;
VAL_ 2619604734 AutomationStatusAuxValve12 13 "AutomationFault" 7 "ActiveLimitedLow" 6 "ActiveLimitedHigh" 5 "ActiveNotLimited" 0 "AutomationUnavailable" 1 "AutomationNotReady" 2 "AutomationReadyToEnable" 3 "AutomationEnabled" 4 "AutomationPending" 14 "NonRecoverableFault" 15 "NotAvailable" ;
VAL_ 2619604734 AutomationStatusAuxValve11 13 "AutomationFault" 7 "ActiveLimitedLow" 6 "ActiveLimitedHigh" 5 "ActiveNotLimited" 0 "AutomationUnavailable" 1 "AutomationNotReady" 2 "AutomationReadyToEnable" 3 "AutomationEnabled" 4 "AutomationPending" 14 "NonRecoverableFault" 15 "NotAvailable" ;
VAL_ 2619604734 AutomationStatusAuxValve10 13 "AutomationFault" 7 "ActiveLimitedLow" 6 "ActiveLimitedHigh" 5 "ActiveNotLimited" 0 "AutomationUnavailable" 1 "AutomationNotReady" 2 "AutomationReadyToEnable" 3 "AutomationEnabled" 4 "AutomationPending" 14 "NonRecoverableFault" 15 "NotAvailable" ;
VAL_ 2619604734 AutomationStatusAuxValve09 13 "AutomationFault" 7 "ActiveLimitedLow" 6 "ActiveLimitedHigh" 5 "ActiveNotLimited" 0 "AutomationUnavailable" 1 "AutomationNotReady" 2 "AutomationReadyToEnable" 3 "AutomationEnabled" 4 "AutomationPending" 14 "NonRecoverableFault" 15 "NotAvailable" ;
VAL_ 2619604734 AutomationStatusAuxValve08 13 "AutomationFault" 7 "ActiveLimitedLow" 6 "ActiveLimitedHigh" 5 "ActiveNotLimited" 0 "AutomationUnavailable" 1 "AutomationNotReady" 2 "AutomationReadyToEnable" 3 "AutomationEnabled" 4 "AutomationPending" 14 "NonRecoverableFault" 15 "NotAvailable" ;
VAL_ 2619604734 AutomationStatusAuxValve07 13 "AutomationFault" 7 "ActiveLimitedLow" 6 "ActiveLimitedHigh" 5 "ActiveNotLimited" 0 "AutomationUnavailable" 1 "AutomationNotReady" 2 "AutomationReadyToEnable" 3 "AutomationEnabled" 4 "AutomationPending" 14 "NonRecoverableFault" 15 "NotAvailable" ;
VAL_ 2619604734 AutomationStatusAuxValve06 13 "AutomationFault" 7 "ActiveLimitedLow" 6 "ActiveLimitedHigh" 5 "ActiveNotLimited" 0 "AutomationUnavailable" 1 "AutomationNotReady" 2 "AutomationReadyToEnable" 3 "AutomationEnabled" 4 "AutomationPending" 14 "NonRecoverableFault" 15 "NotAvailable" ;
VAL_ 2619604734 AutomationStatusAuxValve05 13 "AutomationFault" 7 "ActiveLimitedLow" 6 "ActiveLimitedHigh" 5 "ActiveNotLimited" 0 "AutomationUnavailable" 1 "AutomationNotReady" 2 "AutomationReadyToEnable" 3 "AutomationEnabled" 4 "AutomationPending" 14 "NonRecoverableFault" 15 "NotAvailable" ;
VAL_ 2619604734 Curvature 65535 "NotAvailable" 65534 "Error" 32128 "Straight" ;
VAL_ 2619604734 ExitReasonCodeExternalGuidance 21 "HydraulicOilLevelTooLow" 20 "HydraulicOilTemperatureTooLow" 19 "VehicleTransmissionGearDoesntAllowRemoteCommands" 18 "VehicleSpeedTooLow" 17 "VehicleSpeedTooHigh" 16 "AlternateGuidanceSystemActive" 31 "NotAvailable" 30 "Error" 15 "ControlUnitInDiagnosticMode" 9 "FunctionFault" 8 "OperatorControlFault" 5 "RemoteCommandTimeout" 4 "OperatorControlNotInValidPosition" 3 "OperatorOverrideOfFunction" 2 "ImplementReleasedControlOfFunction" 7 "FunctionNotCalibrated" 6 "RemoteCommandOutOfRangeOrInvalid" 1 "RequiredLevelOfOperatorPresence_AwarenessNotDetected" 0 "NoReason_AllClear" ;
VAL_ 2619604734 VehicleSpeed 65535 "NotAvailable" 65534 "Error" ;
VAL_ 2619604734 ExitReasonCodeVehicleSpeed 31 "NotAvailable" 30 "Error" 15 "VehicleTransmissionGearDoesntAllowRemoteCommands " 9 "FunctionFault" 8 "OperatorControlFault" 5 "RemoteCommandTimeout" 4 "OperatorControlNotInValidPosition" 3 "OperatorOverrideOfFunction" 2 "ImplementReleasedControlOfFunction" 7 "FunctionNotCalibrated" 6 "RemoteCommandOutOfRangeOrInvalid" 1 "RequiredLevelOfOperatorPresence_AwarenessNotDetected" 0 "NoReason_AllClear" ;
VAL_ 2619604734 FrontHitchPosition 65535 "NotAvailable" 65534 "Error" 64259 "Raising" 64258 "Lowering" 64257 "Stop" 10000 "FullRaise" 0 "FullLower" 64256 "Float" ;
VAL_ 2619604734 ExitReasonCodeFrontHitch 16 "HitchLockedOut" 31 "NotAvailable" 30 "Error" 15 "HydraulicOilLevelLow" 9 "FunctionFault" 8 "OperatorControlFault" 5 "RemoteCommandTimeout" 4 "OperatorControlNotInValidPosition" 3 "OperatorOverrideOfFunction" 2 "ImplementReleasedControlOfFunction" 7 "FunctionNotCalibrated" 6 "RemoteCommandOutOfRangeOrInvalid" 1 "RequiredLevelOfOperatorPresence_AwarenessNotDetected" 0 "NoReason_AllClear" ;
VAL_ 2619604734 FrontPTOSpeed 65535 "NotAvailable" 65534 "Error" ;
VAL_ 2619604734 ExitReasonCodeFrontPTO 31 "NotAvailable" 30 "Error" 15 "InvalidPtoGear" 9 "FunctionFault" 8 "OperatorControlFault" 5 "RemoteCommandTimeout" 4 "OperatorControlNotInValidPosition" 3 "OperatorOverrideOfFunction" 2 "ImplementReleasedControlOfFunction" 7 "FunctionNotCalibrated" 6 "RemoteCommandOutOfRange_Invalid" 1 "RequiredLevelOfOperatorPresence_AwarenessNotDetected" 0 "NoReason_AllClear" ;
VAL_ 2619604734 FlowAuxValve01 64257 "Float" 64256 "ValveFullyOpened_Retract" 32128 "NoFlow_Block" 0 "ValveFullyOpened_Extend" ;
VAL_ 2619604734 ReflectedRequestCounter 15 "NotAvailable_DontCare " 14 "Reserved" ;
VAL_ 2619604734 ExitReasonCodeAuxValve01 31 "NotAvailable" 30 "Error" 16 "ValveLockedOut_TransportLock" 15 "HydraulicOilLevelLow" 9 "FunctionFault" 8 "OperatorControlFault" 5 "RemoteCommandTimeout" 4 "OperatorControlNotInValidPosition" 3 "OperatorOverrideOfFunction" 2 "ImplementReleasedControlOfFunction" 7 "FunctionNotCalibrated" 6 "RemoteCommandOutOfRange_Invalid" 1 "RequiredLevelOfOperatorPresence_AwarenessNotDetected" 0 "NoReason_AllClear" ;
VAL_ 2619604734 TIMSystemOperationState 15 "NotAvailable" 14 "Error" 3 "RequirementsStationaryFulfilled" 2 "RequirementsStandstillFulfilled" 1 "RequirementsNormalFulfilled" 0 "RequirementsNotFulfilled" ;
VAL_ 2619604734 TIMServerState 13 "AutomationFault" 5 "AutomationActive" 3 "AutomationEnabled" 15 "NotAvailable" 14 "Error" 1 "AutomationNotReady" 0 "AutomationUnavailable" ;
VAL_ 2619604734 TIMSystemState 15 "NotAvailable" 14 "Error" 5 "AutomationActive" 1 "NoAutomationActive" ;
VAL_ 2619604734 LeadTIMServerIndication 15 "NotAvailable" 14 "Error" 1 "IsLeadAndAutomationAllowed" 0 "IsLeadButAutomationNotAllowed" ;
VAL_ 2619604734 ServerHeartbeatCounter 255 "GracefulShutdown" 254 "ErrorConditionOnSender" 251 "ResetOfHeartbeatCounter" ;
VAL_ 2619604734 AssignmentResult_4 7 "NotAvailable" 6 "Error" 5 "AssignmentNotSuccessful" 1 "IsAssigned" 0 "IsNotAssigned" ;
VAL_ 2619604734 AssignmentResult_3 7 "NotAvailable" 6 "Error" 5 "AssignmentNotSuccessful" 1 "IsAssigned" 0 "IsNotAssigned" ;
VAL_ 2619604734 AssignmentResult_2 7 "NotAvailable" 6 "Error" 5 "AssignmentNotSuccessful" 1 "IsAssigned" 0 "IsNotAssigned" ;
VAL_ 2619604734 AssignmentErrorReason_4 31 "NotAvailable" 30 "AnyOtherError" 8 "ClientNotAuthenticated" 7 "NoMatchingFacility" 6 "ServerBusyWithAssignmentRequest" 5 "ClientNotCertifiedForFunction" 4 "ErrorInRequestMessage" 3 "UnknownRequestType" 2 "FunctionCurrentlyNotAvailable" 1 "FunctionNotSupportedByServer" 0 "AllClearNoReason" ;
VAL_ 2619604734 AssignmentErrorReason_3 31 "NotAvailable" 30 "AnyOtherError" 8 "ClientNotAuthenticated" 7 "NoMatchingFacility" 6 "ServerBusyWithAssignmentRequest" 5 "ClientNotCertifiedForFunction" 4 "ErrorInRequestMessage" 3 "UnknownRequestType" 2 "FunctionCurrentlyNotAvailable" 1 "FunctionNotSupportedByServer" 0 "AllClearNoReason" ;
VAL_ 2619604734 AssignmentErrorReason_2 31 "NotAvailable" 30 "AnyOtherError" 8 "ClientNotAuthenticated" 7 "NoMatchingFacility" 6 "ServerBusyWithAssignmentRequest" 5 "ClientNotCertifiedForFunction" 4 "ErrorInRequestMessage" 3 "UnknownRequestType" 2 "FunctionCurrentlyNotAvailable" 1 "FunctionNotSupportedByServer" 0 "AllClearNoReason" ;
VAL_ 2619604734 AssignmentErrorReason_1 31 "NotAvailable" 30 "AnyOtherError" 8 "ClientNotAuthenticated" 7 "NoMatchingFacility" 6 "ServerBusyWithAssignmentRequest" 5 "ClientNotCertifiedForFunction" 4 "ErrorInRequestMessage" 3 "UnknownRequestType" 2 "FunctionCurrentlyNotAvailable" 1 "FunctionNotSupportedByServer" 0 "AllClearNoReason" ;
VAL_ 2619604734 AssignmentResult_1 7 "NotAvailable" 6 "Error" 5 "AssignmentNotSuccessful" 1 "IsAssigned" 0 "IsNotAssigned" ;
VAL_ 2619604734 TIMFunctionId_4 72 "RearTopLinkage" 71 "FrontTopLinkage" 32 "AuxValve32" 70 "ExternalGuidance" 68 "VehicleSpeed" 67 "RearHitch" 66 "FrontHitch" 65 "RearPTO" 64 "FrontPTO" 31 "AuxValve31" 30 "AuxValve30" 29 "AuxValve29" 28 "AuxValve28" 27 "AuxValve27" 26 "AuxValve26" 25 "AuxValve25" 24 "AuxValve24" 23 "AuxValve23" 22 "AuxValve22" 21 "AuxValve21" 20 "AuxValve20" 19 "AuxValve19" 18 "AuxValve18" 17 "AuxValve17" 16 "AuxValve16" 15 "AuxValve15" 14 "AuxValve14" 13 "AuxValve13" 12 "AuxValve12" 11 "AuxValve11" 10 "AuxValve10" 9 "AuxValve9" 8 "AuxValve8" 7 "AuxValve7" 6 "AuxValve6" 5 "AuxValve5" 4 "AuxValve4" 3 "AuxValve3" 2 "AuxValve2" 1 "AuxValve1" ;
VAL_ 2619604734 TIMFunctionId_3 72 "RearTopLinkage" 71 "FrontTopLinkage" 32 "AuxValve32" 70 "ExternalGuidance" 68 "VehicleSpeed" 67 "RearHitch" 66 "FrontHitch" 65 "RearPTO" 64 "FrontPTO" 31 "AuxValve31" 30 "AuxValve30" 29 "AuxValve29" 28 "AuxValve28" 27 "AuxValve27" 26 "AuxValve26" 25 "AuxValve25" 24 "AuxValve24" 23 "AuxValve23" 22 "AuxValve22" 21 "AuxValve21" 20 "AuxValve20" 19 "AuxValve19" 18 "AuxValve18" 17 "AuxValve17" 16 "AuxValve16" 15 "AuxValve15" 14 "AuxValve14" 13 "AuxValve13" 12 "AuxValve12" 11 "AuxValve11" 10 "AuxValve10" 9 "AuxValve9" 8 "AuxValve8" 7 "AuxValve7" 6 "AuxValve6" 5 "AuxValve5" 4 "AuxValve4" 3 "AuxValve3" 2 "AuxValve2" 1 "AuxValve1" ;
VAL_ 2619604734 TIMFunctionId_2 72 "RearTopLinkage" 71 "FrontTopLinkage" 32 "AuxValve32" 70 "ExternalGuidance" 68 "VehicleSpeed" 67 "RearHitch" 66 "FrontHitch" 65 "RearPTO" 64 "FrontPTO" 31 "AuxValve31" 30 "AuxValve30" 29 "AuxValve29" 28 "AuxValve28" 27 "AuxValve27" 26 "AuxValve26" 25 "AuxValve25" 24 "AuxValve24" 23 "AuxValve23" 22 "AuxValve22" 21 "AuxValve21" 20 "AuxValve20" 19 "AuxValve19" 18 "AuxValve18" 17 "AuxValve17" 16 "AuxValve16" 15 "AuxValve15" 14 "AuxValve14" 13 "AuxValve13" 12 "AuxValve12" 11 "AuxValve11" 10 "AuxValve10" 9 "AuxValve9" 8 "AuxValve8" 7 "AuxValve7" 6 "AuxValve6" 5 "AuxValve5" 4 "AuxValve4" 3 "AuxValve3" 2 "AuxValve2" 1 "AuxValve1" ;
VAL_ 2619604734 TIMFunctionId_1 72 "RearTopLinkage" 71 "FrontTopLinkage" 32 "AuxValve32" 70 "ExternalGuidance" 68 "VehicleSpeed" 67 "RearHitch" 66 "FrontHitch" 65 "RearPTO" 64 "FrontPTO" 31 "AuxValve31" 30 "AuxValve30" 29 "AuxValve29" 28 "AuxValve28" 27 "AuxValve27" 26 "AuxValve26" 25 "AuxValve25" 24 "AuxValve24" 23 "AuxValve23" 22 "AuxValve22" 21 "AuxValve21" 20 "AuxValve20" 19 "AuxValve19" 18 "AuxValve18" 17 "AuxValve17" 16 "AuxValve16" 15 "AuxValve15" 14 "AuxValve14" 13 "AuxValve13" 12 "AuxValve12" 11 "AuxValve11" 10 "AuxValve10" 9 "AuxValve9" 8 "AuxValve8" 7 "AuxValve7" 6 "AuxValve6" 5 "AuxValve5" 4 "AuxValve4" 3 "AuxValve3" 2 "AuxValve2" 1 "AuxValve1" ;
VAL_ 2619604734 TIMConnectionVersion 255 "IncompatibleTIMServerAndClientVersions" ;
VAL_ 2619604734 ErrorCode 1 "IncompatibleTIMServerAndClientVersions" 0 "NoError" ;
VAL_ 2619604734 TIMMessageType 1 "TIMFunctionStatus" 0 "TIMFunctionRequest" ;
VAL_ 2563309310 PGNumber 255 "NotAvailable" ;
VAL_ 2563309310 ControlByte 255 "EAbort" 20 "ERTS" 21 "ECTS" 22 "EDPO" 23 "EEoMACK" ;
VAL_ 2563309310 ConnectionAbortReason 15 "ECTS requested packets exceeds message size" 14 "Unexpected ECTS PGN (PGN in ECTS is bad)" 13 "Deprecated use 254 instead" 12 "Bad EDPO offset" 11 "EDPO number of packets is greater than CTS" 10 "Unexpected EDPO PGN (PGN in EDPO is bad)" 9 "Unexpected EDPO packet" 8 "Duplicate sequence number" 1 "Already in one or more connection-managed sessions" 2 "System resources were needed for another task" 3 "Timeout occurred" 4 "CTS messages received when data transfer is in progress" 5 "Maximum retransmit request limit reached" 6 "Unexpected data transfer packet" 7 "Bad sequence number" ;
VAL_ 2365475326 GroundBasedMachineDirection 3 "NotAvailable" 2 "ErrorIndication" 1 "Forward" 0 "Reverse" ;
VAL_ 2365475070 OperatorDirectionReversed 0 "Not reversed" 1 "Reversed" 2 "Error" 3 "Not available" ;
VAL_ 2365475070 StartStopState 3 "Don't Care" 2 "Reserved" 1 "Start or enable implement work" 0 "Stop or disable implement work" ;
VAL_ 2365475070 KeySwitchState 3 "NotAvailable" 2 "ErrorIndication" 1 "KeySwitchNotOff" 0 "KeySwitchOff" ;
VAL_ 2365475070 WheelBasedMachineDirection 3 "NotAvailable" 2 "ErrorIndicator" 1 "Forward" 0 "Reverse" ;
VAL_ 2566787070 CountryCode 65535 "NotDefined" ;
VAL_ 2566787070 TemperatureUnits 3 "NoAction" 2 "Reserved" 1 "Imperial" 0 "Metric" ;
VAL_ 2566787070 PressureUnits 3 "NoAction" 2 "Reserved" 1 "Imperial" 0 "Metric" ;
VAL_ 2566787070 ForceUnits 3 "NoAction" 2 "Reserved" 1 "Imperial" 0 "Metric" ;
VAL_ 2566787070 UnitsSystem 3 "NoAction" 2 "US" 1 "Imperial" 0 "Metric" ;
VAL_ 2566787070 DistanceUnitCmd 3 "NoAction" 1 "Imperial" 0 "Metric" ;
VAL_ 2566787070 AreaUnitCmd 3 "NoAction" 1 "Imperial" 0 "Metric" ;
VAL_ 2566787070 VolumeUnitCmd 3 "NoAction" 2 "US" 1 "Imperial" 0 "Metric" ;
VAL_ 2566787070 MassUnitCmd 3 "NoAction" 2 "TonsPounds" 1 "Imperial" 0 "Metric" ;
VAL_ 2566787070 DateFormatCmd 5 "yyyyddmm" 4 "yyyymmdd" 3 "mmddyyyy" 2 "mmyyyydd" 1 "ddyyyymm" 0 "ddmmyyyy" ;
VAL_ 2566787070 DecimalSymbolCmd 3 "NoAction" 1 "PointIsUsed" 0 "CommaIsUsed" ;
VAL_ 2566787070 TimeFormatCmd 3 "NoAction" 1 "Hour12" 0 "Hour24" ;
VAL_ 2632777470 PGNumber 255 "NotAvailable" ;
VAL_ 2632777470 ConnectionAbortReason 8 "Duplicate sequence number" 1 "Already in one or more connection-managed sessions" 2 "System resources were needed for another task" 3 "Timeout occurred" 4 "CTS messages received when data transfer is in progress" 5 "Maximum retransmit request limit reached" 6 "Unexpected data transfer packet" 7 "Bad sequence number" ;
VAL_ 2632777470 ControlByte 16 "RTS" 17 "CTS" 19 "EoMA" 255 "Abort" 32 "BAM" ;
VAL_ 2565406462 ControlByte 0 "ACK" 1 "NACK" 2 "AccessDenied" 3 "CannotRespond" ;
VAL_ 2565799678 IndustryGroup 7 "Reserved for SAE" 5 "IndustrialProcessCtrlStationary" 4 "Marine" 3 "Construction" 2 "AgriculturalAndForestry" 1 "On-Highway" 0 "Global" ;
VAL_ 2565799678 VehicleSystem 127 "Not Available" 0 "NonSpecificSystem" ;
VAL_ 2565799678 VehicleSystem5 0 "Ind. Process Control Stationary" 127 "Not Available" ;
VAL_ 2565799678 VehicleSystem4 0 "NonSpecificSystem" 127 "Not Available" 10 "System Tools" 20 "Safety Systems" 25 "Inter/Intranetwork Device" 30 "Electrical Distribution" 40 "Steering and Control Surfaces" 50 "Propulsion" 60 "Navigation" 70 "Communications" 80 "Instrumentation/General Systems (deprecate)" 90 "Internal Environment" 100 "Deck, Cargo and Fishing Equipment" 35 "Electrical Generation" 75 "Sensor Communication Interface" 85 "External Environment" 120 "Display" 125 "Entertainment" ;
VAL_ 2565799678 VehicleSystem3 0 "NonSpecificSystem" 127 "Not Available" 1 "Skid Steer Loader" 2 "Articulated Dump Truck" 3 "Backhoe" 4 "Crawler" 5 "Excavator" 6 "Forklift" 7 "Four Wheel Drive Loader" 8 "Grader" ;
VAL_ 2565799678 VehicleSystem2 0 "NonSpecificSystem" 127 "Not Available" 1 "Tractor" 2 "Tillage" 3 "Secondary Tillage" 4 "Planters/Seeders" 5 "Fertilizers" 6 "Sprayers" 7 "Harvesters" 8 "Root Harvesters" 9 "Forage" 10 "Irrigation" 11 "Transport/Trailer" 12 "Farm Yard Operations" 13 "Powered Auxiliary Device" 14 "Special Crops" 15 "Earth Work" 16 "Skidder" 17 "Sensor Systems" 19 "Timber Harvesters" 20 "Forwarders" 21 "Timber loaders" 22 "Timber Processing Machines" 23 "Mulchers" 24 "Utility Vehicles" 25 "Slurry Applicators" ;
VAL_ 2565799678 VehicleSystem1 0 "NonSpecificSystem" 127 "Not Available" 1 "Tractor" 2 "Trailer" ;
VAL_ 2565799678 Function 142 "TIMServer" 43 "Transmission Display" 44 "Exhaust Emission Control" 45 "Vehicle Dynamic Stability Control" 46 "Oil Sensor Unit" 47 "Information System Controller" 48 "Ramp Control" 49 "Clutch/Converter Control" 50 "Auxiliary Heater" 51 "Forward-Looking Collision Warning System" 52 "Chassis Controller" 53 "Alternator/Charging System" 54 "Communications Unit, Cellular" 55 "Communications Unit, Satellite" 56 "Communications Unit, Radio" 57 "Steering Column Unit" 58 "Fan Drive Control" 59 "Starter" 60 "Cab Display" 61 "File Server/Printer" 62 "On-Board Diagnostic Unit" 63 "Engine Valve Controller" 64 "Endurance Braking" 65 "Gas Flow Measurement" 66 "I/O Controller" 67 "Electrical System Controller" 68 "Aftertreatment system gas measurement" 69 "Engine Emission Aftertreatement System" 70 "Auxiliary Regeneration Device" 71 "Transfer Case Control" 72 "Coolant Valve Controller" 73 "Rollover Detection Control" 74 "Lubrication System" 75 "Supplemental Fan" 76 "Temperature Sensor" 77 "Fuel Properties Sensor" 78 "Fire Suppression System" 79 "Power Systems Manager" 80 "Electric Powertrain" 81 "Hydraulic Powertrain" 82 "File Server" 83 "Printer" 84 "Start Aid Device" 85 "Engine Injection Control Module" 86 "Reserved" 87 "Reserved" 88 "Reserved" 89 "Reserved" 90 "Reserved" 91 "Reserved" 92 "Reserved" 93 "Reserved" 94 "Reserved" 95 "Reserved" 96 "Reserved" 97 "Reserved" 98 "Reserved" 99 "Reserved" 100 "Reserved" 0 "Engine" 1 "Auxiliary Power Unit (APU)" 2 "Electric Propulsion Control" 3 "Transmission" 4 "Battery Pack Monitor" 5 "Shift Control/Console" 6 "Power TakeOff - (Main or Rear)" 7 "Axle - Steering" 8 "Axle - Drive" 9 "Brakes - System Controller" 10 "Brakes - Steer Axle" 11 "Brakes - Drive Axle" 12 "Retarder - Engine" 13 "Retarder - Driveline" 14 "Cruise Control" 15 "Fuel System" 16 "Steering Controller" 17 "Suspension - Steer Axle" 18 "Suspension - Drive Axle" 19 "Instrument Cluster" 20 "Trip Recorder" 21 "Cab Climate Control" 22 "Aerodynamic Control" 23 "Vehicle Navigation" 24 "Vehicle Security" 25 "Network Interconnect ECU" 26 "Body Controller" 27 "Power TakeOff (Secondary or Front)" 28 "Off Vehicle Gateway" 29 "Virtual Terminal (in cab)" 30 "Management Computer" 31 "Propulsion Battery Charger" 32 "Headway Controller" 33 "System Monitor" 34 "Hydraulic Pump Controller" 35 "Suspension - System Controller" 36 "Pneumatic - System Controller" 37 "Cab Controller" 38 "Tire Pressure Control" 39 "Ignition Control Module" 40 "Seat Control" 41 "Lighting - Operator Controls" 42 "Water Pump Control" 101 "Reserved" 102 "Reserved" 103 "Reserved" 104 "Reserved" 105 "Reserved" 106 "Reserved" 107 "Reserved" 108 "Reserved" 109 "Reserved" 110 "Reserved" 111 "Reserved" 112 "Reserved" 113 "Reserved" 114 "Reserved" 115 "Reserved" 116 "Reserved" 117 "Reserved" 118 "Reserved" 119 "Reserved" 120 "Reserved" 121 "Reserved" 122 "Reserved" 123 "Reserved" 124 "Reserved" 125 "Reserved" 126 "Reserved" 127 "Reserved" 255 "Not Available" ;
VAL_ 2565799678 ManufacturerCode 1077 "Ymer Technology" 1076 "DOGA S.A." 1075 "Uniden America Corporation" 1074 "Kindhelm / Navigs Oy" 1073 "Manitou Equipment America LLC" 1072 "La Marche Manufacturing Company" 1071 "MACH SYSTEMS s.r.o." 1070 "Quick-teck Electronics Ltd" 1069 "Lithionics Battery LLC" 1068 "Zapi S.p.A." 1067 "Tecomec S.r.l." 1066 "Spot Zero Water" 1065 "CALYPSO Instruments" 1064 "Omnitech Robotics Inc." 1063 "SolSteer" 1062 "Marol Co Ltd" 1061 "Volvo Construction Equipment" 1060 "Scale-Tec" 1059 "Boatrax" 1058 "Bondioli & Pavesi SpA" 1057 "EquipmentShare" 1056 "Lithium Pros" 1055 "EXA Computing GmbH" 1054 "Schmotzer Hacktechnik GmbH & Co. KG" 1053 "Vetus Maxwell, Inc." 1052 "Pfreundt" 1051 "ProNav AS" 1050 "Spacenus GmbH" 1049 "S&S Cycle" 1048 "Agrivation UG" 1047 "Sonic Corporation" 1046 "Praxidyn" 1045 "CMR Group" 1044 "Xee" 1043 "Hyva" 1042 "engcon group" 1041 "EZ Lynk" 1040 "BPE Electronics Srl" 1039 "Liugong Dressta Machinery" 1038 "EMIT Technologies, Inc." 1037 "Dragonfly Energy Corp." 1036 "Bender GmbH & Co. KG" 1035 "Agres" 1034 "Siren Marine" 1033 "ECCO Safety Group" 1032 "SIMOL S.p.A." 1031 "Flintec UK Ltd." 1030 "Tume-Agri Oy" 1029 "The Marine Guardian LLC" 1028 "Autel Intelligent Technology Corp., Ltd" 1027 "Goldacres PTY LTD" 1026 "ZTR Control Systems, LLC" 1025 "eze System, Inc." 1024 "Inventus Power" 1023 "PEAK-System Technik GmbH" 1022 "ITC Inc" 1021 "Entratech Systems LLC" 1020 "Onyx Marine Automation s.r.l." 1019 "Codek Foundries" 1018 "Flex TTS" 1017 "Caldaro AB" 1016 "Röhren- und Pumpenwerk BAUER GmbH" 1015 "SECURITAG SAS" 1014 "Briri Maschinenbau GmbH" 1013 "Allochis E-Tec" 1012 "Rhodan Marine Systems of Florida LLC" 1011 "Soundmax Electronics Ltd" 1010 "Agricultural Industry Electronics Foundation e.V." 1009 "TouchTronics, Inc." 1008 "Lintest Systems LLC" 1007 "Maschinenfabrik Meyer-Lohne GmbH" 1006 "Proterra" 1005 "TSE Brakes, Inc." 1004 "Ultraflex SpA" 1003 "technotrans SE" 1002 "Kussmaul Electronics Co." 1001 "Cleral Inc." 1000 "Landmaschinen Wienhoff GmbH" 1569 "621 Technologies Inc." 999 "TerraTroniq B.V." 998 "Transcell Technology Inc" 997 "Xenta Systems Srl" 996 "Eniquest Pty Ltd" 995 "Circuitlink Pty Ltd." 994 "Morris Industries Ltd." 993 "Alelion Energy Systems AB" 992 "MarineIOT LLC" 991 "Deutronic Elektronik GmbH" 990 "SAMSUNG SDI Co., Ltd." 989 "Flux-Geräte GmbH" 988 "Voith Turbo" 987 "Baltic Car Equipment" 986 "AAMP Global" 985 "NLR, LLC" 984 "E-T-A Elektrotechnische Apparate GmbH" 983 "Dezwaef NV" 982 "Briggs & Stratton Corporation" 981 "Kobelt Manufacturing Co. Ltd" 980 "Gussi Italia S.R.L." 979 "McHale" 978 "Canfield Connector" 977 "Emerson Electric Co." 976 "Derive Systems, Inc." 975 "Siemens AG" 974 "Pico Technology Limited" 973 "Zasso GmbH" 972 "Axion AG" 971 "B+B Smartworx" 970 "Jaboni Power Products, LLC" 969 "Blue Sea Systems" 968 "Cox Powertrain Limited" 967 "Moteck Electric Corp." 966 "VisibleFarm" 965 "Ro-Sys Software" 964 "AgroVIR Kft" 963 "Thomason Jones Company, LLC" 962 "Timbolier Industries, Inc." 961 "POK SAS" 960 "Vemcon GmbH" 959 "Cascade Corporation" 958 "NHK MEC Corporation" 957 "Sierra Wireless Inc" 956 "Piher Sensors & Controls S.A." 955 "Hottinger Baldwin (Suzhou) Electronic Measurement Technology Co., Ltd." 954 "Setec Pty Ltd" 953 "Curtiss-Wright" 952 "Tan Delta Systems Ltd" 951 "Exor International S.p.A." 950 "RE:Lab s.r.l." 949 "Škoda Electric a.s." 948 "Donix" 947 "Gerd Bär GmbH" 946 "Hydac Tecnologia Ltda" 945 "Equalizer AG" 944 "ZONTISA Marine SL" 943 "FISCHER AG Präzisionspindeln" 942 "Vogelsang GmbH & Co. KG" 941 "Navya" 940 "Dometal Oy" 939 "Warn Industries, Inc." 938 "LEVEL Systems" 937 "Precision Circuits Inc" 936 "Hi-tech Millennium" 935 "Meels GmbH & Co. KG" 934 "Farmobile, Inc." 933 "Delta Mobile Systems, Inc." 932 "Discover Battery" 931 "Enertec Marine Ltd" 930 "Ecotronix Corp." 929 "Jl Marine Systems, Inc." 928 "EAO Automotive GmbH & Co. KG" 927 "Saicon" 926 "Buhler Industries Inc." 925 "GW Lisk Company" 924 "PAS Peschak Autonome Systeme GmbH" 923 "ELTEK S.p.A." 922 "Terberg Benschop B.V." 921 "ROPA Fahrzeug- und Maschinenbau GmbH" 920 "MTD Consumer Group Inc." 919 "Furrion LLC" 918 "AMW Machine Control, Inc" 917 "Sentinel d.o.o." 916 "Turck Inc." 915 "Dosificacion y sistemas electronicos S.L. (DSE)" 914 "ZETOR TRACTORS a.s." 913 "Toyota Motor Corporation" 912 "Steyr Motors GmbH" 911 "Nautic-On" 910 "Hermann Paus Maschinenfabrik GmbH" 909 "Marines Co., Ltd." 908 "Chonbuk National University Department of Electronics" 907 "strautmann" 906 "MOBA AG" 905 "ASA Electronics" 904 "Equipment Safety Systems Pty. Ltd. (EQSS)" 903 "InMotion" 902 "Bucher Hydraulics" 901 "Zivan Srl" 900 "OSB AG" 899 "Lippert Components, Inc" 898 "Josef Kotte Landtechnik GmbH & Co. KG" 897 "Dot Technology Corp." 896 "NextFour Solutions Ltd" 895 "Peloton Technology" 894 "Rhodan Marine Systems of Florida LLC" 893 "KlinkTechnics Ltd." 892 "Mectronx Corp" 891 "CarrierWeb" 890 "L3 Technologies, Inc." 889 "SANY America Inc" 888 "Carma Systems Inc" 887 "Hyperdrive Innovation Limited" 886 "Hitachi Zosen Corporation" 885 "SICK Stegmann GmbH" 884 "Sure Grip Controls Inc." 883 "Swift Navigation, Inc." 882 "BHTronik GmbH & Co. KG" 881 "Sovema" 880 "Revision Military" 879 "PG Trionic, Inc." 878 "FOTON" 877 "SICK ATech GmbH" 876 "SUCO Robert Scheuffele GmbH & Co. KG" 875 "Salvarani S.r.l." 874 "MTA S.p.A." 873 "Garnet Instruments Ltd." 872 "Kählig Antriebstechnik GmbH" 871 "Superior Tech Inc" 870 "Textron Fleet Management" 869 "Intercomp" 868 "Data Panel Corp" 867 "Skeleton Technologies" 866 "Netradyne, Inc." 865 "MyEasyFarm" 864 "Streamline Transportation Technologies Inc." 863 "SMAG" 862 "Prospec Electronics" 861 "Adel System S.r.l." 860 "Michelin" 859 "Valor" 858 "Littelfuse" 857 "Zoomlion Heavy Industry NA, Inc" 856 "FarmFacts GmbH" 855 "Toshiba Infrastructure Systems & Solutions Corporation" 854 "GEMAC Chemnitz GmbH" 853 "Teledyne RESON B.V." 852 "Velvac Inc" 851 "Novotechnik Messwertaufnehmer OHG" 850 "Geoprospectors GmbH" 849 "MTS Maschinentechnik Schrode AG" 848 "ningupex" 847 "Oceanvolt" 846 "L3 Magnet-Motor" 845 "GMB Güstrower Maschinenbau GmbH" 844 "FELL AS" 843 "Hendrickson Truck Commercial Vehicle Systems" 842 "DigiDevice Srl" 841 "Agra-GPS" 840 "E.S.T.E. Srl" 839 "Indexator Rotator Systems AB" 838 "Teamsurv Ltd" 837 "Famic Technologies Inc." 836 "Signature4" 835 "PetTrack Ltd." 834 "Pioneer Microsystems, Inc." 833 "Electrum Automation AB" 832 "Heizomat Gerätebau-Energiesysteme GmbH" 831 "DOK-ING Ltd." 830 "Ultra Motion LLC" 829 "Drov Technologies, Inc." 828 "AgriBrink Inc." 827 "INmatix Technology Group Ltd" 826 "Lewmar Marine Inc" 825 "BPW Hungária" 824 "Undheim Systems AS" 823 "ACEINNA, Inc (formerly MEMSIC, Inc)" 822 "Bren-Tronics, Inc." 821 "Thorsen Teknik A/S" 820 "DIaLOGIKa Gesellschaft fuer angewandte Informatik mbH" 819 "Preco Electronics" 818 "HGNSS" 817 "TE Connectivity Sensor Solutions" 816 "UniStrong" 815 "FLIR Systems, Inc." 814 "Kronotech Srl (formerly Soltec Soluzioni Tecnologiche Srl)" 813 "Thales Suisse SA" 812 "Torch Technologies" 811 "Blue Water Desalination" 810 "Dutch Power Company" 809 "HMS Industrial Networks AB" 808 "RIMEX Supply Ltd." 807 "Schneider-Electric" 806 "Charge Automotive Ltd" 805 "Gundersen & Løken AS" 804 "ASA Electronics" 803 "Gill Sensors & Controls Limited" 802 "SPBI (Bj Technologie)" 801 "LOR Manufacturing Company Inc." 800 "Delta-Q Technologies" 799 "Stillwater Designs and Audio, Inc. - KICKER" 798 "Lumishore Ltd" 797 "Tides Marine" 796 "Canadian Automotive Industries Ltd" 795 "Broyda Enterprises Pty Ltd" 794 "Shihlin Electric & Engineering Corporation" 793 "James Fisher Prolec" 792 "Kostal Mexicana" 791 "AUTEC" 790 "VACALL" 789 "GRADALL" 788 "MoTeC Pty Ltd" 787 "Abertax Technologies Limited" 1863 "Thomas G. Faria Co." 1862 "Sanshin" 1861 "Vector North America" 1860 "MMP" 1859 "Kvasar AB" 1858 "Litton" 1857 "Simrad" 1856 "Trimble" 1855 "Furuno USA" 1854 "Northstar Technologies" 1853 "Japan Radio Co" 1852 "Navionics" 1851 "RayMarine" 1850 "Seastar Solutions (formerly Teleflex)" 786 "Johnson Matthey Battery Systems" 785 "Fischer Panda GmbH" 784 "CM Automotive Systems, Inc." 783 "Loup Electronics Inc." 782 "AVR bv (formerly AVR bvba)" 781 "Poly-Planar LLC" 780 "AVID Technology Ltd" 779 "RLC Electronic Systems" 778 "Seakeeper Inc." 777 "Ocean Signal Ltd" 776 "HMI Systems LLC" 775 "ZIEHL-ABEGG Automotive GmbH" 774 "Taisho Corporation" 773 "Clarion Corporation of America" 772 "Blink Marine" 771 "Shaw Development, LLC" 770 "MONOSEM" 769 "Trombetta" 768 "Flores Automation, LLC" 767 "Alliance Wireless Technologies Inc." 766 "Epec Oy" 765 "GIGAVAC" 764 "Bednar FMT s.r.o." 763 "AT-Systems BVBA" 762 "ROJ s.r.l." 761 "MITA OLEODINAMICA S.p.A." 760 "Bernecker + Rainer Industrie Elektronik GmbH" 759 "Hydro-Gear" 758 "Banner Engineering Corp." 757 "IMPCO Technologies" 756 "Maschio Gaspardo S.P.A." 755 "Firefly Integrations" 754 "Parker Hannifin Corp., Automation Group" 753 "AIROD Technologies" 752 "Deep Sea Electronics Plc" 751 "Pacific Track" 750 "Joskin SA" 749 "Chart Inc." 748 "ISOTTA" 747 "Agratronix" 746 "SureFire Ag Systems, Inc." 745 "Cidra Corporate Services Inc." 744 "Woosung Engineering Co., Ltd." 743 "Daemyung Elevator Co., Ltd." 742 "EROAD" 741 "Carling Technologies" 740 "e-Traction" 739 "LXNAV d.o.o." 738 "Blue Ink Technologies" 737 "Balluff GmbH" 736 "Terex Aerial Work Platforms - Genie" 735 "AEM Performance Electronics" 734 "REAPsystems" 733 "Intendia S.L." 732 "Gefran S.p.A." 731 "Modine Manufacturing Company" 730 "BERTHOUD AGRICOLE" 729 "Liebherr" 728 "Streumaster (formerly Streumaster / Panien)" 727 "Dhoot Transmission Pvt Ltd." 726 "MIDORI PRECISIONS" 725 "Hitachi Construction Machinery Co., Ltd." 724 "Electronic Applications, Inc." 723 "Jabil Inc." 722 "Contelec AG" 721 "Hypro" 720 "WITZ Corporation" 719 "Cojali S. L." 718 "Micronet Inc" 717 "Yacht Devices Ltd" 716 "Eaton Control & Power Conversion Division (CPCD)" 715 "Autonnic Research Ltd" 714 "Kobashi Kogyo Co., Ltd." 713 "US Hybrid Corporation" 712 "LOR Manufacturing Company Inc." 711 "DAS Co., LTD" 710 "Greentronics Ltd." 709 "Marquardt GmbH" 708 "Lars Thrane A/S" 707 "Rochester Gauges Inc" 706 "Shanghai Diesel Engine Corporation Limited" 705 "SVAB Hydraulik AB" 704 "JL Audio, Inc." 703 "Hydro Tab Marine Engineering" 702 "Weichai Power Co., Ltd." 701 "BigRoad Inc." 700 "K-Tec Earthmovers Inc." 699 "Harman International Industries" 698 "Scorpion Technologies Ltd." 697 "Ålö AB" 696 "DRS Network & Imaging Systems, LLC (DRS Technologies)" 695 "Weldon Technologies" 694 "GasTOPS Ltd." 693 "Agility Fuel Solutions (formerly Agility Fuel Systems)" 692 "Tanhay Corporation" 691 "Digitroll Agricultural Electronics" 690 "LINAK A/S" 689 "Aarcomm Systems Inc" 688 "Rockford Corp" 687 "Flight Systems, Inc." 686 "Taigene Electric Machinery Corp." 685 "ANEDO (formerly ANEDO Ltd.)" 684 "KEB" 683 "Fosen Elektro" 682 "Eckelmann AG" 681 "BEDIA Motorentechnik GmbH & Co. KG" 680 "AMVAC Chemical Corporation" 679 "Cimco Marine AB" 678 "KeepTruckin, Inc." 677 "DSA Daten- und Systemtechnik GmbH" 676 "Danfoss IXA A/S" 675 "Kawasaki Motors Corp., USA" 674 "Yara International ASA" 673 "Caruelle Nicolas" 672 "OPTIMA Concept" 671 "Innovative Controls Inc." 670 "STEMCO LP" 669 "Quantum Fuel Systems Technologies Worldwide, Inc" 668 "MacDon Industries Ltd." 667 "Bartec" 666 "Schaeffler Technologies AG & Co., KG" 665 "Gebr. Bode GmbH & Co. KG" 664 "Level Developments Ltd" 663 "Delta Systems, Inc" 662 "Kissling Elektrotechnik GmbH" 661 "SPAL Automotive S.r.l." 660 "Auto-Gaz Centrum" 659 "Data Panel Corp." 658 "Shenzhen Jiuzhou Himunication Technology Co., Ltd" 657 "Terzo Power Systems" 656 "PRO SOLUS do Brasil" 655 "Genge & Thoma AG" 654 "Kohler Power Systems, Detroit Engine Development Center (DEDC)" 653 "AEV, spol. s r. o." 652 "MicroControl GmbH & Co. KG" 651 "Takakita Co, Ltd." 650 "Seiko Epson Corp." 649 "Control-Q B.V." 648 "OJSC Ekran" 647 "Siloking" 646 "Veenhuis Machines B.V." 645 "esd electronic system design gmbh" 644 "KUS USA" 643 "Bogballe A/S" 642 "Moog / Aspen Motion Technologies" 641 "Diverse Yacht Services" 640 "Power Solutions International" 639 "Startec s.r.l." 638 "KVH Industries, Inc." 637 "Bavaria Yachtbau GmbH" 636 "Divelbiss Corporation" 635 "Argo Tractors S.p.A." 634 "Rocky Research" 633 "TORC Robotics" 632 "Pepperl+Fuchs GmbH" 631 "Reltima" 630 "SmartDrive Systems Inc." 629 "Agri Info Design, Ltd." 524 "Vomax Instrumentation Pty. Ltd." 523 "Reggio Emilia Innovazione" 522 "Nebraska Tractor Test Laboratory" 521 "Clever Devices Ltd." 520 "Trapeze" 519 "Peeters Landbouwmachines b.v." 518 "Transas USA Inc." 517 "Noland Engineering" 516 "AVAT Automation GmbH" 515 "GINAF Trucks Nederland B.V." 514 "DISTek Integration, Inc." 513 "Precision Technology (Formerly FarmscanAg)" 512 "Inpower LLC" 511 "Sulky" 510 "Marinesoft Co. Ltd" 509 "MOTORTECH GmbH" 508 "Transtech Innovations" 507 "ISOBUS Test Center" 506 "IHI STAR Machinery Corporation" 505 "Yetter Farm Equipment" 504 "Vesper Marine" 503 "Naviop S.R.L." 502 "Attwood Corporation" 501 "Agrotronix S.A." 500 "Oxbo International Corporation" 499 "LCJ Capteurs" 498 "Innovative Design Solutions, Inc." 497 "SENTRON Sistemas Embarcados" 496 "W. Gessmann GmbH" 495 "HOLMER Maschinenbau GmbH" 494 "Synerject" 493 "Watcheye" 492 "Inergy Automotive Systems" 491 "Penny and Giles Ltd" 490 "QuikQ" 489 "Appareo Systems, LLC" 488 "The Charles Machine Works, Inc." 487 "DSE Test Solutions A/S" 486 "Westport Innovations Inc." 485 "MATT automotive" 484 "Headsight Inc." 483 "Valeo" 482 "Tricon Electronics" 481 "Chetco Digital Instruments" 480 "EnerDel, Inc." 479 "Vapor Bus International" 478 "OceanSat B.V." 477 "OilQuick AB" 476 "Hummingbird Marine Electronics" 475 "GME" 474 "Persen Technologies Inc." 473 "Boss Industries, Inc." 472 "Tenneco Inc." 471 "Sea Cross Marine AB" 628 "Falck Schmidt Defence Systems" 627 "Radio Ocean" 626 "AVL DiTEST GmbH" 625 "Global MRV Inc." 624 "Blackbox Machine Control Pty Ltd" 623 "Xirgo Technologies" 622 "Floyd Bell Inc" 621 "Hagie Manufacturing Company" 620 "Sevcon Ltd." 619 "Right Weigh Load Scales" 618 "Evrard SA" 617 "Zero Emission Vehicles" 616 "SMART-TEC s.r.o." 615 "Networkfleet, Verizon Telematics" 614 "ARLT Technologies GmbH" 613 "HKS Co., Ltd." 612 "Samwon IT" 611 "Esterline" 610 "Trail Tech" 609 "Walvoil S.p.A." 608 "Gale Banks Engineering" 607 "Knappco/Civacon" 606 "Intellian Technologies" 605 "Aventics GmbH" 604 "Indexator Rototilt Systems AB" 603 "Kereval" 602 "Nomad Digital Ltd." 601 "Navitas Systems" 600 "Aquatic AV" 599 "Spudnik Equipment Co, LLC" 598 "ABB Turbo Systems Ltd" 597 "Hydac Filter Systems GmbH" 596 "Brunelco Electronic Innovators B.V." 595 "CustomWare" 594 "Kongsberg Automotive" 593 "Sensata Technologies" 592 "tecsis GmbH" 591 "United States Coast Guard" 590 "ARGO-HYTOS GMBH" 589 "MICO, Inc." 588 "Vignal Systems" 587 "JCA Electronics" 586 "Suzuki Motor Corp" 585 "Industrial Electronic Controls" 584 "CarMedialab GmbH" 583 "Yachtcontrol" 582 "Innovative Software Engineering" 581 "Väderstad - Verken AB" 580 "San Jose Technology, Inc." 579 "KVH Industries, Inc." 578 "advanSea" 577 "Denchi Power Ltd  (formerly ABSL Power Solutions Limited)" 576 "Vectia" 575 "Lytx" 574 "Vishay Precision Group" 573 "Orolia Ltd" 572 "Fasse Valves" 571 "Marinecraft Co., Ltd." 570 "frenzel + berg electronic GmbH & Co. KG" 569 "LORD MicroStrain Sensing Systems" 568 "Makersan Ltd. Co." 567 "Lithiumstart LLC" 566 "Geode Technology, Inc." 565 "Micro-Trak Systems, Inc." 564 "Auto Power Electronic" 563 "LOHR Sistemas Eletronicos LTDA" 562 "Bombardier Transportation GmbH" 561 "b-plus GmbH" 560 "Iowa State University, Agricultural and Biosystems Engineering" 559 "Four Peaks Navigation" 558 "Davis Instruments Corp." 557 "Rockson Automation GmbH" 556 "Doosan Infracore Norway" 555 "Sasaki Corporation" 554 "iris-GmbH infrared & intelligent sensors" 553 "KIB Electronics" 552 "Matsuyama Plow Mfg Co, Ltd" 551 "Wexler CSD Ltd." 550 "SUN-A Corporation" 549 "ROAD Deutschland GmbH" 548 "TM4 Inc." 547 "Thomson Linear LLC" 546 "Maruyama Mfg Co, Inc." 545 "GS Hydraulics" 544 "Au Group Electronics" 543 "BAUER Maschinen GmbH" 542 "Dinamica Generale s.p.a." 541 "Total Fire Systems, Inc." 540 "Dinex A/S" 539 "Mobileview" 538 "Crop Ventures, Inc." 537 "Schrader Electronics Ltd." 536 "SSI Technologies" 535 "MOTORPAL, a.s." 534 "Webasto Thermo & Comfort SE" 533 "Doran Manufacturing, LLC" 532 "Onwa Marine Electronics Co Ltd." 531 "Genge & Thoma AG" 530 "NMEA" 529 "National Instruments Korea" 528 "Hoganas AB, Electric Drive Systems" 527 "GKN Walterscheid GmbH" 526 "LOFA Industries, Inc" 525 "Rust Sales INC" 470 "SI-TEX Marine Electronics" 469 "RA Consulting GmbH" 468 "Tyco Fire Protection Products" 467 "Lely Industries N.V." 466 "Veethree Electronics and Marine LLC" 465 "Ashcroft Inc" 464 "Leach International Corporation" 463 "PROBOTIQ" 462 "IHI Shibaura Machinery Corporation" 461 "HAWE Hydraulik SE" 460 "San Giorgio S.E.I.N." 459 "Alltek Marine Electronics Corp" 458 "Control Solutions, Inc." 457 "RUSELPROM-ElectricDrive Ltd" 456 "General Kinetics" 455 "ADZ NAGANO GmbH" 454 "NGK Spark Plug Co. Ltd" 453 "Cooper Bussmann" 452 "WIKA Alexander Wiegand SE & Co. KG" 451 "Parker Hannifin Corp" 450 "Dycor Technologies Ltd." 449 "Polaris Industries Inc" 448 "Stanadyne Corporation, Electronics Systems" 447 "Great Plains Mfg." 446 "CertTech, L.L.C." 445 "KAT MECHATRONIC, Electronic Product Division" 444 "ITT Power Solutions" 443 "SignalQuest, Inc." 442 "Horsch Maschinen GmbH" 441 "PTG Reifendruckregelsysteme GmbH" 440 "Cummins Power Generation" 439 "Hyundai Heavy Industries" 438 "Comar Systems Ltd" 437 "Digital Yacht Limited" 436 "Kinze Manufacturing" 435 "Zunhammer GmbH" 434 "Stored Energy Systems" 433 "Rowe Electronics" 432 "S&A Systems, Inc." 431 "Tohatsu Corporation" 430 "Auteq Telematica S.A." 429 "Rota Engineering Ltd." 425 "Methode Electronics Inc, MDI" 424 "Odyne LLC" 423 "BSM Wireless, Inc." 422 "True Heading AB" 421 "Vertex Standard Co, Ltd" 420 "Vermeer Corporation, ACS Group" 419 "Fusion Electronics Ltd" 418 "Intellistick Inc" 417 "KZValve" 416 "Kubota Corporation" 415 "Valid Manufacturing Ltd." 414 "Cattron Group International" 413 "Datapross Nijbroek bv" 412 "WebTech Wireless Inc." 411 "Hy-Drive Technologies Ltd." 410 "COBO S.p.A. Divisione 3B6" 409 "Transfluid S.r.L." 408 "Corvus Energy Ltd." 407 "Comtech Mobile Datacom" 406 "Vecima Networks Inc." 405 "Wema System AS" 404 "Com Nav Marine Ltd" 403 "Trackwell ADS, Inc." 402 "Simma Software, Inc." 401 "Torqeedo GmbH" 400 "Livorsi Marine" 399 "ISEKI & Co., Ltd." 398 "Hilite International" 397 "Sanyo-kiki Co Ltd." 396 "Beyond Measure" 395 "GENTEC S.R.L." 394 "Capi 2 Nederland B.V." 393 "Harvest Tec, Inc" 392 "Tianyuan Technology Co Ltd." 391 "Electronic Design for Industry, Inc" 390 "Partech Inc." 389 "Benchmark Electronics, Minnesota Division" 388 "Innomatix, LLC" 387 "Orscheln Products, LLC" 386 "JLG Automation BVBA" 385 "Johnson Outdoor Marine Electronics" 384 "Camano Light" 383 "MCL Industries" 382 "National Agriculture and Food Research Organization" 381 "B & G" 380 "Suntech International Ltd." 379 "Yamabiko Corporation" 378 "Glendinning Marine Products" 377 "ifm electronic gmbh" 376 "Quake Global" 375 "Williams Controls Inc." 374 "Northern Lights, Inc." 373 "Electronic Design Inc." 372 "Delphi" 371 "Heinzmann GmbH & Co. KG" 370 "Rolls-Royce Marine AS" 369 "Power Torque Engineering Ltd" 368 "HANSENHOF_electronic" 367 "Fliegl Agrartechnik" 366 "Viewnyx Corp." 365 "Digi-Star, LLC" 364 "OEM Controls Inc." 363 "BEI Duncan" 362 "Poettinger Landtechnik GmbH (formerly Alois Poettinger Maschinenfabrik GmbH)" 361 "InMach" 360 "HJS Emission Technology GmbH & Co KG   (formerly HJS Fahrzeugtechnik GmbH & Co KG)" 359 "Ludwig Bergmann GmbH" 358 "Victron Energy B.V." 357 "Hardi International A/S" 356 "Fischer Panda Generators, Inc" 355 "Mastervolt International B.V." 354 "Junkkari OY" 353 "Hegemon Electronics, Inc." 352 "SAME DEUTZ-FAHR GROUP S.p.A." 351 "Thrane & Thrane" 350 "Noris Marine Systems GmbH & Co KG" 349 "Suonentieto" 348 "Amazonen Werke H. Dreyer" 347 "Honeywell" 346 "Control Solutions" 345 "Korean Maritime University" 344 "Parvus Corporation" 343 "Baumer Group" 342 "THOMAS MAGNETE GmbH" 341 "Boning GmbH & Co" 340 "Continental AG" 339 "Competence Center ISOBUS e.V." 338 "GRAF-SYTECO" 337 "Carraro S.p.A." 336 "APE s.r.o." 335 "Evo Electric Ltd" 334 "Takata-Petri AG" 333 "Hadley Products Corporation" 332 "HWH Corporation" 331 "Horton, Inc." 330 "Kidde Aerospace and Defense" 329 "Deif A/S" 328 "Qwerty Electronik AB" 327 "Sonceboz SA" 326 "Akron Brass Company" 325 "ASM Automation Sensorik Messtechnik GmbH" 324 "Snap-on Diagnostics" 323 "Mobileye Vision Technologies Ltd." 322 "MICHENKA s.r.o." 321 "Ultra Electronics, Electrics" 320 "Miedema Landbouwwerktuigenfabriek B.V." 319 "Cadec Global" 318 "SAT Plan" 317 "Navtronics Bvba" 263 "IMMI" 262 "HydraForce, Inc" 261 "Red Dot Corporation" 260 "Reichhardt GmbH Steuerungstechnik" 259 "Jetter AG" 258 "ARAG" 257 "Honda Motor Co., Ltd" 256 "Tyco Electronics AMP" 255 "MEAS France" 254 "GE Sensing" 253 "Mobile Control Systems" 252 "Sensor-Technik Wiedemann GmbH" 251 "German Agricultural Society, Test Center (DLG)" 250 "Kuhn Group" 249 "Schaltbau GmbH" 248 "Cooper Standard Automotive Active Systems Group" 247 "ePULSE" 246 "Class 1, Inc" 245 "Capstan Ag Systems, Inc." 244 "Techno-Matic" 243 "eRide, Inc." 242 "Kokusandenki Co. Ltd" 241 "Schneider Automation SAS" 240 "Vanair Mfg" 239 "May & Scofield Ltd" 238 "ZF Friedrichshafen AG" 237 "Agtron Enterprises Inc" 236 "NORAC Systems International Inc" 235 "SailorMade Marine Telemetry - Tetra Technology Ltd." 234 "Mondial electronic GmbH" 233 "Yacht Monitoring Solutions Inc." 232 "TSD Integrated Controls" 231 "Topcon Positioning Systems, Inc." 230 "Saucon Technologies" 229 "Garmin International Inc." 228 "Unused (formerly ZF Marine Electronics)" 227 "Lykketronic A/S" 226 "Monaco Coach Corporation" 225 "SKF" 224 "EMMI Network, S.L." 223 "Vaueo Retarder Co., Ltd." 222 "Generac Power Systems, Inc." 221 "SiE" 220 "Beede Electrical Instrument Company, Inc" 219 "Cat OEM Solutions" 218 "Gits Manufacturing Company" 217 "RM Michaelides Software & Elektronik GmbH" 216 "Paneltronics Inc." 215 "Aetna Engineering/Fireboy-Xintex" 214 "MC elettronica Srl" 164 "MTU Friedrichshafen GmbH (formerly DaimlerChrysler Off-Highway)" 163 "BRP Inc." 162 "Axiomatic Technologies" 161 "Offshore Systems (UK) Ltd" 160 "Nido" 159 "NTech Industries Inc" 158 "Firestone Industrial Products Company" 157 "ISSPRO Inc." 156 "ITT Industries - Cannon" 155 "Vetronix Corporation" 154 "Westerbeke Corporation" 153 "Woodward, Industrial Controls Division" 152 "elobau GmbH & Co. KG" 151 "Raven Industries, Inc." 150 "Fleetguard" 149 "Holset" 148 "Blue Water Data, Inc." 147 "Nautibus electronic GmbH" 146 "Maxima Technologies" 145 "MurCal Controls" 144 "Mercury Marine" 143 "W. Gmeiner GmbH & Co." 142 "TRW Automotive (Commercial Steering Systems)" 141 "Thales Navigation Ltd." 140 "Lowrance Electronics, Inc." 139 "Caterpillar Trimble Control Technologies (CTCT), LLC" 138 "Georg Fritzmeier GmbH & Co. KG" 137 "Maretron" 136 "Komatsu Ltd" 135 "Airmar Technology Corporation" 134 "Iris Technology Ltd" 133 "Bucher Schoerling GmbH" 132 "Mulag-Fahrzeugwerk" 131 "ITT Industries" 130 "Nido - Universal Machines B.V." 129 "OMNEX Control Systems Inc." 128 "Gerhard Duecker GmbH & Co. KG" 127 "Holland USA" 126 "Driver Tech" 125 "Nevada Automotive Test Center" 124 "Hydac Electronic" 123 "Basler Electric" 122 "FG Wilson (Engineering) Limited" 121 "HED (Hydro Electronic Devices, Inc.)" 120 "RDS Technology Ltd" 119 "IntegriNautics  " 118 "Intron GmbH" 117 "HUSCO International" 116 "BEELINE Technologies" 115 "NACCO Materials Handling Group, Inc." 114 "EControls, Inc." 113 "Stress-Tek, Inc." 112 "MECALAC" 111 "Bernard Krone Holding SE & Co. KG (formerly Maschinenfabrik Bernard Krone GmbH)" 110 "EPIQ Sensor-Nite" 109 "TeeJet Technologies Denmark (formerly LH Technologies ApS)" 108 "WTK-Elecktronik GmbH" 107 "Grimme Landmaschinen GmbH & Co. KG" 106 "BAE Systems Controls, Inc." 105 "Kiepe Elektrik GmbH & Co. KG" 104 "CLAAS KGaA mbH (formerly CLAAS Selbstfahrende Erntemaschinen GmbH)" 103 "CLAAS E-Systems GmbH (formerly CLAAS E-Systems KGaA mbH & Co. KG)" 102 "AGCO (formerly AGCO GmbH & Co.)" 101 "Sensoria" 100 "VDO Technik AG" 99 "International Transmissions Ltd (ITL)" 98 "Mueller-Elektronik GmbH & Co" 97 "Ag Leader Technology, Inc." 96 "Mech@tronic IT GmbH" 95 "Pacific Insight Electronics Corp." 94 "CNH Industrial N.V. (formerly CNH Global N.V.)" 93 "Perkins Engines Company Ltd." 92 "Ag-Chem Equipment Co., Inc." 91 "BSG Bodensee Steuergeraete GmbH" 90 "Knorr-Bremse SfN GmbH" 89 "Kverneland Group, Electronics Division" 88 "Hemisphere GPS Inc (formerly Satloc Precision GPS)" 87 "J.C. Bamford Excavators Ltd (JCB)" 86 "C. E. Niehoff & Company" 85 "Kohler Co" 84 "New Holland UK Limited" 83 "Bendix VORAD Technologies (formerly Eaton VORAD Technologies)" 82 "Bobcat/Ingersoll-Rand (formerly Melroe/Ingersoll-Rand)" 81 "Fire Research Corp." 80 "Twin Disc, Inc." 79 "Daimler Benz AG - Engine Division (PBM)" 78 "Frank W. Murphy Manufacturing, Inc" 77 "Deere Power Systems Group" 76 "unused (formerly Deere & Co, Construction Division)" 75 "Deere & Co, Agricultural Division" 74 "Eaton Axle-Brake Division" 73 "LeTourneau, Inc." 72 "Sisu Corporation" 71 "Vansco Electronics Ltd." 70 "Flex-coil Limited" 69 "Trimble Navigation" 316 "ITT Flow Control" 315 "Icom Incorporated" 314 "CSM GmbH" 313 "Ilmor Engineering, Inc." 312 "Lectronix, Inc." 311 "Patrick Power Products" 310 "TECNORD srl" 309 "Krauss-Maffei Wegmann GmbH & Co. KG" 308 "Cyntrx" 307 "MAS Technologies" 306 "Sleipner Motor AB" 305 "NovAtel Inc" 304 "EmpirBus AB" 303 "CTS Corporation" 302 "Nissin Kogyo Co., LTD" 301 "Parker Hannifin (UK) Ltd FDE group" 300 "Systron Donner Automotive" 299 "Rauch" 298 "Holley Performance" 297 "Zonar Systems Inc" 296 "micro dynamics GmbH" 295 "BEP Marine" 294 "Grayhill Inc." 293 "Spyder Controls Corp." 292 "IKUSI - Angel Iglesias S.A." 291 "Groeneveld Transport Efficiency BV" 290 "Kuebler GmbH" 289 "Watlow" 288 "Mitsubishi FUSO Truck & Bus Corp." 287 "NTech Industries, Inc" 286 "Coelmo srl" 285 "Sea Recovery Corp" 284 "Mobile Tech Chile" 283 "CWF Hamilton & Co Ltd" 282 "Medallion Instrumentation Systems" 281 "Precision Governors LLC" 280 "Leica Geosystems Pty Ltd" 279 "Geometris LP" 278 "Takata Electronics" 277 "LHP Telematics" 276 "Aqua-Hot Heating Systems" 275 "Navico Egersund AS" 274 "LTW Technology Co., LTD" 273 "Active Research Limited" 272 "Gross Mechanical Laboratories, Inc" 271 "Cole Hersee" 270 "Tennant" 269 "Saft America Inc.,  Space & Defense Division" 268 "Accurate Technologies" 267 "Red Lion Controls, Inc" 266 "International Thermal Research Ltd" 265 "MTS Sensor Technologie GmbH" 264 "Autolync" 213 "CNH Belgium N.V." 212 "Sure Power Industries, Inc" 211 "DNA Group" 210 "Iteris, Inc." 209 "Bell Equip. Co. SA (PTY) LTD" 208 "Drew Technologies, Inc" 207 "Otto Engineering" 206 "port GmbH" 205 "SmarTire Systems Inc" 204 "The Morey Corporation" 203 "MILtronik GmbH" 202 "Curtis Instruments, Inc" 201 "Disenos y Tecnologia S.A." 200 "MGM Brakes" 199 "ACTIA Group (formerly Actia Corp)" 198 "Mystic Valley Communications" 197 "Mechron Power Systems" 196 "LEMKEN GmbH & Co KG" 195 "General Engine Products" 194 "TriMark Corporation" 193 "Jeppesen Marine" 192 "Floscan" 191 "XRS Corporation (formerly XATA Corporation)" 190 "Hella KGaA Hueck & Co" 189 "QUALCOMM" 188 "EMP Corp" 187 "Air-Weigh" 186 "Altronic, Inc" 185 "Beede Electrical Instrument Company" 184 "EIA Electronics" 183 "KDS Controls, Inc" 182 "Vehicle Systems Engineering B.V." 181 "Coretronics, Inc." 180 "Smart Power Systems" 179 "TeeJet Technologies Springfield (formerly Midwest Technologies Illinois, LLC)" 178 "Continental Automotive GmbH (formerly Siemens VDO Automotive AG)" 177 "Diagnostic Systems Associates" 176 "Moritz Aerospace" 175 "Veris Technologies, Inc." 174 "AB Volvo Penta" 173 "Ryeso, Inc." 172 "Yanmar Co., Ltd. (formerly Yanmar Marine USA)" 171 "Topcon Electronics GmbH & Co. KG (formerly Wachendorff Elektronik GmbH & Co. KG)" 170 "Computronics Corporation Ltd." 169 "Marlin Technologies Inc." 168 "Xantrex" 167 "JLG Industries Inc" 166 "John Deere Electronic Solutions (formerly Phoenix International)" 165 "CPAC Systems AB" 68 "Scania" 67 "John Deere Coffeyville Works (formerly Funk Manufacturing Company)" 66 "John Deere Construction Equipment Division" 65 "MAN Nutzfahrzeuge AG" 64 "Unused (formerly SpectraPrecision Laserplane, then SpectraPhysics)" 63 "ZF Industries Inc." 62 "Wabco" 61 "Volvo Truck Corp." 60 "Volvo Trucks North America Inc." 59 "VES Inc." 58 "SPX Corporation, OTC Div" 57 "Danfoss  (formerly Sauer Sundstrand Co, then Sauer-Danfoss Co)" 56 "SAIC" 55 "Ryder System Inc." 54 "Meritor Wabco" 53 "Continental Automotive Systems US, Inc. (formerly Rockwell Land Transportation)" 52 "Meritor Automotive, Inc. (formerly Rockwell Automotive)" 51 "Robert Bosch GmbH" 50 "Robert Bosch Corp" 49 "RE America Inc." 48 "Pollak Alphabet" 47 "Phillips Semiconductor" 46 "Noregon Systems, Inc  (formerly Parasoft Computing Solutions)" 45 "PACCAR" 44 "Nippondenso Co. Ltd." 43 "International Truck and Engine Corporation - Vehicle Electronics (formerly Navistar Intl Trans Corp.)" 42 "International Truck and Engine Corporation - Engine Electronics  (formerly Navistar Intl Trans Co., Engine Electronics)" 41 "Motorola Inc." 40 "Motorola AIEG Inc." 39 "Microfirm Inc." 38 "Micro Processor Systems Inc." 37 "Mack Trucks Inc." 36 "Lucas Ind." 35 "Kenworth Truck Co." 34 "Kelsey Hayes Co." 33 "John Deere" 32 "Jacobs Vehicle Systems" 31 "J Pollak Corp" 30 "Isuzu Motors Ltd" 29 "Hino Motors Ltd." 28 "Grote Ind. Inc." 27 "GMC" 26 "General Motors Corp, Service Technology Grp" 25 "Daimler Trucks North America LLC (formerly Freightliner LLC)" 24 "Ford Motor Co., Vehicle Controls" 23 "Ford Motor Co., Heavy Truck" 22 "Ford Motor Co., Electronic Concepts & Systems" 21 "Echlin Inc., Midland Brake Inc." 20 "Eaton Ltd" 19 "Eaton Corp. Trucking Info Services" 18 "Eaton Corp, Transmission Div." 17 "Eaton Corp, Corp Res & Dev" 16 "Eaton Corp" 15 "DICKEY-john Corporation" 14 "Detroit Diesel Corporation" 13 "Delco Electronics" 12 "Deere & Company, Precision Farming" 11 "Dearborn Group Inc." 10 "Cummins Inc (formerly Cummins Engine Co)" 9 "Chrysler Corp." 8 "Caterpillar Inc." 7 "Case Corp." 6 "Berifors Electronics AB" 5 "AMP Inc." 4 "Ametek-Dixson" 3 "Ametek, US Gauge Division" 2 "Allison Transmission, Inc." 1 "Bendix Commercial Vehicle Systems LLC (formerly Allied Signal Inc.)" 0 "Reserved" ;
VAL_ 2566734590 CertLaboratoryType_FirstDef 7 "Not available (not certified) " 0 "Non-certified laboratory/self-test" 1 "AEF certified laboratory " 2 "Reserved " ;
VAL_ 2566734590 MessageRevision 1 "Third and later edition message revision" 0 "Format of message in second edition." ;
VAL_ 2566734590 CertificationReferenceNumber 0 "NotCertified" 1 "CertificationTestPerformed" ;
VAL_ 2566734590 CertTypeTaskController 0 "NotCertified" 1 "CertificationTestPerformed" ;
VAL_ 2566734590 CertTypeTCWorkingSetMaster 0 "NotCertified" 1 "CertificationTestPerformed" ;
VAL_ 2566734590 CertTypeTCWorkingSetMember 0 "NotCertified" 1 "CertificationTestPerformed" ;
VAL_ 2566734590 CertTypeFileServer 0 "NotCertified" 1 "CertificationTestPerformed" ;
VAL_ 2566734590 CertTypeGPSReceiver 0 "NotCertified" 1 "CertificationTestPerformed" ;
VAL_ 2566734590 CertTypeMinimumECU 0 "NotCertified" 1 "CertificationTestPerformed" ;
VAL_ 2566734590 CertTypeTECUClass1 0 "NotCertified" 1 "CertificationTestPerformed" ;
VAL_ 2566734590 CertTypeTECUClass2 0 "NotCertified" 1 "CertificationTestPerformed" ;
VAL_ 2566734590 CertTypeTECUClass3 0 "NotCertified" 1 "CertificationTestPerformed" ;
VAL_ 2566734590 CertTypeClass3ECU 0 "NotCertified" 1 "CertificationTestPerformed" ;
VAL_ 2566734590 CertTypeVirtualTerminal 0 "NotCertified" 1 "CertificationTestPerformed" ;
VAL_ 2566734590 CertTypeVTWorkingSetMaster 0 "NotCertified" 1 "CertificationTestPerformed" ;
VAL_ 2566734590 CertTypeVTWorkingSetMember 0 "NotCertified" 1 "CertificationTestPerformed" ;
VAL_ 2566734590 CertLaboratoryType_SecondDef 3 "Not available (not certified) " 0 "Non-certified Laboratory/self-certification" 1 "AEF certified laboratory " 2 "Reserved " ;
VAL_ 2566734590 TestProtocolRevision 0 "FirstRevision" 1 "SecondRevision" 2 "ThirdRevision" 3 "NotAvailable" ;
SG_MUL_VAL_ 2619670270 TIMMessageType GroupFunctionValue 1-32, 64-68, 70-70;
SG_MUL_VAL_ 2619604734 ReflectedRequestCounter GroupFunctionValue 1-32, 64-68, 70-70;
SG_MUL_VAL_ 2619604734 TIMMessageType GroupFunctionValue 1-32, 64-68, 70-70;
